VERSION "BodyCAN"

NS_ :

BS_:

BU_: CCM CEM DDM ETC ILCM PDM POT RLDM RRDM SMD SMP TRM Vector_XXX

BO_ 112 RldmBodyFr01: 8 RLDM
 SG_ ChdLockLeftSts : 6|2@0+ (1,0) [0|3] ""  CEM,DDM
 SG_ ChdLockLeftSts_UB : 7|1@0+ (1,0) [0|1] ""  CEM,DDM
 SG_ DoorLeReCinhIntFailInf_UB : 33|1@0+ (1,0) [0|1] ""  CEM
 SG_ DoorLeReCinhIntFailInfCinchFlt1 : 35|1@0+ (1,0) [0|1] ""  CEM
 SG_ DoorLeReCinhIntFailInfCinchRestF : 34|1@0+ (1,0) [0|1] ""  CEM
 SG_ DoorLeReHndlHMISts_UB : 48|1@0+ (1,0) [0|1] ""  CEM
 SG_ DoorLeReHndlHMIStsDeployedOverTm : 63|1@0+ (1,0) [0|1] ""  CEM
 SG_ DoorLeReHndlHMIStsReserved1 : 62|1@0+ (1,0) [0|1] ""  CEM
 SG_ DoorLeReHndlHMIStsRetractOverTmd : 61|1@0+ (1,0) [0|1] ""  CEM
 SG_ DoorLeReHndlHMIStsUnsScsHallSnsr : 60|1@0+ (1,0) [0|1] ""  CEM
 SG_ DoorLeReHndlSts : 2|3@0+ (1,0) [0|7] ""  CEM
 SG_ DoorLeReHndlSts_UB : 26|1@0+ (1,0) [0|1] ""  CEM
 SG_ DoorLeReLatPawlSt : 43|2@0+ (1,0) [0|3] ""  CEM
 SG_ DoorLeReLatPawlSt_UB : 55|1@0+ (1,0) [0|1] ""  CEM
 SG_ DoorLeReLatPosn : 37|2@0+ (1,0) [0|3] ""  CEM
 SG_ DoorLeReLatPosn_UB : 24|1@0+ (1,0) [0|1] ""  CEM
 SG_ DoorLeReLockSts : 17|2@0+ (1,0) [0|3] ""  CEM,DDM
 SG_ DoorLeReLockSts_UB : 18|1@0+ (1,0) [0|1] ""  CEM,DDM
 SG_ DoorLeReOpenLowReqOutdSwt1 : 41|2@0+ (1,0) [0|3] ""  CEM
 SG_ DoorLeReOpenLowReqOutdSwt1_UB : 45|1@0+ (1,0) [0|1] ""  CEM
 SG_ DoorLeReOpenReqInsdSwt1 : 39|2@0+ (1,0) [0|3] ""  CEM
 SG_ DoorLeReOpenReqInsdSwt1_UB : 31|1@0+ (1,0) [0|1] ""  CEM
 SG_ DoorLeReRelsFail_UB : 59|1@0+ (1,0) [0|1] ""  CEM
 SG_ DoorLeReRelsFailCinchOverTimed : 58|1@0+ (1,0) [0|1] ""  CEM
 SG_ DoorLeReRelsFailFailure1 : 57|1@0+ (1,0) [0|1] ""  CEM
 SG_ DoorLeReRelsFailMechRels : 56|1@0+ (1,0) [0|1] ""  CEM
 SG_ DoorLeReSwtLockgSts : 14|1@0+ (1,0) [0|1] ""  CEM,DDM
 SG_ DoorLeReSwtLockgSts_UB : 15|1@0+ (1,0) [0|1] ""  CEM,DDM
 SG_ DoorRiRe2Swt1DplyHndl : 54|1@0+ (1,0) [0|1] ""  RRDM
 SG_ DoorRiRe2Swt1DplyHndl_UB : 53|1@0+ (1,0) [0|1] ""  RRDM
 SG_ DoorRiRe2Swt2DplyHndl : 52|1@0+ (1,0) [0|1] ""  RRDM
 SG_ DoorRiRe2Swt2DplyHndl_UB : 51|1@0+ (1,0) [0|1] ""  RRDM
 SG_ PassSeatRemCtrlReDoorLe_UB : 19|1@0+ (1,0) [0|1] ""  SMP
 SG_ PassSeatRemCtrlReDoorLeActrIncSt : 23|2@0+ (1,0) [0|3] ""  SMP
 SG_ PassSeatRemCtrlReDoorLeActrSldSt : 21|2@0+ (1,0) [0|3] ""  SMP
 SG_ ShortDropWinReLeSts : 47|2@0+ (1,0) [0|3] ""  CEM
 SG_ ShortDropWinReLeSts_UB : 32|1@0+ (1,0) [0|1] ""  CEM
 SG_ WinDsblLeftSts : 3|1@0+ (1,0) [0|1] ""  DDM
 SG_ WinDsblLeftSts_UB : 4|1@0+ (1,0) [0|1] ""  DDM
 SG_ WinFailrStsAtReLe : 27|1@0+ (1,0) [0|1] ""  CEM
 SG_ WinFailrStsAtReLe_UB : 25|1@0+ (1,0) [0|1] ""  CEM
 SG_ WinPosnStsAtReLe : 12|5@0+ (1,0) [0|31] ""  CCM,CEM
 SG_ WinPosnStsAtReLe_UB : 13|1@0+ (1,0) [0|1] ""  CCM,CEM
 SG_ WinPosReqReRi : 30|3@0+ (1,0) [0|7] ""  RRDM
 SG_ WinPosReqReRi_UB : 44|1@0+ (1,0) [0|1] ""  RRDM

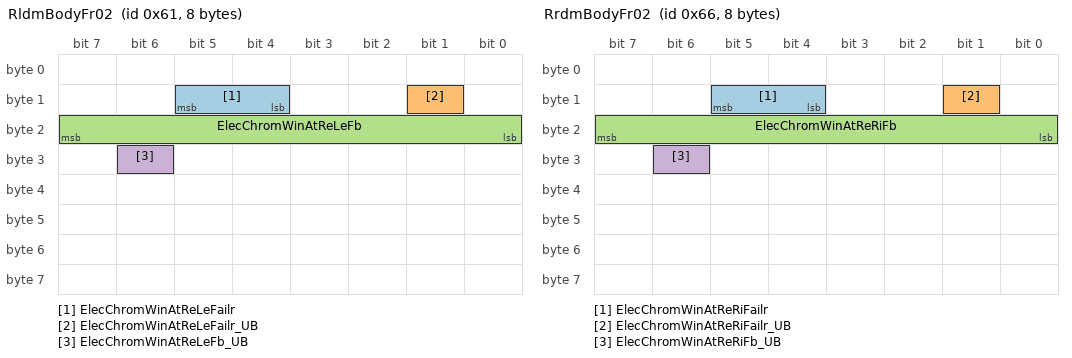
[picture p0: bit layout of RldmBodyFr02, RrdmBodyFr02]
BO_ 97 RldmBodyFr02: 8 RLDM
 SG_ ElecChromWinAtReLeFailr : 13|2@0+ (1,0) [0|3] ""  CEM
 SG_ ElecChromWinAtReLeFailr_UB : 9|1@0+ (1,0) [0|1] ""  CEM
 SG_ ElecChromWinAtReLeFb : 23|8@0+ (1,0) [0|100] "%"  CEM
 SG_ ElecChromWinAtReLeFb_UB : 30|1@0+ (1,0) [0|1] ""  CEM

BO_ 1289 RldmBodyNMFr01: 8 RLDM
 SG_ PNC16_RLDM : 16|1@0+ (1,0) [0|0] ""  POT
 SG_ PNC17_RLDM : 17|1@0+ (1,0) [0|0] ""  POT
 SG_ PNC18_RLDM : 18|1@0+ (1,0) [0|0] ""  POT
 SG_ PNC19_RLDM : 19|1@0+ (1,0) [0|0] ""  POT
 SG_ PNC20_RLDM : 20|1@0+ (1,0) [0|0] ""  POT
 SG_ PNC21_RLDM : 21|1@0+ (1,0) [0|0] ""  POT
 SG_ PNC22_RLDM : 22|1@0+ (1,0) [0|0] ""  POT
 SG_ PNC23_RLDM : 23|1@0+ (1,0) [0|0] ""  POT
 SG_ PNC24_RLDM : 24|1@0+ (1,0) [0|0] ""  POT
 SG_ PNC25_RLDM : 25|1@0+ (1,0) [0|0] ""  POT
 SG_ PNC26_RLDM : 26|1@0+ (1,0) [0|0] ""  POT
 SG_ PNC27_RLDM : 27|1@0+ (1,0) [0|0] ""  POT
 SG_ PNC28_RLDM : 28|1@0+ (1,0) [0|0] ""  POT
 SG_ PNC29_RLDM : 29|1@0+ (1,0) [0|0] ""  POT
 SG_ PNC30_RLDM : 30|1@0+ (1,0) [0|0] ""  POT
 SG_ PNC31_RLDM : 31|1@0+ (1,0) [0|0] ""  POT
 SG_ PNC32_RLDM : 32|1@0+ (1,0) [0|0] ""  POT
 SG_ PNC33_RLDM : 33|1@0+ (1,0) [0|0] ""  POT
 SG_ PNC34_RLDM : 34|1@0+ (1,0) [0|0] ""  POT
 SG_ PNC35_RLDM : 35|1@0+ (1,0) [0|0] ""  POT
 SG_ PNC36_RLDM : 36|1@0+ (1,0) [0|0] ""  POT
 SG_ PNC37_RLDM : 37|1@0+ (1,0) [0|0] ""  POT
 SG_ PNC38_RLDM : 38|1@0+ (1,0) [0|0] ""  POT
 SG_ PNC39_RLDM : 39|1@0+ (1,0) [0|0] ""  POT
 SG_ PNC40_RLDM : 40|1@0+ (1,0) [0|0] ""  POT
 SG_ PNC41_RLDM : 41|1@0+ (1,0) [0|0] ""  POT
 SG_ PNC42_RLDM : 42|1@0+ (1,0) [0|0] ""  POT
 SG_ NM_PNI_RLDM : 14|1@0+ (1,0) [0|0] ""  POT
 SG_ NM_AW_RLDM : 12|1@0+ (1,0) [0|0] ""  POT
 SG_ NM_CS_RLDM : 11|1@0+ (1,0) [0|0] ""  POT
 SG_ NM_RMR_RLDM : 8|1@0+ (1,0) [0|0] ""  POT
 SG_ NM_NodeID_RLDM : 7|8@0+ (1,0) [0|0] ""  POT

BO_ 1353 RldmBodyVFCVectorFr: 8 RLDM
 SG_ VFCVectorRLDMBlockID : 1|2@0+ (1,0) [0|3] "Unitless"  ETC
 SG_ VFCVectorRLDMVFCid0 : 2|1@0+ (1,0) [0|1] ""  ETC
 SG_ VFCVectorRLDMVFCid1 : 3|1@0+ (1,0) [0|1] ""  ETC
 SG_ VFCVectorRLDMVFCid10 : 12|1@0+ (1,0) [0|1] ""  ETC
 SG_ VFCVectorRLDMVFCid11 : 13|1@0+ (1,0) [0|1] ""  ETC
 SG_ VFCVectorRLDMVFCid12 : 14|1@0+ (1,0) [0|1] ""  ETC
 SG_ VFCVectorRLDMVFCid13 : 15|1@0+ (1,0) [0|1] ""  ETC
 SG_ VFCVectorRLDMVFCid14 : 16|1@0+ (1,0) [0|1] ""  ETC
 SG_ VFCVectorRLDMVFCid15 : 17|1@0+ (1,0) [0|1] ""  ETC
 SG_ VFCVectorRLDMVFCid16 : 18|1@0+ (1,0) [0|1] ""  ETC
 SG_ VFCVectorRLDMVFCid17 : 19|1@0+ (1,0) [0|1] ""  ETC
 SG_ VFCVectorRLDMVFCid18 : 20|1@0+ (1,0) [0|1] ""  ETC
 SG_ VFCVectorRLDMVFCid19 : 21|1@0+ (1,0) [0|1] ""  ETC
 SG_ VFCVectorRLDMVFCid2 : 4|1@0+ (1,0) [0|1] ""  ETC
 SG_ VFCVectorRLDMVFCid20 : 22|1@0+ (1,0) [0|1] ""  ETC
 SG_ VFCVectorRLDMVFCid21 : 23|1@0+ (1,0) [0|1] ""  ETC
 SG_ VFCVectorRLDMVFCid22 : 24|1@0+ (1,0) [0|1] ""  ETC
 SG_ VFCVectorRLDMVFCid23 : 25|1@0+ (1,0) [0|1] ""  ETC
 SG_ VFCVectorRLDMVFCid24 : 26|1@0+ (1,0) [0|1] ""  ETC
 SG_ VFCVectorRLDMVFCid25 : 27|1@0+ (1,0) [0|1] ""  ETC
 SG_ VFCVectorRLDMVFCid26 : 28|1@0+ (1,0) [0|1] ""  ETC
 SG_ VFCVectorRLDMVFCid27 : 29|1@0+ (1,0) [0|1] ""  ETC
 SG_ VFCVectorRLDMVFCid28 : 30|1@0+ (1,0) [0|1] ""  ETC
 SG_ VFCVectorRLDMVFCid29 : 31|1@0+ (1,0) [0|1] ""  ETC
 SG_ VFCVectorRLDMVFCid3 : 5|1@0+ (1,0) [0|1] ""  ETC
 SG_ VFCVectorRLDMVFCid30 : 32|1@0+ (1,0) [0|1] ""  ETC
 SG_ VFCVectorRLDMVFCid31 : 33|1@0+ (1,0) [0|1] ""  ETC
 SG_ VFCVectorRLDMVFCid32 : 34|1@0+ (1,0) [0|1] ""  ETC
 SG_ VFCVectorRLDMVFCid33 : 35|1@0+ (1,0) [0|1] ""  ETC
 SG_ VFCVectorRLDMVFCid34 : 36|1@0+ (1,0) [0|1] ""  ETC
 SG_ VFCVectorRLDMVFCid35 : 37|1@0+ (1,0) [0|1] ""  ETC
 SG_ VFCVectorRLDMVFCid36 : 38|1@0+ (1,0) [0|1] ""  ETC
 SG_ VFCVectorRLDMVFCid37 : 39|1@0+ (1,0) [0|1] ""  ETC
 SG_ VFCVectorRLDMVFCid38 : 40|1@0+ (1,0) [0|1] ""  ETC
 SG_ VFCVectorRLDMVFCid39 : 41|1@0+ (1,0) [0|1] ""  ETC
 SG_ VFCVectorRLDMVFCid4 : 6|1@0+ (1,0) [0|1] ""  ETC
 SG_ VFCVectorRLDMVFCid40 : 42|1@0+ (1,0) [0|1] ""  ETC
 SG_ VFCVectorRLDMVFCid41 : 43|1@0+ (1,0) [0|1] ""  ETC
 SG_ VFCVectorRLDMVFCid42 : 44|1@0+ (1,0) [0|1] ""  ETC
 SG_ VFCVectorRLDMVFCid43 : 45|1@0+ (1,0) [0|1] ""  ETC
 SG_ VFCVectorRLDMVFCid44 : 46|1@0+ (1,0) [0|1] ""  ETC
 SG_ VFCVectorRLDMVFCid45 : 47|1@0+ (1,0) [0|1] ""  ETC
 SG_ VFCVectorRLDMVFCid46 : 48|1@0+ (1,0) [0|1] ""  ETC
 SG_ VFCVectorRLDMVFCid47 : 49|1@0+ (1,0) [0|1] ""  ETC
 SG_ VFCVectorRLDMVFCid48 : 50|1@0+ (1,0) [0|1] ""  ETC
 SG_ VFCVectorRLDMVFCid49 : 51|1@0+ (1,0) [0|1] ""  ETC
 SG_ VFCVectorRLDMVFCid5 : 7|1@0+ (1,0) [0|1] ""  ETC
 SG_ VFCVectorRLDMVFCid50 : 52|1@0+ (1,0) [0|1] ""  ETC
 SG_ VFCVectorRLDMVFCid51 : 53|1@0+ (1,0) [0|1] ""  ETC
 SG_ VFCVectorRLDMVFCid52 : 54|1@0+ (1,0) [0|1] ""  ETC
 SG_ VFCVectorRLDMVFCid53 : 55|1@0+ (1,0) [0|1] ""  ETC
 SG_ VFCVectorRLDMVFCid54 : 56|1@0+ (1,0) [0|1] ""  ETC
 SG_ VFCVectorRLDMVFCid55 : 57|1@0+ (1,0) [0|1] ""  ETC
 SG_ VFCVectorRLDMVFCid56 : 58|1@0+ (1,0) [0|1] ""  ETC
 SG_ VFCVectorRLDMVFCid57 : 59|1@0+ (1,0) [0|1] ""  ETC
 SG_ VFCVectorRLDMVFCid58 : 60|1@0+ (1,0) [0|1] ""  ETC
 SG_ VFCVectorRLDMVFCid59 : 61|1@0+ (1,0) [0|1] ""  ETC
 SG_ VFCVectorRLDMVFCid6 : 8|1@0+ (1,0) [0|1] ""  ETC
 SG_ VFCVectorRLDMVFCid60 : 62|1@0+ (1,0) [0|1] ""  ETC
 SG_ VFCVectorRLDMVFCid61 : 63|1@0+ (1,0) [0|1] ""  ETC
 SG_ VFCVectorRLDMVFCid7 : 9|1@0+ (1,0) [0|1] ""  ETC
 SG_ VFCVectorRLDMVFCid8 : 10|1@0+ (1,0) [0|1] ""  ETC
 SG_ VFCVectorRLDMVFCid9 : 11|1@0+ (1,0) [0|1] ""  ETC

BO_ 1569 RldmToCemBodyDiagResFrame: 8 RLDM
 SG_ RldmToCemBodyDiagResNpdu : 7|64@0+ (1,0) [0|0] ""  CEM

BO_ 1418 RldmToEtcXCPFr01: 8 RLDM

BO_ 117 RrdmBodyFr01: 8 RRDM
 SG_ ChdLockRightSts : 6|2@0+ (1,0) [0|3] ""  CEM,DDM
 SG_ ChdLockRightSts_UB : 7|1@0+ (1,0) [0|1] ""  CEM,DDM
 SG_ DoorLeRe2Swt1DplyHndl : 54|1@0+ (1,0) [0|1] ""  RLDM
 SG_ DoorLeRe2Swt1DplyHndl_UB : 53|1@0+ (1,0) [0|1] ""  RLDM
 SG_ DoorLeRe2Swt2DplyHndl : 52|1@0+ (1,0) [0|1] ""  RLDM
 SG_ DoorLeRe2Swt2DplyHndl_UB : 51|1@0+ (1,0) [0|1] ""  RLDM
 SG_ DoorRiReCinhIntFailInf_UB : 33|1@0+ (1,0) [0|1] ""  CEM
 SG_ DoorRiReCinhIntFailInfCinchFlt1 : 35|1@0+ (1,0) [0|1] ""  CEM
 SG_ DoorRiReCinhIntFailInfCinchRestF : 34|1@0+ (1,0) [0|1] ""  CEM
 SG_ DoorRiReHndlHMISts_UB : 48|1@0+ (1,0) [0|1] ""  CEM
 SG_ DoorRiReHndlHMIStsDeployedOverTm : 63|1@0+ (1,0) [0|1] ""  CEM
 SG_ DoorRiReHndlHMIStsReserved1 : 62|1@0+ (1,0) [0|1] ""  CEM
 SG_ DoorRiReHndlHMIStsRetractOverTmd : 61|1@0+ (1,0) [0|1] ""  CEM
 SG_ DoorRiReHndlHMIStsUnsScsHallSnsr : 60|1@0+ (1,0) [0|1] ""  CEM
 SG_ DoorRiReHndlSts : 2|3@0+ (1,0) [0|7] ""  CEM
 SG_ DoorRiReHndlSts_UB : 26|1@0+ (1,0) [0|1] ""  CEM
 SG_ DoorRiReLatPawlSt : 41|2@0+ (1,0) [0|3] ""  CEM
 SG_ DoorRiReLatPawlSt_UB : 55|1@0+ (1,0) [0|1] ""  CEM
 SG_ DoorRiReLatPosn : 37|2@0+ (1,0) [0|3] ""  CEM
 SG_ DoorRiReLatPosn_UB : 24|1@0+ (1,0) [0|1] ""  CEM
 SG_ DoorRiReLockSts : 17|2@0+ (1,0) [0|3] ""  CEM,PDM
 SG_ DoorRiReLockSts_UB : 18|1@0+ (1,0) [0|1] ""  CEM,PDM
 SG_ DoorRiReOpenLowReqOutdSwt1 : 45|2@0+ (1,0) [0|3] ""  CEM
 SG_ DoorRiReOpenLowReqOutdSwt1_UB : 43|1@0+ (1,0) [0|1] ""  CEM
 SG_ DoorRiReOpenReqInsdSwt1 : 39|2@0+ (1,0) [0|3] ""  CEM
 SG_ DoorRiReOpenReqInsdSwt1_UB : 42|1@0+ (1,0) [0|1] ""  CEM
 SG_ DoorRiReRelsFail_UB : 59|1@0+ (1,0) [0|1] ""  CEM
 SG_ DoorRiReRelsFailCinchOverTimed : 58|1@0+ (1,0) [0|1] ""  CEM
 SG_ DoorRiReRelsFailFailure1 : 57|1@0+ (1,0) [0|1] ""  CEM
 SG_ DoorRiReRelsFailMechRels : 56|1@0+ (1,0) [0|1] ""  CEM
 SG_ DoorRiReSwtLockgSts : 14|1@0+ (1,0) [0|1] ""  CEM,PDM
 SG_ DoorRiReSwtLockgSts_UB : 15|1@0+ (1,0) [0|1] ""  CEM,PDM
 SG_ PassSeatRemCtrlReDoorRi_UB : 19|1@0+ (1,0) [0|1] ""  SMP
 SG_ PassSeatRemCtrlReDoorRiActrIncSt : 23|2@0+ (1,0) [0|3] ""  SMP
 SG_ PassSeatRemCtrlReDoorRiActrSldSt : 21|2@0+ (1,0) [0|3] ""  SMP
 SG_ ShortDropWinReRiSts : 47|2@0+ (1,0) [0|3] ""  CEM
 SG_ ShortDropWinReRiSts_UB : 32|1@0+ (1,0) [0|1] ""  CEM
 SG_ WinDsblRightSts : 3|1@0+ (1,0) [0|1] ""  DDM
 SG_ WinDsblRightSts_UB : 4|1@0+ (1,0) [0|1] ""  DDM
 SG_ WinFailrStsAtReRi : 31|1@0+ (1,0) [0|1] ""  CEM
 SG_ WinFailrStsAtReRi_UB : 30|1@0+ (1,0) [0|1] ""  CEM
 SG_ WinPosnStsAtReRi : 12|5@0+ (1,0) [0|31] ""  CCM,CEM
 SG_ WinPosnStsAtReRi_UB : 13|1@0+ (1,0) [0|1] ""  CCM,CEM
 SG_ WinPosReqReLe : 29|3@0+ (1,0) [0|7] ""  RLDM
 SG_ WinPosReqReLe_UB : 25|1@0+ (1,0) [0|1] ""  RLDM

BO_ 102 RrdmBodyFr02: 8 RRDM
 SG_ ElecChromWinAtReRiFailr : 13|2@0+ (1,0) [0|3] ""  CEM
 SG_ ElecChromWinAtReRiFailr_UB : 9|1@0+ (1,0) [0|1] ""  CEM
 SG_ ElecChromWinAtReRiFb : 23|8@0+ (1,0) [0|100] "%"  CEM
 SG_ ElecChromWinAtReRiFb_UB : 30|1@0+ (1,0) [0|1] ""  CEM

BO_ 1296 RrdmBodyNMFr01: 8 RRDM
 SG_ PNC16_RRDM : 16|1@0+ (1,0) [0|0] ""  RLDM
 SG_ PNC17_RRDM : 17|1@0+ (1,0) [0|0] ""  RLDM
 SG_ PNC18_RRDM : 18|1@0+ (1,0) [0|0] ""  RLDM
 SG_ PNC19_RRDM : 19|1@0+ (1,0) [0|0] ""  RLDM
 SG_ PNC20_RRDM : 20|1@0+ (1,0) [0|0] ""  RLDM
 SG_ PNC21_RRDM : 21|1@0+ (1,0) [0|0] ""  RLDM
 SG_ PNC22_RRDM : 22|1@0+ (1,0) [0|0] ""  RLDM
 SG_ PNC23_RRDM : 23|1@0+ (1,0) [0|0] ""  RLDM
 SG_ PNC24_RRDM : 24|1@0+ (1,0) [0|0] ""  RLDM
 SG_ PNC25_RRDM : 25|1@0+ (1,0) [0|0] ""  RLDM
 SG_ PNC26_RRDM : 26|1@0+ (1,0) [0|0] ""  RLDM
 SG_ PNC27_RRDM : 27|1@0+ (1,0) [0|0] ""  RLDM
 SG_ PNC28_RRDM : 28|1@0+ (1,0) [0|0] ""  RLDM
 SG_ PNC29_RRDM : 29|1@0+ (1,0) [0|0] ""  RLDM
 SG_ PNC30_RRDM : 30|1@0+ (1,0) [0|0] ""  RLDM
 SG_ PNC31_RRDM : 31|1@0+ (1,0) [0|0] ""  RLDM
 SG_ PNC32_RRDM : 32|1@0+ (1,0) [0|0] ""  RLDM
 SG_ PNC33_RRDM : 33|1@0+ (1,0) [0|0] ""  RLDM
 SG_ PNC34_RRDM : 34|1@0+ (1,0) [0|0] ""  RLDM
 SG_ PNC35_RRDM : 35|1@0+ (1,0) [0|0] ""  RLDM
 SG_ PNC36_RRDM : 36|1@0+ (1,0) [0|0] ""  RLDM
 SG_ PNC37_RRDM : 37|1@0+ (1,0) [0|0] ""  RLDM
 SG_ PNC38_RRDM : 38|1@0+ (1,0) [0|0] ""  RLDM
 SG_ PNC39_RRDM : 39|1@0+ (1,0) [0|0] ""  RLDM
 SG_ PNC40_RRDM : 40|1@0+ (1,0) [0|0] ""  RLDM
 SG_ PNC41_RRDM : 41|1@0+ (1,0) [0|0] ""  RLDM
 SG_ PNC42_RRDM : 42|1@0+ (1,0) [0|0] ""  RLDM
 SG_ NM_PNI_RRDM : 14|1@0+ (1,0) [0|0] ""  RLDM
 SG_ NM_AW_RRDM : 12|1@0+ (1,0) [0|0] ""  RLDM
 SG_ NM_CS_RRDM : 11|1@0+ (1,0) [0|0] ""  RLDM
 SG_ NM_RMR_RRDM : 8|1@0+ (1,0) [0|0] ""  RLDM
 SG_ NM_NodeID_RRDM : 7|8@0+ (1,0) [0|0] ""  RLDM

BO_ 1360 RrdmBodyVFCVectorFr: 8 RRDM
 SG_ VFCVectorRRDMBlockID : 1|2@0+ (1,0) [0|3] "Unitless"  ETC
 SG_ VFCVectorRRDMVFCid0 : 2|1@0+ (1,0) [0|1] ""  ETC
 SG_ VFCVectorRRDMVFCid1 : 3|1@0+ (1,0) [0|1] ""  ETC
 SG_ VFCVectorRRDMVFCid10 : 12|1@0+ (1,0) [0|1] ""  ETC
 SG_ VFCVectorRRDMVFCid11 : 13|1@0+ (1,0) [0|1] ""  ETC
 SG_ VFCVectorRRDMVFCid12 : 14|1@0+ (1,0) [0|1] ""  ETC
 SG_ VFCVectorRRDMVFCid13 : 15|1@0+ (1,0) [0|1] ""  ETC
 SG_ VFCVectorRRDMVFCid14 : 16|1@0+ (1,0) [0|1] ""  ETC
 SG_ VFCVectorRRDMVFCid15 : 17|1@0+ (1,0) [0|1] ""  ETC
 SG_ VFCVectorRRDMVFCid16 : 18|1@0+ (1,0) [0|1] ""  ETC
 SG_ VFCVectorRRDMVFCid17 : 19|1@0+ (1,0) [0|1] ""  ETC
 SG_ VFCVectorRRDMVFCid18 : 20|1@0+ (1,0) [0|1] ""  ETC
 SG_ VFCVectorRRDMVFCid19 : 21|1@0+ (1,0) [0|1] ""  ETC
 SG_ VFCVectorRRDMVFCid2 : 4|1@0+ (1,0) [0|1] ""  ETC
 SG_ VFCVectorRRDMVFCid20 : 22|1@0+ (1,0) [0|1] ""  ETC
 SG_ VFCVectorRRDMVFCid21 : 23|1@0+ (1,0) [0|1] ""  ETC
 SG_ VFCVectorRRDMVFCid22 : 24|1@0+ (1,0) [0|1] ""  ETC
 SG_ VFCVectorRRDMVFCid23 : 25|1@0+ (1,0) [0|1] ""  ETC
 SG_ VFCVectorRRDMVFCid24 : 26|1@0+ (1,0) [0|1] ""  ETC
 SG_ VFCVectorRRDMVFCid25 : 27|1@0+ (1,0) [0|1] ""  ETC
 SG_ VFCVectorRRDMVFCid26 : 28|1@0+ (1,0) [0|1] ""  ETC
 SG_ VFCVectorRRDMVFCid27 : 29|1@0+ (1,0) [0|1] ""  ETC
 SG_ VFCVectorRRDMVFCid28 : 30|1@0+ (1,0) [0|1] ""  ETC
 SG_ VFCVectorRRDMVFCid29 : 31|1@0+ (1,0) [0|1] ""  ETC
 SG_ VFCVectorRRDMVFCid3 : 5|1@0+ (1,0) [0|1] ""  ETC
 SG_ VFCVectorRRDMVFCid30 : 32|1@0+ (1,0) [0|1] ""  ETC
 SG_ VFCVectorRRDMVFCid31 : 33|1@0+ (1,0) [0|1] ""  ETC
 SG_ VFCVectorRRDMVFCid32 : 34|1@0+ (1,0) [0|1] ""  ETC
 SG_ VFCVectorRRDMVFCid33 : 35|1@0+ (1,0) [0|1] ""  ETC
 SG_ VFCVectorRRDMVFCid34 : 36|1@0+ (1,0) [0|1] ""  ETC
 SG_ VFCVectorRRDMVFCid35 : 37|1@0+ (1,0) [0|1] ""  ETC
 SG_ VFCVectorRRDMVFCid36 : 38|1@0+ (1,0) [0|1] ""  ETC
 SG_ VFCVectorRRDMVFCid37 : 39|1@0+ (1,0) [0|1] ""  ETC
 SG_ VFCVectorRRDMVFCid38 : 40|1@0+ (1,0) [0|1] ""  ETC
 SG_ VFCVectorRRDMVFCid39 : 41|1@0+ (1,0) [0|1] ""  ETC
 SG_ VFCVectorRRDMVFCid4 : 6|1@0+ (1,0) [0|1] ""  ETC
 SG_ VFCVectorRRDMVFCid40 : 42|1@0+ (1,0) [0|1] ""  ETC
 SG_ VFCVectorRRDMVFCid41 : 43|1@0+ (1,0) [0|1] ""  ETC
 SG_ VFCVectorRRDMVFCid42 : 44|1@0+ (1,0) [0|1] ""  ETC
 SG_ VFCVectorRRDMVFCid43 : 45|1@0+ (1,0) [0|1] ""  ETC
 SG_ VFCVectorRRDMVFCid44 : 46|1@0+ (1,0) [0|1] ""  ETC
 SG_ VFCVectorRRDMVFCid45 : 47|1@0+ (1,0) [0|1] ""  ETC
 SG_ VFCVectorRRDMVFCid46 : 48|1@0+ (1,0) [0|1] ""  ETC
 SG_ VFCVectorRRDMVFCid47 : 49|1@0+ (1,0) [0|1] ""  ETC
 SG_ VFCVectorRRDMVFCid48 : 50|1@0+ (1,0) [0|1] ""  ETC
 SG_ VFCVectorRRDMVFCid49 : 51|1@0+ (1,0) [0|1] ""  ETC
 SG_ VFCVectorRRDMVFCid5 : 7|1@0+ (1,0) [0|1] ""  ETC
 SG_ VFCVectorRRDMVFCid50 : 52|1@0+ (1,0) [0|1] ""  ETC
 SG_ VFCVectorRRDMVFCid51 : 53|1@0+ (1,0) [0|1] ""  ETC
 SG_ VFCVectorRRDMVFCid52 : 54|1@0+ (1,0) [0|1] ""  ETC
 SG_ VFCVectorRRDMVFCid53 : 55|1@0+ (1,0) [0|1] ""  ETC
 SG_ VFCVectorRRDMVFCid54 : 56|1@0+ (1,0) [0|1] ""  ETC
 SG_ VFCVectorRRDMVFCid55 : 57|1@0+ (1,0) [0|1] ""  ETC
 SG_ VFCVectorRRDMVFCid56 : 58|1@0+ (1,0) [0|1] ""  ETC
 SG_ VFCVectorRRDMVFCid57 : 59|1@0+ (1,0) [0|1] ""  ETC
 SG_ VFCVectorRRDMVFCid58 : 60|1@0+ (1,0) [0|1] ""  ETC
 SG_ VFCVectorRRDMVFCid59 : 61|1@0+ (1,0) [0|1] ""  ETC
 SG_ VFCVectorRRDMVFCid6 : 8|1@0+ (1,0) [0|1] ""  ETC
 SG_ VFCVectorRRDMVFCid60 : 62|1@0+ (1,0) [0|1] ""  ETC
 SG_ VFCVectorRRDMVFCid61 : 63|1@0+ (1,0) [0|1] ""  ETC
 SG_ VFCVectorRRDMVFCid7 : 9|1@0+ (1,0) [0|1] ""  ETC
 SG_ VFCVectorRRDMVFCid8 : 10|1@0+ (1,0) [0|1] ""  ETC
 SG_ VFCVectorRRDMVFCid9 : 11|1@0+ (1,0) [0|1] ""  ETC

BO_ 1570 RrdmToCemBodyDiagResFrame: 8 RRDM
 SG_ RrdmToCemBodyDiagResNpdu : 7|64@0+ (1,0) [0|0] ""  CEM

BO_ 1419 RrdmToEtcXCPFr01: 8 RRDM

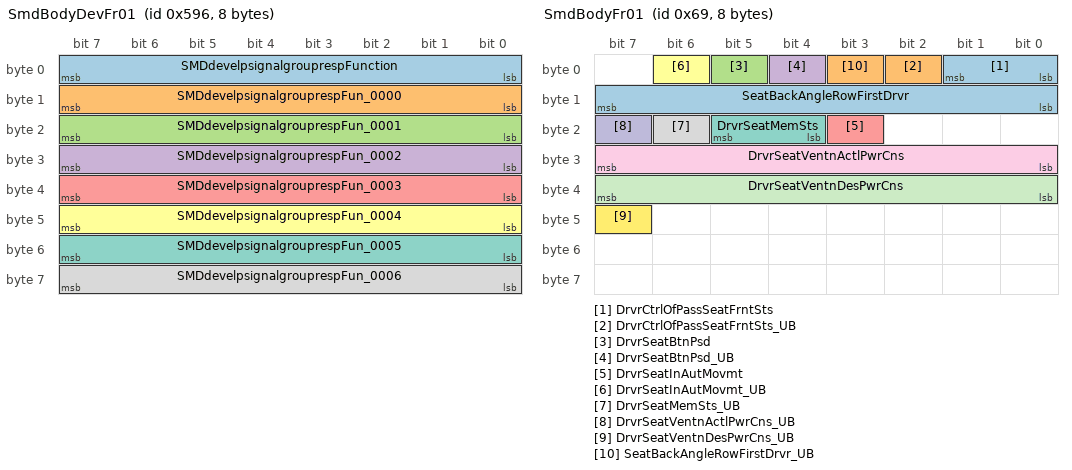
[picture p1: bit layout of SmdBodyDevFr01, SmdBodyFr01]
BO_ 1430 SmdBodyDevFr01: 8 SMD
 SG_ SMDdevelpsignalgrouprespFunction : 7|8@0+ (1,0) [0|255] "Unitless"  ETC
 SG_ SMDdevelpsignalgrouprespFun_0000 : 15|8@0+ (1,0) [0|255] "Unitless"  ETC
 SG_ SMDdevelpsignalgrouprespFun_0001 : 23|8@0+ (1,0) [0|255] "Unitless"  ETC
 SG_ SMDdevelpsignalgrouprespFun_0002 : 31|8@0+ (1,0) [0|255] "Unitless"  ETC
 SG_ SMDdevelpsignalgrouprespFun_0003 : 39|8@0+ (1,0) [0|255] "Unitless"  ETC
 SG_ SMDdevelpsignalgrouprespFun_0004 : 47|8@0+ (1,0) [0|255] "Unitless"  ETC
 SG_ SMDdevelpsignalgrouprespFun_0005 : 55|8@0+ (1,0) [0|255] "Unitless"  ETC
 SG_ SMDdevelpsignalgrouprespFun_0006 : 63|8@0+ (1,0) [0|255] "Unitless"  ETC

BO_ 105 SmdBodyFr01: 8 SMD
 SG_ DrvrCtrlOfPassSeatFrntSts : 1|2@0+ (1,0) [0|3] ""  CEM,SMP
 SG_ DrvrCtrlOfPassSeatFrntSts_UB : 2|1@0+ (1,0) [0|1] ""  CEM,SMP
 SG_ DrvrSeatBtnPsd : 5|1@0+ (1,0) [0|1] ""  CEM
 SG_ DrvrSeatBtnPsd_UB : 4|1@0+ (1,0) [0|1] ""  CEM
 SG_ DrvrSeatInAutMovmt : 19|1@0+ (1,0) [0|1] ""  CEM
 SG_ DrvrSeatInAutMovmt_UB : 6|1@0+ (1,0) [0|1] ""  CEM
 SG_ DrvrSeatMemSts : 21|2@0+ (1,0) [0|3] ""  CEM
 SG_ DrvrSeatMemSts_UB : 22|1@0+ (1,0) [0|1] ""  CEM
 SG_ DrvrSeatVentnActlPwrCns : 31|8@0+ (1,0) [0|255] "Unitless"  CCM,CEM
 SG_ DrvrSeatVentnActlPwrCns_UB : 23|1@0+ (1,0) [0|1] ""  CCM,CEM
 SG_ DrvrSeatVentnDesPwrCns : 39|8@0+ (1,0) [0|255] "Unitless"  CCM,CEM
 SG_ DrvrSeatVentnDesPwrCns_UB : 47|1@0+ (1,0) [0|1] ""  CCM,CEM
 SG_ SeatBackAngleRowFirstDrvr : 15|8@0+ (1,0) [0|180] "Deg"  CEM
 SG_ SeatBackAngleRowFirstDrvr_UB : 3|1@0+ (1,0) [0|1] ""  CEM

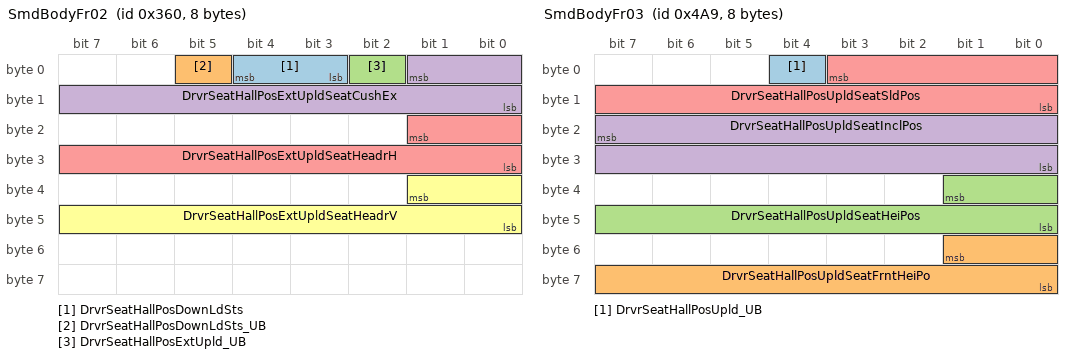
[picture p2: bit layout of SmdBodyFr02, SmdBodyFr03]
BO_ 864 SmdBodyFr02: 8 SMD
 SG_ DrvrSeatHallPosDownLdSts : 4|2@0+ (1,0) [0|3] ""  CEM
 SG_ DrvrSeatHallPosDownLdSts_UB : 5|1@0+ (1,0) [0|1] ""  CEM
 SG_ DrvrSeatHallPosExtUpld_UB : 2|1@0+ (1,0) [0|1] ""  CEM
 SG_ DrvrSeatHallPosExtUpldSeatCushEx : 1|10@0+ (1,0) [0|1023] "Unitless"  CEM
 SG_ DrvrSeatHallPosExtUpldSeatHeadrH : 17|10@0+ (1,0) [0|1023] "Unitless"  CEM
 SG_ DrvrSeatHallPosExtUpldSeatHeadrV : 33|10@0+ (1,0) [0|1023] "Unitless"  CEM

BO_ 1193 SmdBodyFr03: 8 SMD
 SG_ DrvrSeatHallPosUpld_UB : 4|1@0+ (1,0) [0|1] ""  CEM
 SG_ DrvrSeatHallPosUpldSeatFrntHeiPo : 49|10@0+ (1,0) [0|1023] "Unitless"  CEM
 SG_ DrvrSeatHallPosUpldSeatHeiPos : 33|10@0+ (1,0) [0|1023] "Unitless"  CEM
 SG_ DrvrSeatHallPosUpldSeatInclPos : 23|16@0+ (1,0) [0|65535] "Unitless"  CEM
 SG_ DrvrSeatHallPosUpldSeatSldPos : 3|12@0+ (1,0) [0|4095] "Unitless"  CEM

BO_ 665 SmdBodyFr04: 8 SMD
 SG_ DrvrMassgRunng : 39|1@0+ (1,0) [0|1] ""  CEM
 SG_ DrvrMassgRunng_UB : 43|1@0+ (1,0) [0|1] ""  CEM
 SG_ DrvrSeatActvSpplFct : 47|3@0+ (1,0) [0|7] ""  CEM
 SG_ DrvrSeatActvSpplFct_UB : 44|1@0+ (1,0) [0|1] ""  CEM
 SG_ DrvrSeatHeatgActlPwrCns : 15|8@0+ (1,0) [0|255] "Unitless"  CCM,CEM
 SG_ DrvrSeatHeatgActlPwrCns_UB : 30|1@0+ (1,0) [0|1] ""  CCM,CEM
 SG_ DrvrSeatHeatgAvlSts : 2|3@0+ (1,0) [0|7] ""  CCM,CEM
 SG_ DrvrSeatHeatgAvlSts_UB : 3|1@0+ (1,0) [0|1] ""  CCM,CEM
 SG_ DrvrSeatHeatgDesPwrCns : 23|8@0+ (1,0) [0|255] "Unitless"  CCM,CEM
 SG_ DrvrSeatHeatgDesPwrCns_UB : 31|1@0+ (1,0) [0|1] ""  CCM,CEM
 SG_ DrvrSeatHeatgLvlSts : 25|2@0+ (1,0) [0|3] ""  CCM,CEM
 SG_ DrvrSeatHeatgLvlSts_UB : 26|1@0+ (1,0) [0|1] ""  CCM,CEM
 SG_ DrvrSeatMassgFctReq : 38|1@0+ (1,0) [0|1] ""  CEM
 SG_ DrvrSeatMassgFctReq_UB : 37|1@0+ (1,0) [0|1] ""  CEM
 SG_ DrvrSeatSwtSts_UB : 42|1@0+ (1,0) [0|1] ""  CEM,SMP
 SG_ DrvrSeatSwtStsDrvrSeatSwtAdjmtOf : 57|2@0+ (1,0) [0|3] ""  CEM,SMP
 SG_ DrvrSeatSwtStsDrvrSeatSwtAd_0000 : 59|2@0+ (1,0) [0|3] ""  CEM,SMP
 SG_ DrvrSeatSwtStsDrvrSeatSwtHdrstHo : 61|2@0+ (1,0) [0|3] ""  CEM,SMP
 SG_ DrvrSeatSwtStsDrvrSeatSwtHdrstVe : 63|2@0+ (1,0) [0|3] ""  CEM,SMP
 SG_ DrvrSeatSwtStsDrvrSeatSwtHeiFrnt : 49|2@0+ (1,0) [0|3] ""  CEM,SMP
 SG_ DrvrSeatSwtStsDrvrSeatSwtHeiSts : 51|2@0+ (1,0) [0|3] ""  CEM,SMP
 SG_ DrvrSeatSwtStsDrvrSeatSwtInclSts : 53|2@0+ (1,0) [0|3] ""  CEM,SMP
 SG_ DrvrSeatSwtStsDrvrSeatSwtSelnOfS : 55|2@0+ (1,0) [0|3] ""  CEM,SMP
 SG_ DrvrSeatSwtStsDrvrSeatSwtSldSts : 41|2@0+ (1,0) [0|3] ""  CEM,SMP
 SG_ DrvrSeatVentAvlSts : 6|3@0+ (1,0) [0|7] ""  CCM,CEM
 SG_ DrvrSeatVentAvlSts_UB : 7|1@0+ (1,0) [0|1] ""  CCM,CEM
 SG_ DrvrSeatVentnLvlSts : 28|2@0+ (1,0) [0|3] ""  CCM,CEM
 SG_ DrvrSeatVentnLvlSts_UB : 29|1@0+ (1,0) [0|1] ""  CCM,CEM

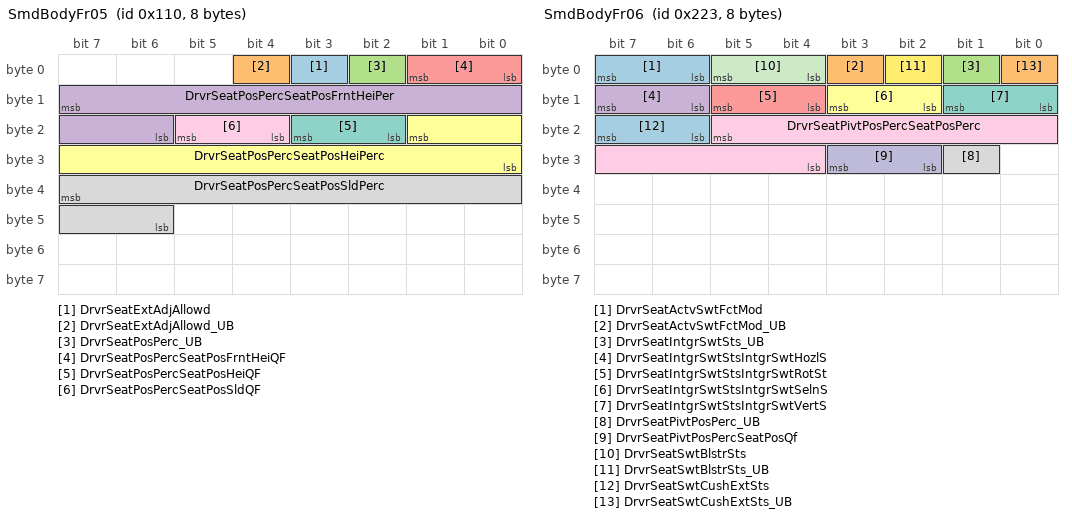
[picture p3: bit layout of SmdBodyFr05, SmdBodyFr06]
BO_ 272 SmdBodyFr05: 8 SMD
 SG_ DrvrSeatExtAdjAllowd : 3|1@0+ (1,0) [0|1] ""  CEM
 SG_ DrvrSeatExtAdjAllowd_UB : 4|1@0+ (1,0) [0|1] ""  CEM
 SG_ DrvrSeatPosPerc_UB : 2|1@0+ (1,0) [0|1] ""  CEM
 SG_ DrvrSeatPosPercSeatPosFrntHeiPer : 15|10@0+ (0.1,0) [0|100] "%"  CEM
 SG_ DrvrSeatPosPercSeatPosFrntHeiQF : 1|2@0+ (1,0) [0|3] ""  CEM
 SG_ DrvrSeatPosPercSeatPosHeiPerc : 17|10@0+ (0.1,0) [0|100] "%"  CEM
 SG_ DrvrSeatPosPercSeatPosHeiQF : 19|2@0+ (1,0) [0|3] ""  CEM
 SG_ DrvrSeatPosPercSeatPosSldPerc : 39|10@0+ (0.1,0) [0|100] "%"  CEM
 SG_ DrvrSeatPosPercSeatPosSldQF : 21|2@0+ (1,0) [0|3] ""  CEM

BO_ 547 SmdBodyFr06: 8 SMD
 SG_ DrvrSeatActvSwtFctMod : 7|2@0+ (1,0) [0|3] ""  CEM
 SG_ DrvrSeatActvSwtFctMod_UB : 3|1@0+ (1,0) [0|1] ""  CEM
 SG_ DrvrSeatIntgrSwtSts_UB : 1|1@0+ (1,0) [0|1] ""  CEM
 SG_ DrvrSeatIntgrSwtStsIntgrSwtHozlS : 15|2@0+ (1,0) [0|3] ""  CEM
 SG_ DrvrSeatIntgrSwtStsIntgrSwtRotSt : 13|2@0+ (1,0) [0|3] ""  CEM
 SG_ DrvrSeatIntgrSwtStsIntgrSwtSelnS : 11|2@0+ (1,0) [0|3] ""  CEM
 SG_ DrvrSeatIntgrSwtStsIntgrSwtVertS : 9|2@0+ (1,0) [0|3] ""  CEM
 SG_ DrvrSeatPivtPosPerc_UB : 25|1@0+ (1,0) [0|1] ""  CEM
 SG_ DrvrSeatPivtPosPercSeatPosPerc : 21|10@0+ (0.1,0) [0|100] "%"  CEM
 SG_ DrvrSeatPivtPosPercSeatPosQf : 27|2@0+ (1,0) [0|3] ""  CEM
 SG_ DrvrSeatSwtBlstrSts : 5|2@0+ (1,0) [0|3] ""  CEM
 SG_ DrvrSeatSwtBlstrSts_UB : 2|1@0+ (1,0) [0|1] ""  CEM
 SG_ DrvrSeatSwtCushExtSts : 23|2@0+ (1,0) [0|3] ""  CEM
 SG_ DrvrSeatSwtCushExtSts_UB : 0|1@0+ (1,0) [0|1] ""  CEM

BO_ 1298 SmdBodyNMFr01: 8 SMD
 SG_ PNC16_SMD : 16|1@0+ (1,0) [0|0] ""  Vector_XXX
 SG_ PNC17_SMD : 17|1@0+ (1,0) [0|0] ""  Vector_XXX
 SG_ PNC18_SMD : 18|1@0+ (1,0) [0|0] ""  Vector_XXX
 SG_ PNC19_SMD : 19|1@0+ (1,0) [0|0] ""  Vector_XXX
 SG_ PNC20_SMD : 20|1@0+ (1,0) [0|0] ""  Vector_XXX
 SG_ PNC21_SMD : 21|1@0+ (1,0) [0|0] ""  Vector_XXX
 SG_ PNC22_SMD : 22|1@0+ (1,0) [0|0] ""  Vector_XXX
 SG_ PNC23_SMD : 23|1@0+ (1,0) [0|0] ""  Vector_XXX
 SG_ PNC24_SMD : 24|1@0+ (1,0) [0|0] ""  Vector_XXX
 SG_ PNC25_SMD : 25|1@0+ (1,0) [0|0] ""  Vector_XXX
 SG_ PNC26_SMD : 26|1@0+ (1,0) [0|0] ""  Vector_XXX
 SG_ PNC27_SMD : 27|1@0+ (1,0) [0|0] ""  Vector_XXX
 SG_ PNC28_SMD : 28|1@0+ (1,0) [0|0] ""  Vector_XXX
 SG_ PNC29_SMD : 29|1@0+ (1,0) [0|0] ""  Vector_XXX
 SG_ PNC30_SMD : 30|1@0+ (1,0) [0|0] ""  Vector_XXX
 SG_ PNC31_SMD : 31|1@0+ (1,0) [0|0] ""  Vector_XXX
 SG_ PNC32_SMD : 32|1@0+ (1,0) [0|0] ""  Vector_XXX
 SG_ PNC33_SMD : 33|1@0+ (1,0) [0|0] ""  Vector_XXX
 SG_ PNC34_SMD : 34|1@0+ (1,0) [0|0] ""  Vector_XXX
 SG_ PNC35_SMD : 35|1@0+ (1,0) [0|0] ""  Vector_XXX
 SG_ PNC36_SMD : 36|1@0+ (1,0) [0|0] ""  Vector_XXX
 SG_ PNC37_SMD : 37|1@0+ (1,0) [0|0] ""  Vector_XXX
 SG_ PNC38_SMD : 38|1@0+ (1,0) [0|0] ""  Vector_XXX
 SG_ PNC39_SMD : 39|1@0+ (1,0) [0|0] ""  Vector_XXX
 SG_ PNC40_SMD : 40|1@0+ (1,0) [0|0] ""  Vector_XXX
 SG_ PNC41_SMD : 41|1@0+ (1,0) [0|0] ""  Vector_XXX
 SG_ PNC42_SMD : 42|1@0+ (1,0) [0|0] ""  Vector_XXX
 SG_ NM_PNI_SMD : 14|1@0+ (1,0) [0|0] ""  Vector_XXX
 SG_ NM_AW_SMD : 12|1@0+ (1,0) [0|0] ""  Vector_XXX
 SG_ NM_CS_SMD : 11|1@0+ (1,0) [0|0] ""  Vector_XXX
 SG_ NM_RMR_SMD : 8|1@0+ (1,0) [0|0] ""  Vector_XXX
 SG_ NM_NodeID_SMD : 7|8@0+ (1,0) [0|0] ""  Vector_XXX

BO_ 1362 SmdBodyVFCVectorFr: 8 SMD
 SG_ VFCVectorSMDBlockID : 1|2@0+ (1,0) [0|3] "Unitless"  ETC
 SG_ VFCVectorSMDVFCid0 : 2|1@0+ (1,0) [0|1] ""  ETC
 SG_ VFCVectorSMDVFCid1 : 3|1@0+ (1,0) [0|1] ""  ETC
 SG_ VFCVectorSMDVFCid10 : 12|1@0+ (1,0) [0|1] ""  ETC
 SG_ VFCVectorSMDVFCid11 : 13|1@0+ (1,0) [0|1] ""  ETC
 SG_ VFCVectorSMDVFCid12 : 14|1@0+ (1,0) [0|1] ""  ETC
 SG_ VFCVectorSMDVFCid13 : 15|1@0+ (1,0) [0|1] ""  ETC
 SG_ VFCVectorSMDVFCid14 : 16|1@0+ (1,0) [0|1] ""  ETC
 SG_ VFCVectorSMDVFCid15 : 17|1@0+ (1,0) [0|1] ""  ETC
 SG_ VFCVectorSMDVFCid16 : 18|1@0+ (1,0) [0|1] ""  ETC
 SG_ VFCVectorSMDVFCid17 : 19|1@0+ (1,0) [0|1] ""  ETC
 SG_ VFCVectorSMDVFCid18 : 20|1@0+ (1,0) [0|1] ""  ETC
 SG_ VFCVectorSMDVFCid19 : 21|1@0+ (1,0) [0|1] ""  ETC
 SG_ VFCVectorSMDVFCid2 : 4|1@0+ (1,0) [0|1] ""  ETC
 SG_ VFCVectorSMDVFCid20 : 22|1@0+ (1,0) [0|1] ""  ETC
 SG_ VFCVectorSMDVFCid21 : 23|1@0+ (1,0) [0|1] ""  ETC
 SG_ VFCVectorSMDVFCid22 : 24|1@0+ (1,0) [0|1] ""  ETC
 SG_ VFCVectorSMDVFCid23 : 25|1@0+ (1,0) [0|1] ""  ETC
 SG_ VFCVectorSMDVFCid24 : 26|1@0+ (1,0) [0|1] ""  ETC
 SG_ VFCVectorSMDVFCid25 : 27|1@0+ (1,0) [0|1] ""  ETC
 SG_ VFCVectorSMDVFCid26 : 28|1@0+ (1,0) [0|1] ""  ETC
 SG_ VFCVectorSMDVFCid27 : 29|1@0+ (1,0) [0|1] ""  ETC
 SG_ VFCVectorSMDVFCid28 : 30|1@0+ (1,0) [0|1] ""  ETC
 SG_ VFCVectorSMDVFCid29 : 31|1@0+ (1,0) [0|1] ""  ETC
 SG_ VFCVectorSMDVFCid3 : 5|1@0+ (1,0) [0|1] ""  ETC
 SG_ VFCVectorSMDVFCid30 : 32|1@0+ (1,0) [0|1] ""  ETC
 SG_ VFCVectorSMDVFCid31 : 33|1@0+ (1,0) [0|1] ""  ETC
 SG_ VFCVectorSMDVFCid32 : 34|1@0+ (1,0) [0|1] ""  ETC
 SG_ VFCVectorSMDVFCid33 : 35|1@0+ (1,0) [0|1] ""  ETC
 SG_ VFCVectorSMDVFCid34 : 36|1@0+ (1,0) [0|1] ""  ETC
 SG_ VFCVectorSMDVFCid35 : 37|1@0+ (1,0) [0|1] ""  ETC
 SG_ VFCVectorSMDVFCid36 : 38|1@0+ (1,0) [0|1] ""  ETC
 SG_ VFCVectorSMDVFCid37 : 39|1@0+ (1,0) [0|1] ""  ETC
 SG_ VFCVectorSMDVFCid38 : 40|1@0+ (1,0) [0|1] ""  ETC
 SG_ VFCVectorSMDVFCid39 : 41|1@0+ (1,0) [0|1] ""  ETC
 SG_ VFCVectorSMDVFCid4 : 6|1@0+ (1,0) [0|1] ""  ETC
 SG_ VFCVectorSMDVFCid40 : 42|1@0+ (1,0) [0|1] ""  ETC
 SG_ VFCVectorSMDVFCid41 : 43|1@0+ (1,0) [0|1] ""  ETC
 SG_ VFCVectorSMDVFCid42 : 44|1@0+ (1,0) [0|1] ""  ETC
 SG_ VFCVectorSMDVFCid43 : 45|1@0+ (1,0) [0|1] ""  ETC
 SG_ VFCVectorSMDVFCid44 : 46|1@0+ (1,0) [0|1] ""  ETC
 SG_ VFCVectorSMDVFCid45 : 47|1@0+ (1,0) [0|1] ""  ETC
 SG_ VFCVectorSMDVFCid46 : 48|1@0+ (1,0) [0|1] ""  ETC
 SG_ VFCVectorSMDVFCid47 : 49|1@0+ (1,0) [0|1] ""  ETC
 SG_ VFCVectorSMDVFCid48 : 50|1@0+ (1,0) [0|1] ""  ETC
 SG_ VFCVectorSMDVFCid49 : 51|1@0+ (1,0) [0|1] ""  ETC
 SG_ VFCVectorSMDVFCid5 : 7|1@0+ (1,0) [0|1] ""  ETC
 SG_ VFCVectorSMDVFCid50 : 52|1@0+ (1,0) [0|1] ""  ETC
 SG_ VFCVectorSMDVFCid51 : 53|1@0+ (1,0) [0|1] ""  ETC
 SG_ VFCVectorSMDVFCid52 : 54|1@0+ (1,0) [0|1] ""  ETC
 SG_ VFCVectorSMDVFCid53 : 55|1@0+ (1,0) [0|1] ""  ETC
 SG_ VFCVectorSMDVFCid54 : 56|1@0+ (1,0) [0|1] ""  ETC
 SG_ VFCVectorSMDVFCid55 : 57|1@0+ (1,0) [0|1] ""  ETC
 SG_ VFCVectorSMDVFCid56 : 58|1@0+ (1,0) [0|1] ""  ETC
 SG_ VFCVectorSMDVFCid57 : 59|1@0+ (1,0) [0|1] ""  ETC
 SG_ VFCVectorSMDVFCid58 : 60|1@0+ (1,0) [0|1] ""  ETC
 SG_ VFCVectorSMDVFCid59 : 61|1@0+ (1,0) [0|1] ""  ETC
 SG_ VFCVectorSMDVFCid6 : 8|1@0+ (1,0) [0|1] ""  ETC
 SG_ VFCVectorSMDVFCid60 : 62|1@0+ (1,0) [0|1] ""  ETC
 SG_ VFCVectorSMDVFCid61 : 63|1@0+ (1,0) [0|1] ""  ETC
 SG_ VFCVectorSMDVFCid7 : 9|1@0+ (1,0) [0|1] ""  ETC
 SG_ VFCVectorSMDVFCid8 : 10|1@0+ (1,0) [0|1] ""  ETC
 SG_ VFCVectorSMDVFCid9 : 11|1@0+ (1,0) [0|1] ""  ETC

BO_ 1575 SmdToCemBodyDiagResFrame: 8 SMD
 SG_ SmdToCemBodyDiagResNpdu : 7|64@0+ (1,0) [0|0] ""  CEM

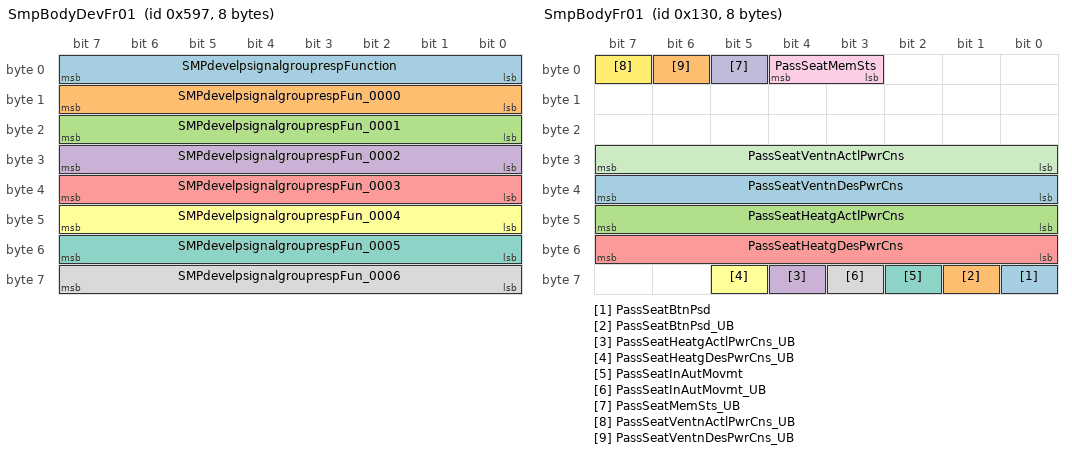
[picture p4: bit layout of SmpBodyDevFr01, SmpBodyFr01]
BO_ 1431 SmpBodyDevFr01: 8 SMP
 SG_ SMPdevelpsignalgrouprespFunction : 7|8@0+ (1,0) [0|255] "Unitless"  ETC
 SG_ SMPdevelpsignalgrouprespFun_0000 : 15|8@0+ (1,0) [0|255] "Unitless"  ETC
 SG_ SMPdevelpsignalgrouprespFun_0001 : 23|8@0+ (1,0) [0|255] "Unitless"  ETC
 SG_ SMPdevelpsignalgrouprespFun_0002 : 31|8@0+ (1,0) [0|255] "Unitless"  ETC
 SG_ SMPdevelpsignalgrouprespFun_0003 : 39|8@0+ (1,0) [0|255] "Unitless"  ETC
 SG_ SMPdevelpsignalgrouprespFun_0004 : 47|8@0+ (1,0) [0|255] "Unitless"  ETC
 SG_ SMPdevelpsignalgrouprespFun_0005 : 55|8@0+ (1,0) [0|255] "Unitless"  ETC
 SG_ SMPdevelpsignalgrouprespFun_0006 : 63|8@0+ (1,0) [0|255] "Unitless"  ETC

BO_ 304 SmpBodyFr01: 8 SMP
 SG_ PassSeatBtnPsd : 56|1@0+ (1,0) [0|1] ""  CEM
 SG_ PassSeatBtnPsd_UB : 57|1@0+ (1,0) [0|1] ""  CEM
 SG_ PassSeatHeatgActlPwrCns : 47|8@0+ (1,0) [0|255] "Unitless"  CCM,CEM
 SG_ PassSeatHeatgActlPwrCns_UB : 60|1@0+ (1,0) [0|1] ""  CCM,CEM
 SG_ PassSeatHeatgDesPwrCns : 55|8@0+ (1,0) [0|255] "Unitless"  CCM,CEM
 SG_ PassSeatHeatgDesPwrCns_UB : 61|1@0+ (1,0) [0|1] ""  CCM,CEM
 SG_ PassSeatInAutMovmt : 58|1@0+ (1,0) [0|1] ""  CEM
 SG_ PassSeatInAutMovmt_UB : 59|1@0+ (1,0) [0|1] ""  CEM
 SG_ PassSeatMemSts : 4|2@0+ (1,0) [0|3] ""  CEM
 SG_ PassSeatMemSts_UB : 5|1@0+ (1,0) [0|1] ""  CEM
 SG_ PassSeatVentnActlPwrCns : 31|8@0+ (1,0) [0|255] "Unitless"  CCM,CEM
 SG_ PassSeatVentnActlPwrCns_UB : 7|1@0+ (1,0) [0|1] ""  CCM,CEM
 SG_ PassSeatVentnDesPwrCns : 39|8@0+ (1,0) [0|255] "Unitless"  CCM,CEM
 SG_ PassSeatVentnDesPwrCns_UB : 6|1@0+ (1,0) [0|1] ""  CCM,CEM

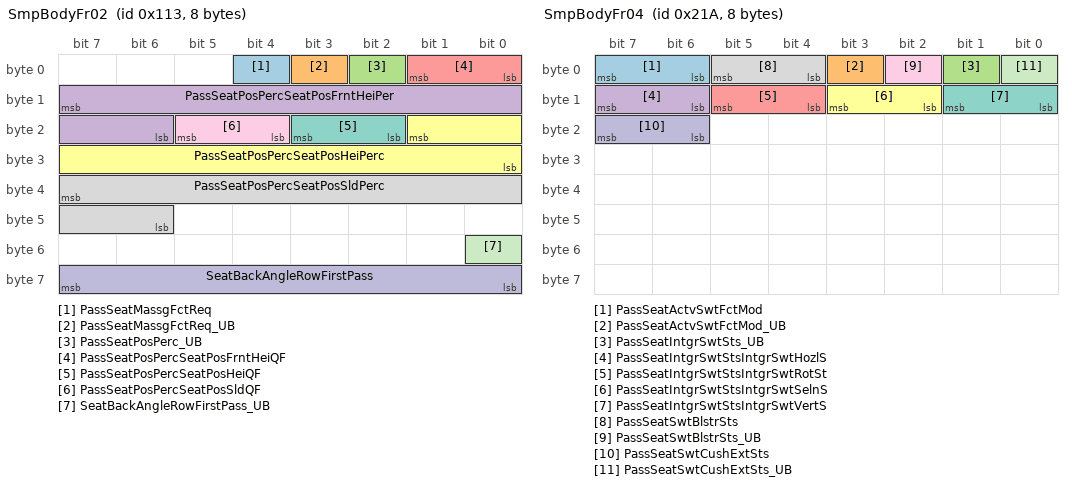
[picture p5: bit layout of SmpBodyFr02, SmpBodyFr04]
BO_ 275 SmpBodyFr02: 8 SMP
 SG_ PassSeatMassgFctReq : 4|1@0+ (1,0) [0|1] ""  CEM
 SG_ PassSeatMassgFctReq_UB : 3|1@0+ (1,0) [0|1] ""  CEM
 SG_ PassSeatPosPerc_UB : 2|1@0+ (1,0) [0|1] ""  CEM
 SG_ PassSeatPosPercSeatPosFrntHeiPer : 15|10@0+ (0.1,0) [0|100] "%"  CEM
 SG_ PassSeatPosPercSeatPosFrntHeiQF : 1|2@0+ (1,0) [0|3] ""  CEM
 SG_ PassSeatPosPercSeatPosHeiPerc : 17|10@0+ (0.1,0) [0|100] "%"  CEM
 SG_ PassSeatPosPercSeatPosHeiQF : 19|2@0+ (1,0) [0|3] ""  CEM
 SG_ PassSeatPosPercSeatPosSldPerc : 39|10@0+ (0.1,0) [0|100] "%"  CEM
 SG_ PassSeatPosPercSeatPosSldQF : 21|2@0+ (1,0) [0|3] ""  CEM
 SG_ SeatBackAngleRowFirstPass : 63|8@0+ (1,0) [0|180] "Deg"  CEM
 SG_ SeatBackAngleRowFirstPass_UB : 48|1@0+ (1,0) [0|1] ""  CEM

BO_ 1063 SmpBodyFr03: 8 SMP
 SG_ PassMassgRunng : 5|1@0+ (1,0) [0|1] ""  CEM
 SG_ PassMassgRunng_UB : 6|1@0+ (1,0) [0|1] ""  CEM
 SG_ PassSeatActvSpplFct : 4|3@0+ (1,0) [0|7] ""  CEM
 SG_ PassSeatActvSpplFct_UB : 7|1@0+ (1,0) [0|1] ""  CEM
 SG_ PassSeatHeatgAvlSts : 10|3@0+ (1,0) [0|7] ""  CCM,CEM
 SG_ PassSeatHeatgAvlSts_UB : 15|1@0+ (1,0) [0|1] ""  CCM,CEM
 SG_ PassSeatHeatgLvlSts : 17|2@0+ (1,0) [0|3] ""  CCM,CEM
 SG_ PassSeatHeatgLvlSts_UB : 18|1@0+ (1,0) [0|1] ""  CCM,CEM
 SG_ PassSeatPivtPosPerc_UB : 59|1@0+ (1,0) [0|1] ""  CEM
 SG_ PassSeatPivtPosPercSeatPosPerc : 55|10@0+ (0.1,0) [0|100] "%"  CEM
 SG_ PassSeatPivtPosPercSeatPosQf : 61|2@0+ (1,0) [0|3] ""  CEM
 SG_ PassSeatSwtSts2_UB : 22|1@0+ (1,0) [0|1] ""  CEM
 SG_ PassSeatSwtSts2PassSeatSwtAdjmtO : 25|2@0+ (1,0) [0|3] ""  CEM
 SG_ PassSeatSwtSts2PassSeatSwtA_0000 : 39|2@0+ (1,0) [0|3] ""  CEM
 SG_ PassSeatSwtSts2PassSeatSwtHdrstH : 37|2@0+ (1,0) [0|3] ""  CEM
 SG_ PassSeatSwtSts2PassSeatSwtHdrstV : 35|2@0+ (1,0) [0|3] ""  CEM
 SG_ PassSeatSwtSts2PassSeatSwtHeiFrn : 33|2@0+ (1,0) [0|3] ""  CEM
 SG_ PassSeatSwtSts2PassSeatSwtHeiSts : 47|2@0+ (1,0) [0|3] ""  CEM
 SG_ PassSeatSwtSts2PassSeatSwtInclSt : 45|2@0+ (1,0) [0|3] ""  CEM
 SG_ PassSeatSwtSts2PassSeatSwtSelnOf : 43|2@0+ (1,0) [0|3] ""  CEM
 SG_ PassSeatSwtSts2PassSeatSwtSldSts : 41|2@0+ (1,0) [0|3] ""  CEM
 SG_ PassSeatVentAvlSts : 13|3@0+ (1,0) [0|7] ""  CCM,CEM
 SG_ PassSeatVentAvlSts_UB : 14|1@0+ (1,0) [0|1] ""  CCM,CEM
 SG_ PassSeatVentnLvlSts : 20|2@0+ (1,0) [0|3] ""  CCM,CEM
 SG_ PassSeatVentnLvlSts_UB : 21|1@0+ (1,0) [0|1] ""  CCM,CEM
 SG_ RowFrstPassODSSts : 1|2@0+ (1,0) [0|3] ""  Vector_XXX
 SG_ RowFrstPassODSSts_UB : 23|1@0+ (1,0) [0|1] ""  Vector_XXX

BO_ 538 SmpBodyFr04: 8 SMP
 SG_ PassSeatActvSwtFctMod : 7|2@0+ (1,0) [0|3] ""  CEM
 SG_ PassSeatActvSwtFctMod_UB : 3|1@0+ (1,0) [0|1] ""  CEM
 SG_ PassSeatIntgrSwtSts_UB : 1|1@0+ (1,0) [0|1] ""  CEM
 SG_ PassSeatIntgrSwtStsIntgrSwtHozlS : 15|2@0+ (1,0) [0|3] ""  CEM
 SG_ PassSeatIntgrSwtStsIntgrSwtRotSt : 13|2@0+ (1,0) [0|3] ""  CEM
 SG_ PassSeatIntgrSwtStsIntgrSwtSelnS : 11|2@0+ (1,0) [0|3] ""  CEM
 SG_ PassSeatIntgrSwtStsIntgrSwtVertS : 9|2@0+ (1,0) [0|3] ""  CEM
 SG_ PassSeatSwtBlstrSts : 5|2@0+ (1,0) [0|3] ""  CEM
 SG_ PassSeatSwtBlstrSts_UB : 2|1@0+ (1,0) [0|1] ""  CEM
 SG_ PassSeatSwtCushExtSts : 23|2@0+ (1,0) [0|3] ""  CEM
 SG_ PassSeatSwtCushExtSts_UB : 0|1@0+ (1,0) [0|1] ""  CEM

BO_ 1299 SmpBodyNMFr01: 8 SMP
 SG_ PNC16_SMP : 16|1@0+ (1,0) [0|0] ""  SMD
 SG_ PNC17_SMP : 17|1@0+ (1,0) [0|0] ""  SMD
 SG_ PNC18_SMP : 18|1@0+ (1,0) [0|0] ""  SMD
 SG_ PNC19_SMP : 19|1@0+ (1,0) [0|0] ""  SMD
 SG_ PNC20_SMP : 20|1@0+ (1,0) [0|0] ""  SMD
 SG_ PNC21_SMP : 21|1@0+ (1,0) [0|0] ""  SMD
 SG_ PNC22_SMP : 22|1@0+ (1,0) [0|0] ""  SMD
 SG_ PNC23_SMP : 23|1@0+ (1,0) [0|0] ""  SMD
 SG_ PNC24_SMP : 24|1@0+ (1,0) [0|0] ""  SMD
 SG_ PNC25_SMP : 25|1@0+ (1,0) [0|0] ""  SMD
 SG_ PNC26_SMP : 26|1@0+ (1,0) [0|0] ""  SMD
 SG_ PNC27_SMP : 27|1@0+ (1,0) [0|0] ""  SMD
 SG_ PNC28_SMP : 28|1@0+ (1,0) [0|0] ""  SMD
 SG_ PNC29_SMP : 29|1@0+ (1,0) [0|0] ""  SMD
 SG_ PNC30_SMP : 30|1@0+ (1,0) [0|0] ""  SMD
 SG_ PNC31_SMP : 31|1@0+ (1,0) [0|0] ""  SMD
 SG_ PNC32_SMP : 32|1@0+ (1,0) [0|0] ""  SMD
 SG_ PNC33_SMP : 33|1@0+ (1,0) [0|0] ""  SMD
 SG_ PNC34_SMP : 34|1@0+ (1,0) [0|0] ""  SMD
 SG_ PNC35_SMP : 35|1@0+ (1,0) [0|0] ""  SMD
 SG_ PNC36_SMP : 36|1@0+ (1,0) [0|0] ""  SMD
 SG_ PNC37_SMP : 37|1@0+ (1,0) [0|0] ""  SMD
 SG_ PNC38_SMP : 38|1@0+ (1,0) [0|0] ""  SMD
 SG_ PNC39_SMP : 39|1@0+ (1,0) [0|0] ""  SMD
 SG_ PNC40_SMP : 40|1@0+ (1,0) [0|0] ""  SMD
 SG_ PNC41_SMP : 41|1@0+ (1,0) [0|0] ""  SMD
 SG_ PNC42_SMP : 42|1@0+ (1,0) [0|0] ""  SMD
 SG_ NM_PNI_SMP : 14|1@0+ (1,0) [0|0] ""  SMD
 SG_ NM_AW_SMP : 12|1@0+ (1,0) [0|0] ""  SMD
 SG_ NM_CS_SMP : 11|1@0+ (1,0) [0|0] ""  SMD
 SG_ NM_RMR_SMP : 8|1@0+ (1,0) [0|0] ""  SMD
 SG_ NM_NodeID_SMP : 7|8@0+ (1,0) [0|0] ""  SMD

BO_ 1363 SmpBodyVFCVectorFr: 8 SMP
 SG_ VFCVectorSMPBlockID : 1|2@0+ (1,0) [0|3] "Unitless"  ETC
 SG_ VFCVectorSMPVFCid0 : 2|1@0+ (1,0) [0|1] ""  ETC
 SG_ VFCVectorSMPVFCid1 : 3|1@0+ (1,0) [0|1] ""  ETC
 SG_ VFCVectorSMPVFCid10 : 12|1@0+ (1,0) [0|1] ""  ETC
 SG_ VFCVectorSMPVFCid11 : 13|1@0+ (1,0) [0|1] ""  ETC
 SG_ VFCVectorSMPVFCid12 : 14|1@0+ (1,0) [0|1] ""  ETC
 SG_ VFCVectorSMPVFCid13 : 15|1@0+ (1,0) [0|1] ""  ETC
 SG_ VFCVectorSMPVFCid14 : 16|1@0+ (1,0) [0|1] ""  ETC
 SG_ VFCVectorSMPVFCid15 : 17|1@0+ (1,0) [0|1] ""  ETC
 SG_ VFCVectorSMPVFCid16 : 18|1@0+ (1,0) [0|1] ""  ETC
 SG_ VFCVectorSMPVFCid17 : 19|1@0+ (1,0) [0|1] ""  ETC
 SG_ VFCVectorSMPVFCid18 : 20|1@0+ (1,0) [0|1] ""  ETC
 SG_ VFCVectorSMPVFCid19 : 21|1@0+ (1,0) [0|1] ""  ETC
 SG_ VFCVectorSMPVFCid2 : 4|1@0+ (1,0) [0|1] ""  ETC
 SG_ VFCVectorSMPVFCid20 : 22|1@0+ (1,0) [0|1] ""  ETC
 SG_ VFCVectorSMPVFCid21 : 23|1@0+ (1,0) [0|1] ""  ETC
 SG_ VFCVectorSMPVFCid22 : 24|1@0+ (1,0) [0|1] ""  ETC
 SG_ VFCVectorSMPVFCid23 : 25|1@0+ (1,0) [0|1] ""  ETC
 SG_ VFCVectorSMPVFCid24 : 26|1@0+ (1,0) [0|1] ""  ETC
 SG_ VFCVectorSMPVFCid25 : 27|1@0+ (1,0) [0|1] ""  ETC
 SG_ VFCVectorSMPVFCid26 : 28|1@0+ (1,0) [0|1] ""  ETC
 SG_ VFCVectorSMPVFCid27 : 29|1@0+ (1,0) [0|1] ""  ETC
 SG_ VFCVectorSMPVFCid28 : 30|1@0+ (1,0) [0|1] ""  ETC
 SG_ VFCVectorSMPVFCid29 : 31|1@0+ (1,0) [0|1] ""  ETC
 SG_ VFCVectorSMPVFCid3 : 5|1@0+ (1,0) [0|1] ""  ETC
 SG_ VFCVectorSMPVFCid30 : 32|1@0+ (1,0) [0|1] ""  ETC
 SG_ VFCVectorSMPVFCid31 : 33|1@0+ (1,0) [0|1] ""  ETC
 SG_ VFCVectorSMPVFCid32 : 34|1@0+ (1,0) [0|1] ""  ETC
 SG_ VFCVectorSMPVFCid33 : 35|1@0+ (1,0) [0|1] ""  ETC
 SG_ VFCVectorSMPVFCid34 : 36|1@0+ (1,0) [0|1] ""  ETC
 SG_ VFCVectorSMPVFCid35 : 37|1@0+ (1,0) [0|1] ""  ETC
 SG_ VFCVectorSMPVFCid36 : 38|1@0+ (1,0) [0|1] ""  ETC
 SG_ VFCVectorSMPVFCid37 : 39|1@0+ (1,0) [0|1] ""  ETC
 SG_ VFCVectorSMPVFCid38 : 40|1@0+ (1,0) [0|1] ""  ETC
 SG_ VFCVectorSMPVFCid39 : 41|1@0+ (1,0) [0|1] ""  ETC
 SG_ VFCVectorSMPVFCid4 : 6|1@0+ (1,0) [0|1] ""  ETC
 SG_ VFCVectorSMPVFCid40 : 42|1@0+ (1,0) [0|1] ""  ETC
 SG_ VFCVectorSMPVFCid41 : 43|1@0+ (1,0) [0|1] ""  ETC
 SG_ VFCVectorSMPVFCid42 : 44|1@0+ (1,0) [0|1] ""  ETC
 SG_ VFCVectorSMPVFCid43 : 45|1@0+ (1,0) [0|1] ""  ETC
 SG_ VFCVectorSMPVFCid44 : 46|1@0+ (1,0) [0|1] ""  ETC
 SG_ VFCVectorSMPVFCid45 : 47|1@0+ (1,0) [0|1] ""  ETC
 SG_ VFCVectorSMPVFCid46 : 48|1@0+ (1,0) [0|1] ""  ETC
 SG_ VFCVectorSMPVFCid47 : 49|1@0+ (1,0) [0|1] ""  ETC
 SG_ VFCVectorSMPVFCid48 : 50|1@0+ (1,0) [0|1] ""  ETC
 SG_ VFCVectorSMPVFCid49 : 51|1@0+ (1,0) [0|1] ""  ETC
 SG_ VFCVectorSMPVFCid5 : 7|1@0+ (1,0) [0|1] ""  ETC
 SG_ VFCVectorSMPVFCid50 : 52|1@0+ (1,0) [0|1] ""  ETC
 SG_ VFCVectorSMPVFCid51 : 53|1@0+ (1,0) [0|1] ""  ETC
 SG_ VFCVectorSMPVFCid52 : 54|1@0+ (1,0) [0|1] ""  ETC
 SG_ VFCVectorSMPVFCid53 : 55|1@0+ (1,0) [0|1] ""  ETC
 SG_ VFCVectorSMPVFCid54 : 56|1@0+ (1,0) [0|1] ""  ETC
 SG_ VFCVectorSMPVFCid55 : 57|1@0+ (1,0) [0|1] ""  ETC
 SG_ VFCVectorSMPVFCid56 : 58|1@0+ (1,0) [0|1] ""  ETC
 SG_ VFCVectorSMPVFCid57 : 59|1@0+ (1,0) [0|1] ""  ETC
 SG_ VFCVectorSMPVFCid58 : 60|1@0+ (1,0) [0|1] ""  ETC
 SG_ VFCVectorSMPVFCid59 : 61|1@0+ (1,0) [0|1] ""  ETC
 SG_ VFCVectorSMPVFCid6 : 8|1@0+ (1,0) [0|1] ""  ETC
 SG_ VFCVectorSMPVFCid60 : 62|1@0+ (1,0) [0|1] ""  ETC
 SG_ VFCVectorSMPVFCid61 : 63|1@0+ (1,0) [0|1] ""  ETC
 SG_ VFCVectorSMPVFCid7 : 9|1@0+ (1,0) [0|1] ""  ETC
 SG_ VFCVectorSMPVFCid8 : 10|1@0+ (1,0) [0|1] ""  ETC
 SG_ VFCVectorSMPVFCid9 : 11|1@0+ (1,0) [0|1] ""  ETC

BO_ 1576 SmpToCemBodyDiagResFrame: 8 SMP
 SG_ SmpToCemBodyDiagResNpdu : 7|64@0+ (1,0) [0|0] ""  CEM

BO_ 208 TrmBodyFr01: 4 TRM
 SG_ TrlrFogLiSts : 17|1@0+ (1,0) [0|1] ""  CEM
 SG_ TrlrFogLiSts_UB : 16|1@0+ (1,0) [0|1] ""  CEM
 SG_ TrlrLampActvtChk : 15|1@0+ (1,0) [0|1] ""  CEM
 SG_ TrlrLampActvtChk_UB : 8|1@0+ (1,0) [0|1] ""  CEM
 SG_ TrlrLampChkSts : 7|3@0+ (1,0) [0|7] ""  CEM
 SG_ TrlrLampChkSts_UB : 23|1@0+ (1,0) [0|1] ""  CEM
 SG_ TrlrLeIndcrFltSts : 1|1@0+ (1,0) [0|1] ""  CEM
 SG_ TrlrLeIndcrFltSts_UB : 10|1@0+ (1,0) [0|1] ""  CEM
 SG_ TrlrLiFltSts : 4|3@0+ (1,0) [0|7] ""  CEM
 SG_ TrlrLiFltSts_UB : 22|1@0+ (1,0) [0|1] ""  CEM
 SG_ TrlrPrmntPwrActv : 14|1@0+ (1,0) [0|1] ""  CEM
 SG_ TrlrPrmntPwrActv_UB : 21|1@0+ (1,0) [0|1] ""  CEM
 SG_ TrlrPrsnt : 13|1@0+ (1,0) [0|1] ""  CEM
 SG_ TrlrPrsnt_UB : 20|1@0+ (1,0) [0|1] ""  CEM
 SG_ TrlrRiIndcrFltSts : 0|1@0+ (1,0) [0|1] ""  CEM
 SG_ TrlrRiIndcrFltSts_UB : 9|1@0+ (1,0) [0|1] ""  CEM
 SG_ TrlrSrvReq : 12|1@0+ (1,0) [0|1] ""  CEM
 SG_ TrlrSrvReq_UB : 19|1@0+ (1,0) [0|1] ""  CEM

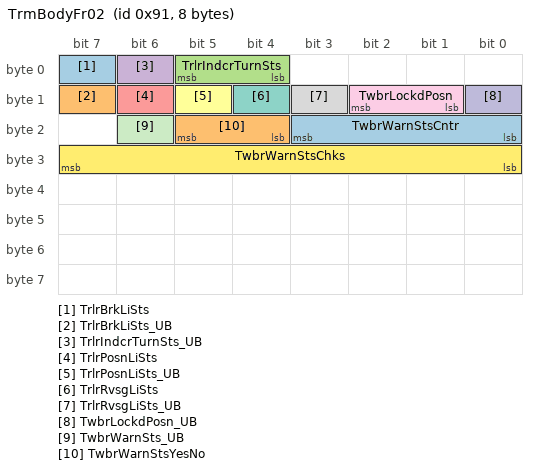
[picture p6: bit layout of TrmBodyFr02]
BO_ 145 TrmBodyFr02: 8 TRM
 SG_ TrlrBrkLiSts : 7|1@0+ (1,0) [0|1] ""  CEM
 SG_ TrlrBrkLiSts_UB : 15|1@0+ (1,0) [0|1] ""  CEM
 SG_ TrlrIndcrTurnSts : 5|2@0+ (1,0) [0|3] ""  CEM
 SG_ TrlrIndcrTurnSts_UB : 6|1@0+ (1,0) [0|1] ""  CEM
 SG_ TrlrPosnLiSts : 14|1@0+ (1,0) [0|1] ""  CEM
 SG_ TrlrPosnLiSts_UB : 13|1@0+ (1,0) [0|1] ""  CEM
 SG_ TrlrRvsgLiSts : 12|1@0+ (1,0) [0|1] ""  CEM
 SG_ TrlrRvsgLiSts_UB : 11|1@0+ (1,0) [0|1] ""  CEM
 SG_ TwbrLockdPosn : 10|2@0+ (1,0) [0|3] ""  CEM
 SG_ TwbrLockdPosn_UB : 8|1@0+ (1,0) [0|1] ""  CEM
 SG_ TwbrWarnSts_UB : 22|1@0+ (1,0) [0|1] ""  CEM
 SG_ TwbrWarnStsChks : 31|8@0+ (1,0) [0|255] "Unitless"  CEM
 SG_ TwbrWarnStsCntr : 19|4@0+ (1,0) [0|15] "Unitless"  CEM
 SG_ TwbrWarnStsYesNo : 21|2@0+ (1,0) [0|3] ""  CEM

BO_ 1290 TrmBodyNMFr: 8 TRM
 SG_ PNC16_TRM : 16|1@0+ (1,0) [0|0] ""  SMP
 SG_ PNC17_TRM : 17|1@0+ (1,0) [0|0] ""  SMP
 SG_ PNC18_TRM : 18|1@0+ (1,0) [0|0] ""  SMP
 SG_ PNC19_TRM : 19|1@0+ (1,0) [0|0] ""  SMP
 SG_ PNC20_TRM : 20|1@0+ (1,0) [0|0] ""  SMP
 SG_ PNC21_TRM : 21|1@0+ (1,0) [0|0] ""  SMP
 SG_ PNC22_TRM : 22|1@0+ (1,0) [0|0] ""  SMP
 SG_ PNC23_TRM : 23|1@0+ (1,0) [0|0] ""  SMP
 SG_ PNC24_TRM : 24|1@0+ (1,0) [0|0] ""  SMP
 SG_ PNC25_TRM : 25|1@0+ (1,0) [0|0] ""  SMP
 SG_ PNC26_TRM : 26|1@0+ (1,0) [0|0] ""  SMP
 SG_ PNC27_TRM : 27|1@0+ (1,0) [0|0] ""  SMP
 SG_ PNC28_TRM : 28|1@0+ (1,0) [0|0] ""  SMP
 SG_ PNC29_TRM : 29|1@0+ (1,0) [0|0] ""  SMP
 SG_ PNC30_TRM : 30|1@0+ (1,0) [0|0] ""  SMP
 SG_ PNC31_TRM : 31|1@0+ (1,0) [0|0] ""  SMP
 SG_ PNC32_TRM : 32|1@0+ (1,0) [0|0] ""  SMP
 SG_ PNC33_TRM : 33|1@0+ (1,0) [0|0] ""  SMP
 SG_ PNC34_TRM : 34|1@0+ (1,0) [0|0] ""  SMP
 SG_ PNC35_TRM : 35|1@0+ (1,0) [0|0] ""  SMP
 SG_ PNC36_TRM : 36|1@0+ (1,0) [0|0] ""  SMP
 SG_ PNC37_TRM : 37|1@0+ (1,0) [0|0] ""  SMP
 SG_ PNC38_TRM : 38|1@0+ (1,0) [0|0] ""  SMP
 SG_ PNC39_TRM : 39|1@0+ (1,0) [0|0] ""  SMP
 SG_ PNC40_TRM : 40|1@0+ (1,0) [0|0] ""  SMP
 SG_ PNC41_TRM : 41|1@0+ (1,0) [0|0] ""  SMP
 SG_ PNC42_TRM : 42|1@0+ (1,0) [0|0] ""  SMP
 SG_ NM_PNI_TRM : 14|1@0+ (1,0) [0|0] ""  SMP
 SG_ NM_AW_TRM : 12|1@0+ (1,0) [0|0] ""  SMP
 SG_ NM_CS_TRM : 11|1@0+ (1,0) [0|0] ""  SMP
 SG_ NM_RMR_TRM : 8|1@0+ (1,0) [0|0] ""  SMP
 SG_ NM_NodeID_TRM : 7|8@0+ (1,0) [0|0] ""  SMP

BO_ 1365 TrmBodyVFCVectorFr: 8 TRM
 SG_ VFCVectorTRMBlockID : 1|2@0+ (1,0) [0|3] "Unitless"  ETC
 SG_ VFCVectorTRMVFCid0 : 2|1@0+ (1,0) [0|1] ""  ETC
 SG_ VFCVectorTRMVFCid1 : 3|1@0+ (1,0) [0|1] ""  ETC
 SG_ VFCVectorTRMVFCid10 : 12|1@0+ (1,0) [0|1] ""  ETC
 SG_ VFCVectorTRMVFCid11 : 13|1@0+ (1,0) [0|1] ""  ETC
 SG_ VFCVectorTRMVFCid12 : 14|1@0+ (1,0) [0|1] ""  ETC
 SG_ VFCVectorTRMVFCid13 : 15|1@0+ (1,0) [0|1] ""  ETC
 SG_ VFCVectorTRMVFCid14 : 16|1@0+ (1,0) [0|1] ""  ETC
 SG_ VFCVectorTRMVFCid15 : 17|1@0+ (1,0) [0|1] ""  ETC
 SG_ VFCVectorTRMVFCid16 : 18|1@0+ (1,0) [0|1] ""  ETC
 SG_ VFCVectorTRMVFCid17 : 19|1@0+ (1,0) [0|1] ""  ETC
 SG_ VFCVectorTRMVFCid18 : 20|1@0+ (1,0) [0|1] ""  ETC
 SG_ VFCVectorTRMVFCid19 : 21|1@0+ (1,0) [0|1] ""  ETC
 SG_ VFCVectorTRMVFCid2 : 4|1@0+ (1,0) [0|1] ""  ETC
 SG_ VFCVectorTRMVFCid20 : 22|1@0+ (1,0) [0|1] ""  ETC
 SG_ VFCVectorTRMVFCid21 : 23|1@0+ (1,0) [0|1] ""  ETC
 SG_ VFCVectorTRMVFCid22 : 24|1@0+ (1,0) [0|1] ""  ETC
 SG_ VFCVectorTRMVFCid23 : 25|1@0+ (1,0) [0|1] ""  ETC
 SG_ VFCVectorTRMVFCid24 : 26|1@0+ (1,0) [0|1] ""  ETC
 SG_ VFCVectorTRMVFCid25 : 27|1@0+ (1,0) [0|1] ""  ETC
 SG_ VFCVectorTRMVFCid26 : 28|1@0+ (1,0) [0|1] ""  ETC
 SG_ VFCVectorTRMVFCid27 : 29|1@0+ (1,0) [0|1] ""  ETC
 SG_ VFCVectorTRMVFCid28 : 30|1@0+ (1,0) [0|1] ""  ETC
 SG_ VFCVectorTRMVFCid29 : 31|1@0+ (1,0) [0|1] ""  ETC
 SG_ VFCVectorTRMVFCid3 : 5|1@0+ (1,0) [0|1] ""  ETC
 SG_ VFCVectorTRMVFCid30 : 32|1@0+ (1,0) [0|1] ""  ETC
 SG_ VFCVectorTRMVFCid31 : 33|1@0+ (1,0) [0|1] ""  ETC
 SG_ VFCVectorTRMVFCid32 : 34|1@0+ (1,0) [0|1] ""  ETC
 SG_ VFCVectorTRMVFCid33 : 35|1@0+ (1,0) [0|1] ""  ETC
 SG_ VFCVectorTRMVFCid34 : 36|1@0+ (1,0) [0|1] ""  ETC
 SG_ VFCVectorTRMVFCid35 : 37|1@0+ (1,0) [0|1] ""  ETC
 SG_ VFCVectorTRMVFCid36 : 38|1@0+ (1,0) [0|1] ""  ETC
 SG_ VFCVectorTRMVFCid37 : 39|1@0+ (1,0) [0|1] ""  ETC
 SG_ VFCVectorTRMVFCid38 : 40|1@0+ (1,0) [0|1] ""  ETC
 SG_ VFCVectorTRMVFCid39 : 41|1@0+ (1,0) [0|1] ""  ETC
 SG_ VFCVectorTRMVFCid4 : 6|1@0+ (1,0) [0|1] ""  ETC
 SG_ VFCVectorTRMVFCid40 : 42|1@0+ (1,0) [0|1] ""  ETC
 SG_ VFCVectorTRMVFCid41 : 43|1@0+ (1,0) [0|1] ""  ETC
 SG_ VFCVectorTRMVFCid42 : 44|1@0+ (1,0) [0|1] ""  ETC
 SG_ VFCVectorTRMVFCid43 : 45|1@0+ (1,0) [0|1] ""  ETC
 SG_ VFCVectorTRMVFCid44 : 46|1@0+ (1,0) [0|1] ""  ETC
 SG_ VFCVectorTRMVFCid45 : 47|1@0+ (1,0) [0|1] ""  ETC
 SG_ VFCVectorTRMVFCid46 : 48|1@0+ (1,0) [0|1] ""  ETC
 SG_ VFCVectorTRMVFCid47 : 49|1@0+ (1,0) [0|1] ""  ETC
 SG_ VFCVectorTRMVFCid48 : 50|1@0+ (1,0) [0|1] ""  ETC
 SG_ VFCVectorTRMVFCid49 : 51|1@0+ (1,0) [0|1] ""  ETC
 SG_ VFCVectorTRMVFCid5 : 7|1@0+ (1,0) [0|1] ""  ETC
 SG_ VFCVectorTRMVFCid50 : 52|1@0+ (1,0) [0|1] ""  ETC
 SG_ VFCVectorTRMVFCid51 : 53|1@0+ (1,0) [0|1] ""  ETC
 SG_ VFCVectorTRMVFCid52 : 54|1@0+ (1,0) [0|1] ""  ETC
 SG_ VFCVectorTRMVFCid53 : 55|1@0+ (1,0) [0|1] ""  ETC
 SG_ VFCVectorTRMVFCid54 : 56|1@0+ (1,0) [0|1] ""  ETC
 SG_ VFCVectorTRMVFCid55 : 57|1@0+ (1,0) [0|1] ""  ETC
 SG_ VFCVectorTRMVFCid56 : 58|1@0+ (1,0) [0|1] ""  ETC
 SG_ VFCVectorTRMVFCid57 : 59|1@0+ (1,0) [0|1] ""  ETC
 SG_ VFCVectorTRMVFCid58 : 60|1@0+ (1,0) [0|1] ""  ETC
 SG_ VFCVectorTRMVFCid59 : 61|1@0+ (1,0) [0|1] ""  ETC
 SG_ VFCVectorTRMVFCid6 : 8|1@0+ (1,0) [0|1] ""  ETC
 SG_ VFCVectorTRMVFCid60 : 62|1@0+ (1,0) [0|1] ""  ETC
 SG_ VFCVectorTRMVFCid61 : 63|1@0+ (1,0) [0|1] ""  ETC
 SG_ VFCVectorTRMVFCid7 : 9|1@0+ (1,0) [0|1] ""  ETC
 SG_ VFCVectorTRMVFCid8 : 10|1@0+ (1,0) [0|1] ""  ETC
 SG_ VFCVectorTRMVFCid9 : 11|1@0+ (1,0) [0|1] ""  ETC

BO_ 1559 TrmToCemBodyDiagResFrame: 8 TRM
 SG_ TrmToCemBodyDiagResNpdu : 7|64@0+ (1,0) [0|0] ""  CEM

BO_ 1464 TrmtoEtcXcpFr01: 8 TRM

CM_ SG_ 112 ChdLockLeftSts "CdhLockgProtnStsAtLeRe - Child Lock Protection Status at Left Rear Door
Indicates child lock status for left rear door
On - Child lock is active
Off - Child lock is not active";
CM_ SG_ 112 DoorLeReCinhIntFailInfCinchFlt1 "Cinch fault";
CM_ SG_ 112 DoorLeReCinhIntFailInfCinchRestF "Cinch reset fault";
CM_ SG_ 112 DoorLeReHndlHMIStsDeployedOverTm "Signal Utilized to communicate to HMI subsystem the following specific events in Left Rear door
Handle retract over timed On-Off
Handle deploy over timed On-Off
Unsuccessful  Hall sensor reset On-Off";
CM_ SG_ 112 DoorLeReHndlHMIStsReserved1 "Signal Utilized to communicate to HMI subsystem the following specific events in Left Rear door
Handle retract over timed On-Off
Handle deploy over timed On-Off
Unsuccessful  Hall sensor reset On-Off";
CM_ SG_ 112 DoorLeReHndlHMIStsRetractOverTmd "Signal Utilized to communicate to HMI subsystem the following specific events in Left Rear door
Handle retract over timed On-Off
Handle deploy over timed On-Off
Unsuccessful  Hall sensor reset On-Off";
CM_ SG_ 112 DoorLeReHndlHMIStsUnsScsHallSnsr "Signal Utilized to communicate to HMI subsystem the following specific events in Left Rear door
Handle retract over timed On-Off
Handle deploy over timed On-Off
Unsuccessful  Hall sensor reset On-Off";
CM_ SG_ 112 DoorLeReHndlSts "To inform about left rear door handle status, i.e. unknown, opened, closed according to
DoorLeReHndlSts
- Ukwn
- FullRtrctd
- MovgOut
- StopDurgDply
- FullDplyd
- MovgIn
- StopDurgRtrct
- Flt";
CM_ SG_ 112 DoorLeReLatPawlSt "Used to indicate if the Left Rear door actuator must be triggered based in the pawl switch status AND other conditions from Left Rear door latch. [Close] Door is fully closed, the Pawl switch has changed value to PSD and timer to reach ajar is out without reaching ajar. [Open] Pawl Switch has not changed status to [PSD] OR latch successfully reach Ajar position within time. [Undefined] Not enough information about Pawl Switch status is found";
CM_ SG_ 112 DoorLeReLatPosn "Left rear door Cinch position. x01 equal fully open, x02 equal secondary position, x03 equal fully closed.";
CM_ SG_ 112 DoorLeReLockSts "DoorLeReLockSts - Left Rear Door Lock Status
Lock status
LockStsUkwn - Lock Status Unknown
Unlckd - Unlocked
Lockd - Locked
SafeLockd - Safe Locked (Double Locked)";
CM_ SG_ 112 DoorLeReOpenLowReqOutdSwt1 "DoorLeReOpenLowReqOutdSwt1 - Left Rear Door Open Request from Outside Switch 1 - Traditional door (No Power operated). Button status of the outside Left Rear door handle switch connection 1.
Psd - Pressed
NotPsd - Not Pressed
NoInfo1/2 - Invalid";
CM_ SG_ 112 DoorLeReOpenReqInsdSwt1 "DoorDrvrOpenReqInsdSwt1 - Left Rear Door Open Request from Inside Switch 1
Button status of the inside left rear door handle switch connection 1
Psd - Pressed
NotPsd - Not Pressed
NoInfo1/2 - Invalid";
CM_ SG_ 112 DoorLeReRelsFailCinchOverTimed "Cinch processwas not successfull. It is overtimed.";
CM_ SG_ 112 DoorLeReRelsFailFailure1 "Issue described by requiremnt according to specific project";
CM_ SG_ 112 DoorLeReRelsFailMechRels "Door Mechanical release (No Power operated)";
CM_ SG_ 112 DoorLeReSwtLockgSts "DoorLeReSwtLockgSts - Left Rear Door Locking Switch Status
Status of the left rear door interior locking switch
Psd - Pressed
NotPsd - Not Pressed";
CM_ SG_ 112 DoorRiRe2Swt1DplyHndl "Door RiRe 2 Switch solution deployable handle [Switch 1]
Psd - Pressed = 0
NotPsd - Not Pressed = 1";
CM_ SG_ 112 DoorRiRe2Swt2DplyHndl "Door RiRe 2 Switch solution deployable handle [Switch 2]
Psd - Pressed = 0
NotPsd - Not Pressed = 1";
CM_ SG_ 112 PassSeatRemCtrlReDoorLeActrIncSt "Door Switch for First Row Passenger Seat Inclination (Backrest) Adjustment";
CM_ SG_ 112 PassSeatRemCtrlReDoorLeActrSldSt "Door Switch for First Row Passenger Seat Slide (Length) Adjustment";
CM_ SG_ 112 ShortDropWinReLeSts "Short drop a status sent back to locking to secure window is down and door is ready to be released. ";
CM_ SG_ 112 WinDsblLeftSts "Signal sent from the rear driver door module to the Driver door module that informs of the local status of the power window disable functionality.
";
CM_ SG_ 112 WinFailrStsAtReLe "Report failure if Window motor is not possible to Run";
CM_ SG_ 112 WinPosnStsAtReLe "Signal sent to inform the rest of the car of the window position status for the rear driver side door. The value of the signal is either an approximated percentage of openness, of the window is moving or if the position is unkown.

";
CM_ SG_ 112 WinPosReqReRi "Request to move Rear Right window from RLDM";
CM_ SG_ 97 ElecChromWinAtReLeFailr "dimming system failure for rear left window";
CM_ SG_ 97 ElecChromWinAtReLeFb "transparency feedback signal from rear left window";
CM_ SG_ 1353 VFCVectorRLDMBlockID "Block Identifier";
CM_ SG_ 1353 VFCVectorRLDMVFCid0 "VFC0";
CM_ SG_ 1353 VFCVectorRLDMVFCid1 "VFC1";
CM_ SG_ 1353 VFCVectorRLDMVFCid10 "VFC10";
CM_ SG_ 1353 VFCVectorRLDMVFCid11 "VFC11";
CM_ SG_ 1353 VFCVectorRLDMVFCid12 "VFC12";
CM_ SG_ 1353 VFCVectorRLDMVFCid13 "VFC13";
CM_ SG_ 1353 VFCVectorRLDMVFCid14 "VFC14";
CM_ SG_ 1353 VFCVectorRLDMVFCid15 "VFC15";
CM_ SG_ 1353 VFCVectorRLDMVFCid16 "VFC16";
CM_ SG_ 1353 VFCVectorRLDMVFCid17 "VFC17";
CM_ SG_ 1353 VFCVectorRLDMVFCid18 "VFC18";
CM_ SG_ 1353 VFCVectorRLDMVFCid19 "VFC19";
CM_ SG_ 1353 VFCVectorRLDMVFCid2 "VFC2";
CM_ SG_ 1353 VFCVectorRLDMVFCid20 "VFC20";
CM_ SG_ 1353 VFCVectorRLDMVFCid21 "VFC21";
CM_ SG_ 1353 VFCVectorRLDMVFCid22 "VFC22";
CM_ SG_ 1353 VFCVectorRLDMVFCid23 "VFC23";
CM_ SG_ 1353 VFCVectorRLDMVFCid24 "VFC24";
CM_ SG_ 1353 VFCVectorRLDMVFCid25 "VFC25";
CM_ SG_ 1353 VFCVectorRLDMVFCid26 "VFC26";
CM_ SG_ 1353 VFCVectorRLDMVFCid27 "VFC27";
CM_ SG_ 1353 VFCVectorRLDMVFCid28 "VFC28";
CM_ SG_ 1353 VFCVectorRLDMVFCid29 "VFC29";
CM_ SG_ 1353 VFCVectorRLDMVFCid3 "VFC3";
CM_ SG_ 1353 VFCVectorRLDMVFCid30 "VFC30";
CM_ SG_ 1353 VFCVectorRLDMVFCid31 "VFC31";
CM_ SG_ 1353 VFCVectorRLDMVFCid32 "VFC32";
CM_ SG_ 1353 VFCVectorRLDMVFCid33 "VFC33";
CM_ SG_ 1353 VFCVectorRLDMVFCid34 "VFC34";
CM_ SG_ 1353 VFCVectorRLDMVFCid35 "VFC35";
CM_ SG_ 1353 VFCVectorRLDMVFCid36 "VFC36";
CM_ SG_ 1353 VFCVectorRLDMVFCid37 "VFC37";
CM_ SG_ 1353 VFCVectorRLDMVFCid38 "VFC38";
CM_ SG_ 1353 VFCVectorRLDMVFCid39 "VFC39";
CM_ SG_ 1353 VFCVectorRLDMVFCid4 "VFC4";
CM_ SG_ 1353 VFCVectorRLDMVFCid40 "VFC40";
CM_ SG_ 1353 VFCVectorRLDMVFCid41 "VFC41";
CM_ SG_ 1353 VFCVectorRLDMVFCid42 "VFC42";
CM_ SG_ 1353 VFCVectorRLDMVFCid43 "VFC43";
CM_ SG_ 1353 VFCVectorRLDMVFCid44 "VFC44";
CM_ SG_ 1353 VFCVectorRLDMVFCid45 "VFC45";
CM_ SG_ 1353 VFCVectorRLDMVFCid46 "VFC46";
CM_ SG_ 1353 VFCVectorRLDMVFCid47 "VFC47";
CM_ SG_ 1353 VFCVectorRLDMVFCid48 "VFC48";
CM_ SG_ 1353 VFCVectorRLDMVFCid49 "VFC49";
CM_ SG_ 1353 VFCVectorRLDMVFCid5 "VFC5";
CM_ SG_ 1353 VFCVectorRLDMVFCid50 "VFC50";
CM_ SG_ 1353 VFCVectorRLDMVFCid51 "VFC51";
CM_ SG_ 1353 VFCVectorRLDMVFCid52 "VFC52";
CM_ SG_ 1353 VFCVectorRLDMVFCid53 "VFC53";
CM_ SG_ 1353 VFCVectorRLDMVFCid54 "VFC54";
CM_ SG_ 1353 VFCVectorRLDMVFCid55 "VFC55";
CM_ SG_ 1353 VFCVectorRLDMVFCid56 "VFC56";
CM_ SG_ 1353 VFCVectorRLDMVFCid57 "VFC57";
CM_ SG_ 1353 VFCVectorRLDMVFCid58 "VFC58";
CM_ SG_ 1353 VFCVectorRLDMVFCid59 "VFC59";
CM_ SG_ 1353 VFCVectorRLDMVFCid6 "VFC6";
CM_ SG_ 1353 VFCVectorRLDMVFCid60 "VFC60";
CM_ SG_ 1353 VFCVectorRLDMVFCid61 "VFC61";
CM_ SG_ 1353 VFCVectorRLDMVFCid7 "VFC7";
CM_ SG_ 1353 VFCVectorRLDMVFCid8 "VFC8";
CM_ SG_ 1353 VFCVectorRLDMVFCid9 "VFC9";
CM_ SG_ 117 ChdLockRightSts "CdhLockgProtnStsAtRiRe - Child Lock Protection Status at Right Rear Door
Indicates child lock status for right rear door
On - Child lock is active
Off - Child lock is not active";
CM_ SG_ 117 DoorLeRe2Swt1DplyHndl "Door LeRe 2 Switch solution deployable handle [Switch 1]
Psd - Pressed = 0
NotPsd - Not Pressed = 1";
CM_ SG_ 117 DoorLeRe2Swt2DplyHndl "Door LeRe 2 Switch solution deployable handle [Switch 2]
Psd - Pressed = 0
NotPsd - Not Pressed = 1";
CM_ SG_ 117 DoorRiReCinhIntFailInfCinchFlt1 "Cinch fault";
CM_ SG_ 117 DoorRiReCinhIntFailInfCinchRestF "Cinch reset fault";
CM_ SG_ 117 DoorRiReHndlHMIStsDeployedOverTm "Signal Utilized to communicate to HMI subsystem the following specific events in Right Rear door
Handle retract over timed On-Off
Handle deploy over timed On-Off
Unsuccessful  Hall sensor reset On-Off";
CM_ SG_ 117 DoorRiReHndlHMIStsReserved1 "Signal Utilized to communicate to HMI subsystem the following specific events in Right Rear door
Handle retract over timed On-Off
Handle deploy over timed On-Off
Unsuccessful  Hall sensor reset On-Off";
CM_ SG_ 117 DoorRiReHndlHMIStsRetractOverTmd "Signal Utilized to communicate to HMI subsystem the following specific events in Right Rear door
Handle retract over timed On-Off
Handle deploy over timed On-Off
Unsuccessful  Hall sensor reset On-Off";
CM_ SG_ 117 DoorRiReHndlHMIStsUnsScsHallSnsr "Signal Utilized to communicate to HMI subsystem the following specific events in Right Rear door
Handle retract over timed On-Off
Handle deploy over timed On-Off
Unsuccessful  Hall sensor reset On-Off";
CM_ SG_ 117 DoorRiReHndlSts "To inform about right rear door handle status, i.e. unknown, opened, closed according to
DoorRiReHndlSts
- Ukwn
- FullRtrctd
- MovgOut
- StopDurgDply
- FullDplyd
- MovgIn
- StopDurgRtrct
- Flt";
CM_ SG_ 117 DoorRiReLatPawlSt "Used to indicate if the Right Rear door actuator must be triggered based in the pawl switch status AND other conditions from Right Rear door latch. [Close] Door is fully closed, the Pawl switch has changed value to PSD and timer to reach ajar is out without reaching ajar. [Open] Pawl Switch has not changed status to [PSD] OR latch successfully reach Ajar position within time. [Undefined] Not enough information about Pawl Switch status is found";
CM_ SG_ 117 DoorRiReLatPosn "Right rear door Cinch position. x01 equal fully open, x02 equal secondary position, x03 equal fully closed.";
CM_ SG_ 117 DoorRiReLockSts "DoorRiReLockSts - Right Rear Door Lock Status
Lock status
LockStsUkwn - Lock Status Unknown
Unlckd - Unlocked
Lockd - Locked
SafeLockd - Safe Locked (Double Locked)";
CM_ SG_ 117 DoorRiReOpenLowReqOutdSwt1 "DoorRiReOpenLowReqOutdSwt1 - Right Rear Door Open Request from Outside Switch 1 - Traditional door (No Power operated). Button status of the outside Right Rear door handle switch connection 1.
Psd - Pressed
NotPsd - Not Pressed
NoInfo1/2 - Invalid";
CM_ SG_ 117 DoorRiReOpenReqInsdSwt1 "DoorDrvrOpenReqInsdSwt1 - Right rear Open Request from Inside Switch 1
Button status of the inside Right rear door handle switch connection 1
Psd - Pressed
NotPsd - Not Pressed
NoInfo1/2 - Invalid";
CM_ SG_ 117 DoorRiReRelsFailCinchOverTimed "Cinch processwas not successfull. It is overtimed.";
CM_ SG_ 117 DoorRiReRelsFailFailure1 "Issue described by requiremnt according to specific project";
CM_ SG_ 117 DoorRiReRelsFailMechRels "Door Mechanical release (No Power operated)";
CM_ SG_ 117 DoorRiReSwtLockgSts "DoorRiReSwtLockgSts - Right Rear Door Locking Switch Status
Status of the right rear door interior locking switch
Psd - Pressed
NotPsd - Not Pressed";
CM_ SG_ 117 PassSeatRemCtrlReDoorRiActrIncSt "Door Switch for First Row Passenger Seat Inclination (Backrest) Adjustment";
CM_ SG_ 117 PassSeatRemCtrlReDoorRiActrSldSt "Door Switch for First Row Passenger Seat Slide (Length) Adjustment";
CM_ SG_ 117 ShortDropWinReRiSts "Short drop a status sent back to locking to secure window is down and door is ready to be released. ";
CM_ SG_ 117 WinDsblRightSts "Signal sent from the rear passenger door module to the Driver door module that informs of the local status of the power window disable functionality.
";
CM_ SG_ 117 WinFailrStsAtReRi "Report failure if Window motor is not possible to Run";
CM_ SG_ 117 WinPosnStsAtReRi "Signal sent to inform the rest of the car of the window position status for the rear passenger side door. The value of the signal is either an approximated percentage of openness, of the window is moving or if the position is unkown.
";
CM_ SG_ 117 WinPosReqReLe "Request to move Rear Left window from RRDM";
CM_ SG_ 102 ElecChromWinAtReRiFailr "dimming system failure for rear right window";
CM_ SG_ 102 ElecChromWinAtReRiFb "transparency feedback signal from rear right window";
CM_ SG_ 1360 VFCVectorRRDMBlockID "Block Identifier";
CM_ SG_ 1360 VFCVectorRRDMVFCid0 "VFC0";
CM_ SG_ 1360 VFCVectorRRDMVFCid1 "VFC1";
CM_ SG_ 1360 VFCVectorRRDMVFCid10 "VFC10";
CM_ SG_ 1360 VFCVectorRRDMVFCid11 "VFC11";
CM_ SG_ 1360 VFCVectorRRDMVFCid12 "VFC12";
CM_ SG_ 1360 VFCVectorRRDMVFCid13 "VFC13";
CM_ SG_ 1360 VFCVectorRRDMVFCid14 "VFC14";
CM_ SG_ 1360 VFCVectorRRDMVFCid15 "VFC15";
CM_ SG_ 1360 VFCVectorRRDMVFCid16 "VFC16";
CM_ SG_ 1360 VFCVectorRRDMVFCid17 "VFC17";
CM_ SG_ 1360 VFCVectorRRDMVFCid18 "VFC18";
CM_ SG_ 1360 VFCVectorRRDMVFCid19 "VFC19";
CM_ SG_ 1360 VFCVectorRRDMVFCid2 "VFC2";
CM_ SG_ 1360 VFCVectorRRDMVFCid20 "VFC20";
CM_ SG_ 1360 VFCVectorRRDMVFCid21 "VFC21";
CM_ SG_ 1360 VFCVectorRRDMVFCid22 "VFC22";
CM_ SG_ 1360 VFCVectorRRDMVFCid23 "VFC23";
CM_ SG_ 1360 VFCVectorRRDMVFCid24 "VFC24";
CM_ SG_ 1360 VFCVectorRRDMVFCid25 "VFC25";
CM_ SG_ 1360 VFCVectorRRDMVFCid26 "VFC26";
CM_ SG_ 1360 VFCVectorRRDMVFCid27 "VFC27";
CM_ SG_ 1360 VFCVectorRRDMVFCid28 "VFC28";
CM_ SG_ 1360 VFCVectorRRDMVFCid29 "VFC29";
CM_ SG_ 1360 VFCVectorRRDMVFCid3 "VFC3";
CM_ SG_ 1360 VFCVectorRRDMVFCid30 "VFC30";
CM_ SG_ 1360 VFCVectorRRDMVFCid31 "VFC31";
CM_ SG_ 1360 VFCVectorRRDMVFCid32 "VFC32";
CM_ SG_ 1360 VFCVectorRRDMVFCid33 "VFC33";
CM_ SG_ 1360 VFCVectorRRDMVFCid34 "VFC34";
CM_ SG_ 1360 VFCVectorRRDMVFCid35 "VFC35";
CM_ SG_ 1360 VFCVectorRRDMVFCid36 "VFC36";
CM_ SG_ 1360 VFCVectorRRDMVFCid37 "VFC37";
CM_ SG_ 1360 VFCVectorRRDMVFCid38 "VFC38";
CM_ SG_ 1360 VFCVectorRRDMVFCid39 "VFC39";
CM_ SG_ 1360 VFCVectorRRDMVFCid4 "VFC4";
CM_ SG_ 1360 VFCVectorRRDMVFCid40 "VFC40";
CM_ SG_ 1360 VFCVectorRRDMVFCid41 "VFC41";
CM_ SG_ 1360 VFCVectorRRDMVFCid42 "VFC42";
CM_ SG_ 1360 VFCVectorRRDMVFCid43 "VFC43";
CM_ SG_ 1360 VFCVectorRRDMVFCid44 "VFC44";
CM_ SG_ 1360 VFCVectorRRDMVFCid45 "VFC45";
CM_ SG_ 1360 VFCVectorRRDMVFCid46 "VFC46";
CM_ SG_ 1360 VFCVectorRRDMVFCid47 "VFC47";
CM_ SG_ 1360 VFCVectorRRDMVFCid48 "VFC48";
CM_ SG_ 1360 VFCVectorRRDMVFCid49 "VFC49";
CM_ SG_ 1360 VFCVectorRRDMVFCid5 "VFC5";
CM_ SG_ 1360 VFCVectorRRDMVFCid50 "VFC50";
CM_ SG_ 1360 VFCVectorRRDMVFCid51 "VFC51";
CM_ SG_ 1360 VFCVectorRRDMVFCid52 "VFC52";
CM_ SG_ 1360 VFCVectorRRDMVFCid53 "VFC53";
CM_ SG_ 1360 VFCVectorRRDMVFCid54 "VFC54";
CM_ SG_ 1360 VFCVectorRRDMVFCid55 "VFC55";
CM_ SG_ 1360 VFCVectorRRDMVFCid56 "VFC56";
CM_ SG_ 1360 VFCVectorRRDMVFCid57 "VFC57";
CM_ SG_ 1360 VFCVectorRRDMVFCid58 "VFC58";
CM_ SG_ 1360 VFCVectorRRDMVFCid59 "VFC59";
CM_ SG_ 1360 VFCVectorRRDMVFCid6 "VFC6";
CM_ SG_ 1360 VFCVectorRRDMVFCid60 "VFC60";
CM_ SG_ 1360 VFCVectorRRDMVFCid61 "VFC61";
CM_ SG_ 1360 VFCVectorRRDMVFCid7 "VFC7";
CM_ SG_ 1360 VFCVectorRRDMVFCid8 "VFC8";
CM_ SG_ 1360 VFCVectorRRDMVFCid9 "VFC9";
CM_ SG_ 1430 SMDdevelpsignalgrouprespFunction "develop signal group response";
CM_ SG_ 1430 SMDdevelpsignalgrouprespFun_0000 "develop signal group response";
CM_ SG_ 1430 SMDdevelpsignalgrouprespFun_0001 "develop signal group response";
CM_ SG_ 1430 SMDdevelpsignalgrouprespFun_0002 "develop signal group response";
CM_ SG_ 1430 SMDdevelpsignalgrouprespFun_0003 "develop signal group response";
CM_ SG_ 1430 SMDdevelpsignalgrouprespFun_0004 "develop signal group response";
CM_ SG_ 1430 SMDdevelpsignalgrouprespFun_0005 "develop signal group response";
CM_ SG_ 1430 SMDdevelpsignalgrouprespFun_0006 "develop signal group response";
CM_ SG_ 105 DrvrCtrlOfPassSeatFrntSts "Activate remote control in passenger seat";
CM_ SG_ 105 DrvrSeatBtnPsd "The signal DrvrSeatBtnPsd shall be sent when any button connected to the PSM is activated. ";
CM_ SG_ 105 DrvrSeatInAutMovmt "Driver Seat in Automatic Movement";
CM_ SG_ 105 DrvrSeatMemSts "First Row Driver Seat Memory Status";
CM_ SG_ 105 DrvrSeatVentnActlPwrCns "Actual driver seat ventilation power consumption.";
CM_ SG_ 105 DrvrSeatVentnDesPwrCns "Desired driver seat ventilation power consumption.";
CM_ SG_ 105 SeatBackAngleRowFirstDrvr "Backrest angle of the First Row Driver Seat";
CM_ SG_ 864 DrvrSeatHallPosDownLdSts "Driver Seat Hall Position Download Status";
CM_ SG_ 864 DrvrSeatHallPosExtUpldSeatCushEx "Seat Cushion Extension Position";
CM_ SG_ 864 DrvrSeatHallPosExtUpldSeatHeadrH "Seat Headrest Horizontal Position";
CM_ SG_ 864 DrvrSeatHallPosExtUpldSeatHeadrV "Seat Headrest Vertical Position";
CM_ SG_ 1193 DrvrSeatHallPosUpldSeatFrntHeiPo "Seat Front Height Position";
CM_ SG_ 1193 DrvrSeatHallPosUpldSeatHeiPos "Seat Height Position";
CM_ SG_ 1193 DrvrSeatHallPosUpldSeatInclPos "Seat Inclanation Position";
CM_ SG_ 1193 DrvrSeatHallPosUpldSeatSldPos "Seat Slide Position";
CM_ SG_ 665 DrvrMassgRunng "Gateway to CAN from Seat ECU of the Massage Module feedback signal if massage funcitonality is currently running.";
CM_ SG_ 665 DrvrSeatActvSpplFct "Selected Multifunction";
CM_ SG_ 665 DrvrSeatHeatgActlPwrCns "Actual power consumption for driver seat climate, including ventilation and heating.";
CM_ SG_ 665 DrvrSeatHeatgAvlSts "Seat heating on, off, error and limitation status for driver seat.";
CM_ SG_ 665 DrvrSeatHeatgDesPwrCns "Desired power consumption for driver seat climate, including ventilation and heating.";
CM_ SG_ 665 DrvrSeatHeatgLvlSts "Seat heating level for first row driver seat.";
CM_ SG_ 665 DrvrSeatMassgFctReq "Driver Seat One Key Massage Function Request";
CM_ SG_ 665 DrvrSeatSwtStsDrvrSeatSwtAdjmtOf "Horizontal Multifunction";
CM_ SG_ 665 DrvrSeatSwtStsDrvrSeatSwtAd_0000 "Vertical Multifunction";
CM_ SG_ 665 DrvrSeatSwtStsDrvrSeatSwtHdrstHo "Headrest Horizontal Status";
CM_ SG_ 665 DrvrSeatSwtStsDrvrSeatSwtHdrstVe "Headrest Vertical Status";
CM_ SG_ 665 DrvrSeatSwtStsDrvrSeatSwtHeiFrnt "Front Height Stauts";
CM_ SG_ 665 DrvrSeatSwtStsDrvrSeatSwtHeiSts "Height Stauts";
CM_ SG_ 665 DrvrSeatSwtStsDrvrSeatSwtInclSts "Inclination Stauts";
CM_ SG_ 665 DrvrSeatSwtStsDrvrSeatSwtSelnOfS "Selector Multifunction";
CM_ SG_ 665 DrvrSeatSwtStsDrvrSeatSwtSldSts "Slide Stauts";
CM_ SG_ 665 DrvrSeatVentAvlSts "Seat ventilation on, off, error and limitation status for driver seat.";
CM_ SG_ 665 DrvrSeatVentnLvlSts "Seat ventilation level for first row driver seat.";
CM_ SG_ 272 DrvrSeatExtAdjAllowd "External Adjustment of the Driver seat is allowed or not (from for example HMI)";
CM_ SG_ 272 DrvrSeatPosPercSeatPosFrntHeiPer "Front Height Position Percentage";
CM_ SG_ 272 DrvrSeatPosPercSeatPosFrntHeiQF "Front Height Position Quality Factor";
CM_ SG_ 272 DrvrSeatPosPercSeatPosHeiPerc "Height Position Percentage";
CM_ SG_ 272 DrvrSeatPosPercSeatPosHeiQF "Height Position Quality Factor";
CM_ SG_ 272 DrvrSeatPosPercSeatPosSldPerc "Length Position Percentage";
CM_ SG_ 272 DrvrSeatPosPercSeatPosSldQF "Length Position Quality Factor";
CM_ SG_ 547 DrvrSeatActvSwtFctMod "Driver Seat Active Integrated Switch Mode";
CM_ SG_ 547 DrvrSeatIntgrSwtStsIntgrSwtHozlS "Seat Integrated Horizontal Switch Status";
CM_ SG_ 547 DrvrSeatIntgrSwtStsIntgrSwtRotSt "Seat Integrated Rotary Switch Status";
CM_ SG_ 547 DrvrSeatIntgrSwtStsIntgrSwtSelnS "Seat Integrated Selector Switch Status";
CM_ SG_ 547 DrvrSeatIntgrSwtStsIntgrSwtVertS "Seat Integrated Vertical Switch Status";
CM_ SG_ 547 DrvrSeatPivtPosPercSeatPosPerc "Seat Pivoting Position Percentage";
CM_ SG_ 547 DrvrSeatPivtPosPercSeatPosQf "Seat Pivoting Position Quality Factor";
CM_ SG_ 547 DrvrSeatSwtBlstrSts "Driver Seat Bolster Switch Status";
CM_ SG_ 547 DrvrSeatSwtCushExtSts "Driver Seat Cushion Extension Switch Status";
CM_ SG_ 1362 VFCVectorSMDBlockID "Block Identifier";
CM_ SG_ 1362 VFCVectorSMDVFCid0 "VFC0";
CM_ SG_ 1362 VFCVectorSMDVFCid1 "VFC1";
CM_ SG_ 1362 VFCVectorSMDVFCid10 "VFC10";
CM_ SG_ 1362 VFCVectorSMDVFCid11 "VFC11";
CM_ SG_ 1362 VFCVectorSMDVFCid12 "VFC12";
CM_ SG_ 1362 VFCVectorSMDVFCid13 "VFC13";
CM_ SG_ 1362 VFCVectorSMDVFCid14 "VFC14";
CM_ SG_ 1362 VFCVectorSMDVFCid15 "VFC15";
CM_ SG_ 1362 VFCVectorSMDVFCid16 "VFC16";
CM_ SG_ 1362 VFCVectorSMDVFCid17 "VFC17";
CM_ SG_ 1362 VFCVectorSMDVFCid18 "VFC18";
CM_ SG_ 1362 VFCVectorSMDVFCid19 "VFC19";
CM_ SG_ 1362 VFCVectorSMDVFCid2 "VFC2";
CM_ SG_ 1362 VFCVectorSMDVFCid20 "VFC20";
CM_ SG_ 1362 VFCVectorSMDVFCid21 "VFC21";
CM_ SG_ 1362 VFCVectorSMDVFCid22 "VFC22";
CM_ SG_ 1362 VFCVectorSMDVFCid23 "VFC23";
CM_ SG_ 1362 VFCVectorSMDVFCid24 "VFC24";
CM_ SG_ 1362 VFCVectorSMDVFCid25 "VFC25";
CM_ SG_ 1362 VFCVectorSMDVFCid26 "VFC26";
CM_ SG_ 1362 VFCVectorSMDVFCid27 "VFC27";
CM_ SG_ 1362 VFCVectorSMDVFCid28 "VFC28";
CM_ SG_ 1362 VFCVectorSMDVFCid29 "VFC29";
CM_ SG_ 1362 VFCVectorSMDVFCid3 "VFC3";
CM_ SG_ 1362 VFCVectorSMDVFCid30 "VFC30";
CM_ SG_ 1362 VFCVectorSMDVFCid31 "VFC31";
CM_ SG_ 1362 VFCVectorSMDVFCid32 "VFC32";
CM_ SG_ 1362 VFCVectorSMDVFCid33 "VFC33";
CM_ SG_ 1362 VFCVectorSMDVFCid34 "VFC34";
CM_ SG_ 1362 VFCVectorSMDVFCid35 "VFC35";
CM_ SG_ 1362 VFCVectorSMDVFCid36 "VFC36";
CM_ SG_ 1362 VFCVectorSMDVFCid37 "VFC37";
CM_ SG_ 1362 VFCVectorSMDVFCid38 "VFC38";
CM_ SG_ 1362 VFCVectorSMDVFCid39 "VFC39";
CM_ SG_ 1362 VFCVectorSMDVFCid4 "VFC4";
CM_ SG_ 1362 VFCVectorSMDVFCid40 "VFC40";
CM_ SG_ 1362 VFCVectorSMDVFCid41 "VFC41";
CM_ SG_ 1362 VFCVectorSMDVFCid42 "VFC42";
CM_ SG_ 1362 VFCVectorSMDVFCid43 "VFC43";
CM_ SG_ 1362 VFCVectorSMDVFCid44 "VFC44";
CM_ SG_ 1362 VFCVectorSMDVFCid45 "VFC45";
CM_ SG_ 1362 VFCVectorSMDVFCid46 "VFC46";
CM_ SG_ 1362 VFCVectorSMDVFCid47 "VFC47";
CM_ SG_ 1362 VFCVectorSMDVFCid48 "VFC48";
CM_ SG_ 1362 VFCVectorSMDVFCid49 "VFC49";
CM_ SG_ 1362 VFCVectorSMDVFCid5 "VFC5";
CM_ SG_ 1362 VFCVectorSMDVFCid50 "VFC50";
CM_ SG_ 1362 VFCVectorSMDVFCid51 "VFC51";
CM_ SG_ 1362 VFCVectorSMDVFCid52 "VFC52";
CM_ SG_ 1362 VFCVectorSMDVFCid53 "VFC53";
CM_ SG_ 1362 VFCVectorSMDVFCid54 "VFC54";
CM_ SG_ 1362 VFCVectorSMDVFCid55 "VFC55";
CM_ SG_ 1362 VFCVectorSMDVFCid56 "VFC56";
CM_ SG_ 1362 VFCVectorSMDVFCid57 "VFC57";
CM_ SG_ 1362 VFCVectorSMDVFCid58 "VFC58";
CM_ SG_ 1362 VFCVectorSMDVFCid59 "VFC59";
CM_ SG_ 1362 VFCVectorSMDVFCid6 "VFC6";
CM_ SG_ 1362 VFCVectorSMDVFCid60 "VFC60";
CM_ SG_ 1362 VFCVectorSMDVFCid61 "VFC61";
CM_ SG_ 1362 VFCVectorSMDVFCid7 "VFC7";
CM_ SG_ 1362 VFCVectorSMDVFCid8 "VFC8";
CM_ SG_ 1362 VFCVectorSMDVFCid9 "VFC9";
CM_ SG_ 1431 SMPdevelpsignalgrouprespFunction "develop signal group response";
CM_ SG_ 1431 SMPdevelpsignalgrouprespFun_0000 "develop signal group response";
CM_ SG_ 1431 SMPdevelpsignalgrouprespFun_0001 "develop signal group response";
CM_ SG_ 1431 SMPdevelpsignalgrouprespFun_0002 "develop signal group response";
CM_ SG_ 1431 SMPdevelpsignalgrouprespFun_0003 "develop signal group response";
CM_ SG_ 1431 SMPdevelpsignalgrouprespFun_0004 "develop signal group response";
CM_ SG_ 1431 SMPdevelpsignalgrouprespFun_0005 "develop signal group response";
CM_ SG_ 1431 SMPdevelpsignalgrouprespFun_0006 "develop signal group response";
CM_ SG_ 304 PassSeatBtnPsd "The signal PassSeatBtnPsd shall be sent when any button connected to the PSM is activated. ";
CM_ SG_ 304 PassSeatHeatgActlPwrCns "Actual power consumption for passenger seat climate, including ventilation and heating.";
CM_ SG_ 304 PassSeatHeatgDesPwrCns "Desired power consumption for passenger seat climate, including ventilation and heating.";
CM_ SG_ 304 PassSeatInAutMovmt "Passenger Seat in Automatic Movement";
CM_ SG_ 304 PassSeatMemSts "First Row Passager Seat Memory Status";
CM_ SG_ 304 PassSeatVentnActlPwrCns "Passenger seat ventilation actual power consumption.";
CM_ SG_ 304 PassSeatVentnDesPwrCns "Passenger seat ventilation desired power consumption.";
CM_ SG_ 275 PassSeatMassgFctReq "Passenger Seat  One Key Massage Request";
CM_ SG_ 275 PassSeatPosPercSeatPosFrntHeiPer "Front Height Position Percentage";
CM_ SG_ 275 PassSeatPosPercSeatPosFrntHeiQF "Front Height Position Quality Factor";
CM_ SG_ 275 PassSeatPosPercSeatPosHeiPerc "Height Position Percentage";
CM_ SG_ 275 PassSeatPosPercSeatPosHeiQF "Height Position Quality Factor";
CM_ SG_ 275 PassSeatPosPercSeatPosSldPerc "Length Position Percentage";
CM_ SG_ 275 PassSeatPosPercSeatPosSldQF "Length Position Quality Factor";
CM_ SG_ 275 SeatBackAngleRowFirstPass "Backrest angle of the First Row Passenger Seat";
CM_ SG_ 1063 PassMassgRunng "Seat Massage Running Row First Passager";
CM_ SG_ 1063 PassSeatActvSpplFct "Passenger Seat Active Multifunction (indicates which function is currently controlled by the multifunction switch)";
CM_ SG_ 1063 PassSeatHeatgAvlSts "Seat heating on, off, error and limitation status for passenger seat.";
CM_ SG_ 1063 PassSeatHeatgLvlSts "Seat heating level for first row passenger seat.";
CM_ SG_ 1063 PassSeatPivtPosPercSeatPosPerc "Seat Pivoting Position Percentage";
CM_ SG_ 1063 PassSeatPivtPosPercSeatPosQf "Seat Pivoting Position Quality Factor";
CM_ SG_ 1063 PassSeatSwtSts2PassSeatSwtAdjmtO "Horizontal Multifunction";
CM_ SG_ 1063 PassSeatSwtSts2PassSeatSwtA_0000 "Vertical Multifunction";
CM_ SG_ 1063 PassSeatSwtSts2PassSeatSwtHdrstH "Headrest Horizontal Status";
CM_ SG_ 1063 PassSeatSwtSts2PassSeatSwtHdrstV "Headrest Vertical Status";
CM_ SG_ 1063 PassSeatSwtSts2PassSeatSwtHeiFrn "Front Height Status";
CM_ SG_ 1063 PassSeatSwtSts2PassSeatSwtHeiSts "Height Status";
CM_ SG_ 1063 PassSeatSwtSts2PassSeatSwtInclSt "Inclination Status";
CM_ SG_ 1063 PassSeatSwtSts2PassSeatSwtSelnOf "Selector Multifunction";
CM_ SG_ 1063 PassSeatSwtSts2PassSeatSwtSldSts "Slide Status";
CM_ SG_ 1063 PassSeatVentAvlSts "Seat ventilation on, off, error and limitation status for passenger seat.";
CM_ SG_ 1063 PassSeatVentnLvlSts "Seat ventilation level for first row passenger seat.";
CM_ SG_ 1063 RowFrstPassODSSts "Passenger Seat Occupant Detection Sensor Status CAN signal";
CM_ SG_ 538 PassSeatActvSwtFctMod "Passenger Seat Active Integrated Switch Mode";
CM_ SG_ 538 PassSeatIntgrSwtStsIntgrSwtHozlS "Seat Integrated Horizontal Switch Status";
CM_ SG_ 538 PassSeatIntgrSwtStsIntgrSwtRotSt "Seat Integrated Rotary Switch Status";
CM_ SG_ 538 PassSeatIntgrSwtStsIntgrSwtSelnS "Seat Integrated Selector Switch Status";
CM_ SG_ 538 PassSeatIntgrSwtStsIntgrSwtVertS "Seat Integrated Vertical Switch Status";
CM_ SG_ 538 PassSeatSwtBlstrSts "Passenger Seat Bolster Switch Status";
CM_ SG_ 538 PassSeatSwtCushExtSts "Passenger Seat Cushion Extension Switch Status";
CM_ SG_ 1363 VFCVectorSMPBlockID "Block Identifier";
CM_ SG_ 1363 VFCVectorSMPVFCid0 "VFC0";
CM_ SG_ 1363 VFCVectorSMPVFCid1 "VFC1";
CM_ SG_ 1363 VFCVectorSMPVFCid10 "VFC10";
CM_ SG_ 1363 VFCVectorSMPVFCid11 "VFC11";
CM_ SG_ 1363 VFCVectorSMPVFCid12 "VFC12";
CM_ SG_ 1363 VFCVectorSMPVFCid13 "VFC13";
CM_ SG_ 1363 VFCVectorSMPVFCid14 "VFC14";
CM_ SG_ 1363 VFCVectorSMPVFCid15 "VFC15";
CM_ SG_ 1363 VFCVectorSMPVFCid16 "VFC16";
CM_ SG_ 1363 VFCVectorSMPVFCid17 "VFC17";
CM_ SG_ 1363 VFCVectorSMPVFCid18 "VFC18";
CM_ SG_ 1363 VFCVectorSMPVFCid19 "VFC19";
CM_ SG_ 1363 VFCVectorSMPVFCid2 "VFC2";
CM_ SG_ 1363 VFCVectorSMPVFCid20 "VFC20";
CM_ SG_ 1363 VFCVectorSMPVFCid21 "VFC21";
CM_ SG_ 1363 VFCVectorSMPVFCid22 "VFC22";
CM_ SG_ 1363 VFCVectorSMPVFCid23 "VFC23";
CM_ SG_ 1363 VFCVectorSMPVFCid24 "VFC24";
CM_ SG_ 1363 VFCVectorSMPVFCid25 "VFC25";
CM_ SG_ 1363 VFCVectorSMPVFCid26 "VFC26";
CM_ SG_ 1363 VFCVectorSMPVFCid27 "VFC27";
CM_ SG_ 1363 VFCVectorSMPVFCid28 "VFC28";
CM_ SG_ 1363 VFCVectorSMPVFCid29 "VFC29";
CM_ SG_ 1363 VFCVectorSMPVFCid3 "VFC3";
CM_ SG_ 1363 VFCVectorSMPVFCid30 "VFC30";
CM_ SG_ 1363 VFCVectorSMPVFCid31 "VFC31";
CM_ SG_ 1363 VFCVectorSMPVFCid32 "VFC32";
CM_ SG_ 1363 VFCVectorSMPVFCid33 "VFC33";
CM_ SG_ 1363 VFCVectorSMPVFCid34 "VFC34";
CM_ SG_ 1363 VFCVectorSMPVFCid35 "VFC35";
CM_ SG_ 1363 VFCVectorSMPVFCid36 "VFC36";
CM_ SG_ 1363 VFCVectorSMPVFCid37 "VFC37";
CM_ SG_ 1363 VFCVectorSMPVFCid38 "VFC38";
CM_ SG_ 1363 VFCVectorSMPVFCid39 "VFC39";
CM_ SG_ 1363 VFCVectorSMPVFCid4 "VFC4";
CM_ SG_ 1363 VFCVectorSMPVFCid40 "VFC40";
CM_ SG_ 1363 VFCVectorSMPVFCid41 "VFC41";
CM_ SG_ 1363 VFCVectorSMPVFCid42 "VFC42";
CM_ SG_ 1363 VFCVectorSMPVFCid43 "VFC43";
CM_ SG_ 1363 VFCVectorSMPVFCid44 "VFC44";
CM_ SG_ 1363 VFCVectorSMPVFCid45 "VFC45";
CM_ SG_ 1363 VFCVectorSMPVFCid46 "VFC46";
CM_ SG_ 1363 VFCVectorSMPVFCid47 "VFC47";
CM_ SG_ 1363 VFCVectorSMPVFCid48 "VFC48";
CM_ SG_ 1363 VFCVectorSMPVFCid49 "VFC49";
CM_ SG_ 1363 VFCVectorSMPVFCid5 "VFC5";
CM_ SG_ 1363 VFCVectorSMPVFCid50 "VFC50";
CM_ SG_ 1363 VFCVectorSMPVFCid51 "VFC51";
CM_ SG_ 1363 VFCVectorSMPVFCid52 "VFC52";
CM_ SG_ 1363 VFCVectorSMPVFCid53 "VFC53";
CM_ SG_ 1363 VFCVectorSMPVFCid54 "VFC54";
CM_ SG_ 1363 VFCVectorSMPVFCid55 "VFC55";
CM_ SG_ 1363 VFCVectorSMPVFCid56 "VFC56";
CM_ SG_ 1363 VFCVectorSMPVFCid57 "VFC57";
CM_ SG_ 1363 VFCVectorSMPVFCid58 "VFC58";
CM_ SG_ 1363 VFCVectorSMPVFCid59 "VFC59";
CM_ SG_ 1363 VFCVectorSMPVFCid6 "VFC6";
CM_ SG_ 1363 VFCVectorSMPVFCid60 "VFC60";
CM_ SG_ 1363 VFCVectorSMPVFCid61 "VFC61";
CM_ SG_ 1363 VFCVectorSMPVFCid7 "VFC7";
CM_ SG_ 1363 VFCVectorSMPVFCid8 "VFC8";
CM_ SG_ 1363 VFCVectorSMPVFCid9 "VFC9";
CM_ SG_ 208 TrlrFogLiSts "Trailer fog lights on/off status.";
CM_ SG_ 208 TrlrLampActvtChk "TrlrLampActvtChkNotAvl - Disable trailer lamp check.
TrlrLampActvtChkAvl - Enable trailer lamp check.";
CM_ SG_ 208 TrlrLampChkSts "TrlrLampChkStrtd - Trailer lamp check started.
TrlrLampChkCmpl - Trailer lamp check Completed.
CnclOper - Cancelled operation by user.
TrlrLampEngOffReqd - Required user to turn off the engine.
Resd1/2/3 - Reserved1/2/3.";
CM_ SG_ 208 TrlrLeIndcrFltSts "No Flt - Left DI works well.
Flt - Left DI is in fault status.";
CM_ SG_ 208 TrlrLiFltSts "0 - Brake light and both DIs work well.
1 - Right DI is in failure status.
2 - Left DI is in failure status.
3 - Both DIs are in failure status.
4 - Brake light is in failure status.
5 - Brake light and right DI are in failure status.
6 - Brake light and left DI are in failure status.
7 - Brake light and both DIs are in failure status.";
CM_ SG_ 208 TrlrPrmntPwrActv "YES - Power supply with KL-30.
NO - Power off.";
CM_ SG_ 208 TrlrPrsnt "TrlrNotPrsnt - Trailer caravan is not connected to the vehicle.
TrlrPrsnt - Trailer caravan is connected to the vehicle.";
CM_ SG_ 208 TrlrRiIndcrFltSts "No Flt - Right DI works well.
Flt - Right DI is in fault status.";
CM_ SG_ 208 TrlrSrvReq "No Flt - Towbar release button works well.
Flt - Towba release button is stuck.";
CM_ SG_ 145 TrlrBrkLiSts "Trailer brake lights on/off status.";
CM_ SG_ 145 TrlrIndcrTurnSts "Trailer direction indicators on/off status.";
CM_ SG_ 145 TrlrPosnLiSts "Trailer position lights on/off status.";
CM_ SG_ 145 TrlrRvsgLiSts "Trailer reversing light on/off status.";
CM_ SG_ 145 TwbrLockdPosn "To indicate if the towbar is in locked position.";
CM_ SG_ 145 TwbrWarnStsChks "Checksum";
CM_ SG_ 145 TwbrWarnStsCntr "Counter";
CM_ SG_ 145 TwbrWarnStsYesNo "To inform the driver if electrical-towbar is released by accident during driving.";
CM_ SG_ 1365 VFCVectorTRMBlockID "Block Identifier";
CM_ SG_ 1365 VFCVectorTRMVFCid0 "VFC0";
CM_ SG_ 1365 VFCVectorTRMVFCid1 "VFC1";
CM_ SG_ 1365 VFCVectorTRMVFCid10 "VFC10";
CM_ SG_ 1365 VFCVectorTRMVFCid11 "VFC11";
CM_ SG_ 1365 VFCVectorTRMVFCid12 "VFC12";
CM_ SG_ 1365 VFCVectorTRMVFCid13 "VFC13";
CM_ SG_ 1365 VFCVectorTRMVFCid14 "VFC14";
CM_ SG_ 1365 VFCVectorTRMVFCid15 "VFC15";
CM_ SG_ 1365 VFCVectorTRMVFCid16 "VFC16";
CM_ SG_ 1365 VFCVectorTRMVFCid17 "VFC17";
CM_ SG_ 1365 VFCVectorTRMVFCid18 "VFC18";
CM_ SG_ 1365 VFCVectorTRMVFCid19 "VFC19";
CM_ SG_ 1365 VFCVectorTRMVFCid2 "VFC2";
CM_ SG_ 1365 VFCVectorTRMVFCid20 "VFC20";
CM_ SG_ 1365 VFCVectorTRMVFCid21 "VFC21";
CM_ SG_ 1365 VFCVectorTRMVFCid22 "VFC22";
CM_ SG_ 1365 VFCVectorTRMVFCid23 "VFC23";
CM_ SG_ 1365 VFCVectorTRMVFCid24 "VFC24";
CM_ SG_ 1365 VFCVectorTRMVFCid25 "VFC25";
CM_ SG_ 1365 VFCVectorTRMVFCid26 "VFC26";
CM_ SG_ 1365 VFCVectorTRMVFCid27 "VFC27";
CM_ SG_ 1365 VFCVectorTRMVFCid28 "VFC28";
CM_ SG_ 1365 VFCVectorTRMVFCid29 "VFC29";
CM_ SG_ 1365 VFCVectorTRMVFCid3 "VFC3";
CM_ SG_ 1365 VFCVectorTRMVFCid30 "VFC30";
CM_ SG_ 1365 VFCVectorTRMVFCid31 "VFC31";
CM_ SG_ 1365 VFCVectorTRMVFCid32 "VFC32";
CM_ SG_ 1365 VFCVectorTRMVFCid33 "VFC33";
CM_ SG_ 1365 VFCVectorTRMVFCid34 "VFC34";
CM_ SG_ 1365 VFCVectorTRMVFCid35 "VFC35";
CM_ SG_ 1365 VFCVectorTRMVFCid36 "VFC36";
CM_ SG_ 1365 VFCVectorTRMVFCid37 "VFC37";
CM_ SG_ 1365 VFCVectorTRMVFCid38 "VFC38";
CM_ SG_ 1365 VFCVectorTRMVFCid39 "VFC39";
CM_ SG_ 1365 VFCVectorTRMVFCid4 "VFC4";
CM_ SG_ 1365 VFCVectorTRMVFCid40 "VFC40";
CM_ SG_ 1365 VFCVectorTRMVFCid41 "VFC41";
CM_ SG_ 1365 VFCVectorTRMVFCid42 "VFC42";
CM_ SG_ 1365 VFCVectorTRMVFCid43 "VFC43";
CM_ SG_ 1365 VFCVectorTRMVFCid44 "VFC44";
CM_ SG_ 1365 VFCVectorTRMVFCid45 "VFC45";
CM_ SG_ 1365 VFCVectorTRMVFCid46 "VFC46";
CM_ SG_ 1365 VFCVectorTRMVFCid47 "VFC47";
CM_ SG_ 1365 VFCVectorTRMVFCid48 "VFC48";
CM_ SG_ 1365 VFCVectorTRMVFCid49 "VFC49";
CM_ SG_ 1365 VFCVectorTRMVFCid5 "VFC5";
CM_ SG_ 1365 VFCVectorTRMVFCid50 "VFC50";
CM_ SG_ 1365 VFCVectorTRMVFCid51 "VFC51";
CM_ SG_ 1365 VFCVectorTRMVFCid52 "VFC52";
CM_ SG_ 1365 VFCVectorTRMVFCid53 "VFC53";
CM_ SG_ 1365 VFCVectorTRMVFCid54 "VFC54";
CM_ SG_ 1365 VFCVectorTRMVFCid55 "VFC55";
CM_ SG_ 1365 VFCVectorTRMVFCid56 "VFC56";
CM_ SG_ 1365 VFCVectorTRMVFCid57 "VFC57";
CM_ SG_ 1365 VFCVectorTRMVFCid58 "VFC58";
CM_ SG_ 1365 VFCVectorTRMVFCid59 "VFC59";
CM_ SG_ 1365 VFCVectorTRMVFCid6 "VFC6";
CM_ SG_ 1365 VFCVectorTRMVFCid60 "VFC60";
CM_ SG_ 1365 VFCVectorTRMVFCid61 "VFC61";
CM_ SG_ 1365 VFCVectorTRMVFCid7 "VFC7";
CM_ SG_ 1365 VFCVectorTRMVFCid8 "VFC8";
CM_ SG_ 1365 VFCVectorTRMVFCid9 "VFC9";
BA_DEF_ BO_  "GenMsgSendType" ENUM  "cyclic","spontaneous","not-used","not-used","not-used","cyclicAndSpontaneous","not-used","cyclicIfActive","NoMsgSendType";
BA_DEF_ BO_  "GenMsgCycleTime" INT 0 65536;
BA_DEF_ BO_  "GenMsgStartDelayTime" INT 0 65536;
BA_DEF_ BO_  "GenMsgDelayTime" INT 0 65536;
BA_DEF_ SG_  "GenSigSendType" ENUM  "Cyclic","OnWrite","OnWriteWithRepetition","OnChange","OnChangeWithRepetition","IfActive","IfActiveWithRepetition","NoSigSendType";
BA_DEF_ SG_  "GenSigStartValue" HEX 0 80000000;
BA_DEF_ BO_  "GenMsgILSupport" ENUM  "No","Yes";
BA_DEF_ BO_  "NmAsrMessage" ENUM  "No","Yes";
BA_DEF_ SG_  "GenSigFuncType" ENUM  "NoFunction","n/a","n/a","n/a","n/a","n/a","n/a","n/a","n/a","n/a","n/a","n/a","n/a","n/a","n/a","CHK","CNTR","n/a","n/a","n/a","CNTR_AR_01","CRC_AR_01_BOTH","CRC_AR_01_ALT","CRC_AR_01_LOW","CRC_AR_01_NIBBLE","CNTR_AR_04","CRC_AR_04A","CNTR_AR_05","CRC_AR_05";
BA_DEF_ SG_  "GenSigDataID" STRING ;
BA_DEF_ SG_  "SystemSignalLongSymbol" STRING ;
BA_DEF_DEF_  "GenMsgSendType" "NoMsgSendType";
BA_DEF_DEF_  "GenMsgCycleTime" 0;
BA_DEF_DEF_  "GenMsgStartDelayTime" 0;
BA_DEF_DEF_  "GenMsgDelayTime" 0;
BA_DEF_DEF_  "GenSigSendType" "NoSigSendType";
BA_DEF_DEF_  "GenSigStartValue" 0;
BA_DEF_DEF_  "GenMsgILSupport" "Yes";
BA_DEF_DEF_  "NmAsrMessage" "No";
BA_DEF_DEF_  "GenSigFuncType" "NoFunction";
BA_DEF_DEF_  "GenSigDataID" "";
BA_DEF_DEF_  "SystemSignalLongSymbol" "";
BA_ "GenMsgSendType" BO_ 112 0;
BA_ "GenMsgCycleTime" BO_ 112 30;
BA_ "GenMsgSendType" BO_ 97 0;
BA_ "GenMsgCycleTime" BO_ 97 20;
BA_ "GenMsgSendType" BO_ 1289 1;
BA_ "GenMsgDelayTime" BO_ 1289 20;
BA_ "GenMsgILSupport" BO_ 1289 0;
BA_ "NmAsrMessage" BO_ 1289 1;
BA_ "GenMsgSendType" BO_ 1353 1;
BA_ "GenMsgDelayTime" BO_ 1353 495;
BA_ "GenMsgSendType" BO_ 1569 1;
BA_ "GenMsgDelayTime" BO_ 1569 5;
BA_ "GenMsgSendType" BO_ 1418 1;
BA_ "GenMsgDelayTime" BO_ 1418 5;
BA_ "GenMsgSendType" BO_ 117 0;
BA_ "GenMsgCycleTime" BO_ 117 20;
BA_ "GenMsgSendType" BO_ 102 0;
BA_ "GenMsgCycleTime" BO_ 102 20;
BA_ "GenMsgSendType" BO_ 1296 1;
BA_ "GenMsgDelayTime" BO_ 1296 20;
BA_ "GenMsgILSupport" BO_ 1296 0;
BA_ "NmAsrMessage" BO_ 1296 1;
BA_ "GenMsgSendType" BO_ 1360 1;
BA_ "GenMsgDelayTime" BO_ 1360 495;
BA_ "GenMsgSendType" BO_ 1570 1;
BA_ "GenMsgDelayTime" BO_ 1570 5;
BA_ "GenMsgSendType" BO_ 1419 1;
BA_ "GenMsgDelayTime" BO_ 1419 5;
BA_ "GenMsgSendType" BO_ 1430 1;
BA_ "GenMsgDelayTime" BO_ 1430 95;
BA_ "GenMsgSendType" BO_ 105 0;
BA_ "GenMsgCycleTime" BO_ 105 20;
BA_ "GenMsgSendType" BO_ 864 1;
BA_ "GenMsgDelayTime" BO_ 864 50;
BA_ "GenMsgSendType" BO_ 1193 1;
BA_ "GenMsgDelayTime" BO_ 1193 495;
BA_ "GenMsgSendType" BO_ 665 0;
BA_ "GenMsgCycleTime" BO_ 665 95;
BA_ "GenMsgSendType" BO_ 272 0;
BA_ "GenMsgCycleTime" BO_ 272 70;
BA_ "GenMsgSendType" BO_ 547 0;
BA_ "GenMsgCycleTime" BO_ 547 100;
BA_ "GenMsgSendType" BO_ 1298 1;
BA_ "GenMsgDelayTime" BO_ 1298 20;
BA_ "GenMsgILSupport" BO_ 1298 0;
BA_ "NmAsrMessage" BO_ 1298 1;
BA_ "GenMsgSendType" BO_ 1362 1;
BA_ "GenMsgDelayTime" BO_ 1362 495;
BA_ "GenMsgSendType" BO_ 1575 1;
BA_ "GenMsgDelayTime" BO_ 1575 5;
BA_ "GenMsgSendType" BO_ 1431 1;
BA_ "GenMsgDelayTime" BO_ 1431 95;
BA_ "GenMsgSendType" BO_ 304 0;
BA_ "GenMsgCycleTime" BO_ 304 35;
BA_ "GenMsgSendType" BO_ 275 0;
BA_ "GenMsgCycleTime" BO_ 275 70;
BA_ "GenMsgSendType" BO_ 1063 0;
BA_ "GenMsgCycleTime" BO_ 1063 150;
BA_ "GenMsgSendType" BO_ 538 0;
BA_ "GenMsgCycleTime" BO_ 538 100;
BA_ "GenMsgSendType" BO_ 1299 1;
BA_ "GenMsgDelayTime" BO_ 1299 20;
BA_ "GenMsgILSupport" BO_ 1299 0;
BA_ "NmAsrMessage" BO_ 1299 1;
BA_ "GenMsgSendType" BO_ 1363 1;
BA_ "GenMsgDelayTime" BO_ 1363 495;
BA_ "GenMsgSendType" BO_ 1576 1;
BA_ "GenMsgDelayTime" BO_ 1576 5;
BA_ "GenMsgSendType" BO_ 208 0;
BA_ "GenMsgCycleTime" BO_ 208 60;
BA_ "GenMsgSendType" BO_ 145 0;
BA_ "GenMsgCycleTime" BO_ 145 40;
BA_ "GenMsgSendType" BO_ 1290 1;
BA_ "GenMsgDelayTime" BO_ 1290 20;
BA_ "GenMsgILSupport" BO_ 1290 0;
BA_ "NmAsrMessage" BO_ 1290 1;
BA_ "GenMsgSendType" BO_ 1365 1;
BA_ "GenMsgDelayTime" BO_ 1365 495;
BA_ "GenMsgSendType" BO_ 1559 1;
BA_ "GenMsgDelayTime" BO_ 1559 5;
BA_ "GenMsgSendType" BO_ 1464 1;
BA_ "GenMsgDelayTime" BO_ 1464 10;
BA_ "GenSigSendType" SG_ 112 ChdLockLeftSts 0;
BA_ "GenSigSendType" SG_ 112 DoorLeReCinhIntFailInfCinchFlt1 0;
BA_ "GenSigSendType" SG_ 112 DoorLeReCinhIntFailInfCinchRestF 0;
BA_ "SystemSignalLongSymbol" SG_ 112 DoorLeReCinhIntFailInfCinchRestF "DoorLeReCinhIntFailInfCinchRestFlt";
BA_ "GenSigSendType" SG_ 112 DoorLeReHndlHMIStsDeployedOverTm 0;
BA_ "SystemSignalLongSymbol" SG_ 112 DoorLeReHndlHMIStsDeployedOverTm "DoorLeReHndlHMIStsDeployedOverTmd";
BA_ "GenSigSendType" SG_ 112 DoorLeReHndlHMIStsReserved1 0;
BA_ "GenSigSendType" SG_ 112 DoorLeReHndlHMIStsRetractOverTmd 0;
BA_ "GenSigSendType" SG_ 112 DoorLeReHndlHMIStsUnsScsHallSnsr 0;
BA_ "SystemSignalLongSymbol" SG_ 112 DoorLeReHndlHMIStsUnsScsHallSnsr "DoorLeReHndlHMIStsUnsScsHallSnsrRest";
BA_ "GenSigSendType" SG_ 112 DoorLeReHndlSts 0;
BA_ "GenSigSendType" SG_ 112 DoorLeReLatPawlSt 0;
BA_ "GenSigSendType" SG_ 112 DoorLeReLatPosn 0;
BA_ "GenSigSendType" SG_ 112 DoorLeReLockSts 0;
BA_ "GenSigStartValue" SG_ 112 DoorLeReOpenLowReqOutdSwt1 2;
BA_ "GenSigSendType" SG_ 112 DoorLeReOpenLowReqOutdSwt1 0;
BA_ "GenSigStartValue" SG_ 112 DoorLeReOpenReqInsdSwt1 2;
BA_ "GenSigSendType" SG_ 112 DoorLeReOpenReqInsdSwt1 0;
BA_ "GenSigSendType" SG_ 112 DoorLeReRelsFailCinchOverTimed 0;
BA_ "GenSigSendType" SG_ 112 DoorLeReRelsFailFailure1 0;
BA_ "GenSigSendType" SG_ 112 DoorLeReRelsFailMechRels 0;
BA_ "GenSigSendType" SG_ 112 DoorLeReSwtLockgSts 0;
BA_ "GenSigStartValue" SG_ 112 DoorRiRe2Swt1DplyHndl 1;
BA_ "GenSigSendType" SG_ 112 DoorRiRe2Swt1DplyHndl 0;
BA_ "GenSigSendType" SG_ 112 DoorRiRe2Swt2DplyHndl 0;
BA_ "GenSigSendType" SG_ 112 PassSeatRemCtrlReDoorLeActrIncSt 0;
BA_ "SystemSignalLongSymbol" SG_ 112 PassSeatRemCtrlReDoorLeActrIncSt "PassSeatRemCtrlReDoorLeActrIncSts";
BA_ "GenSigSendType" SG_ 112 PassSeatRemCtrlReDoorLeActrSldSt 0;
BA_ "SystemSignalLongSymbol" SG_ 112 PassSeatRemCtrlReDoorLeActrSldSt "PassSeatRemCtrlReDoorLeActrSldSts";
BA_ "GenSigSendType" SG_ 112 ShortDropWinReLeSts 0;
BA_ "GenSigSendType" SG_ 112 WinDsblLeftSts 0;
BA_ "GenSigSendType" SG_ 112 WinFailrStsAtReLe 0;
BA_ "GenSigSendType" SG_ 112 WinPosnStsAtReLe 0;
BA_ "GenSigSendType" SG_ 112 WinPosReqReRi 0;
BA_ "GenSigSendType" SG_ 1353 VFCVectorRLDMBlockID 1;
BA_ "GenSigSendType" SG_ 1353 VFCVectorRLDMVFCid0 1;
BA_ "GenSigSendType" SG_ 1353 VFCVectorRLDMVFCid1 1;
BA_ "GenSigSendType" SG_ 1353 VFCVectorRLDMVFCid10 1;
BA_ "GenSigSendType" SG_ 1353 VFCVectorRLDMVFCid11 1;
BA_ "GenSigSendType" SG_ 1353 VFCVectorRLDMVFCid12 1;
BA_ "GenSigSendType" SG_ 1353 VFCVectorRLDMVFCid13 1;
BA_ "GenSigSendType" SG_ 1353 VFCVectorRLDMVFCid14 1;
BA_ "GenSigSendType" SG_ 1353 VFCVectorRLDMVFCid15 1;
BA_ "GenSigSendType" SG_ 1353 VFCVectorRLDMVFCid16 1;
BA_ "GenSigSendType" SG_ 1353 VFCVectorRLDMVFCid17 1;
BA_ "GenSigSendType" SG_ 1353 VFCVectorRLDMVFCid18 1;
BA_ "GenSigSendType" SG_ 1353 VFCVectorRLDMVFCid19 1;
BA_ "GenSigSendType" SG_ 1353 VFCVectorRLDMVFCid2 1;
BA_ "GenSigSendType" SG_ 1353 VFCVectorRLDMVFCid20 1;
BA_ "GenSigSendType" SG_ 1353 VFCVectorRLDMVFCid21 1;
BA_ "GenSigSendType" SG_ 1353 VFCVectorRLDMVFCid22 1;
BA_ "GenSigSendType" SG_ 1353 VFCVectorRLDMVFCid23 1;
BA_ "GenSigSendType" SG_ 1353 VFCVectorRLDMVFCid24 1;
BA_ "GenSigSendType" SG_ 1353 VFCVectorRLDMVFCid25 1;
BA_ "GenSigSendType" SG_ 1353 VFCVectorRLDMVFCid26 1;
BA_ "GenSigSendType" SG_ 1353 VFCVectorRLDMVFCid27 1;
BA_ "GenSigSendType" SG_ 1353 VFCVectorRLDMVFCid28 1;
BA_ "GenSigSendType" SG_ 1353 VFCVectorRLDMVFCid29 1;
BA_ "GenSigSendType" SG_ 1353 VFCVectorRLDMVFCid3 1;
BA_ "GenSigSendType" SG_ 1353 VFCVectorRLDMVFCid30 1;
BA_ "GenSigSendType" SG_ 1353 VFCVectorRLDMVFCid31 1;
BA_ "GenSigSendType" SG_ 1353 VFCVectorRLDMVFCid32 1;
BA_ "GenSigSendType" SG_ 1353 VFCVectorRLDMVFCid33 1;
BA_ "GenSigSendType" SG_ 1353 VFCVectorRLDMVFCid34 1;
BA_ "GenSigSendType" SG_ 1353 VFCVectorRLDMVFCid35 1;
BA_ "GenSigSendType" SG_ 1353 VFCVectorRLDMVFCid36 1;
BA_ "GenSigSendType" SG_ 1353 VFCVectorRLDMVFCid37 1;
BA_ "GenSigSendType" SG_ 1353 VFCVectorRLDMVFCid38 1;
BA_ "GenSigSendType" SG_ 1353 VFCVectorRLDMVFCid39 1;
BA_ "GenSigSendType" SG_ 1353 VFCVectorRLDMVFCid4 1;
BA_ "GenSigSendType" SG_ 1353 VFCVectorRLDMVFCid40 1;
BA_ "GenSigSendType" SG_ 1353 VFCVectorRLDMVFCid41 1;
BA_ "GenSigSendType" SG_ 1353 VFCVectorRLDMVFCid42 1;
BA_ "GenSigSendType" SG_ 1353 VFCVectorRLDMVFCid43 1;
BA_ "GenSigSendType" SG_ 1353 VFCVectorRLDMVFCid44 1;
BA_ "GenSigSendType" SG_ 1353 VFCVectorRLDMVFCid45 1;
BA_ "GenSigSendType" SG_ 1353 VFCVectorRLDMVFCid46 1;
BA_ "GenSigSendType" SG_ 1353 VFCVectorRLDMVFCid47 1;
BA_ "GenSigSendType" SG_ 1353 VFCVectorRLDMVFCid48 1;
BA_ "GenSigSendType" SG_ 1353 VFCVectorRLDMVFCid49 1;
BA_ "GenSigSendType" SG_ 1353 VFCVectorRLDMVFCid5 1;
BA_ "GenSigSendType" SG_ 1353 VFCVectorRLDMVFCid50 1;
BA_ "GenSigSendType" SG_ 1353 VFCVectorRLDMVFCid51 1;
BA_ "GenSigSendType" SG_ 1353 VFCVectorRLDMVFCid52 1;
BA_ "GenSigSendType" SG_ 1353 VFCVectorRLDMVFCid53 1;
BA_ "GenSigSendType" SG_ 1353 VFCVectorRLDMVFCid54 1;
BA_ "GenSigSendType" SG_ 1353 VFCVectorRLDMVFCid55 1;
BA_ "GenSigSendType" SG_ 1353 VFCVectorRLDMVFCid56 1;
BA_ "GenSigSendType" SG_ 1353 VFCVectorRLDMVFCid57 1;
BA_ "GenSigSendType" SG_ 1353 VFCVectorRLDMVFCid58 1;
BA_ "GenSigSendType" SG_ 1353 VFCVectorRLDMVFCid59 1;
BA_ "GenSigSendType" SG_ 1353 VFCVectorRLDMVFCid6 1;
BA_ "GenSigSendType" SG_ 1353 VFCVectorRLDMVFCid60 1;
BA_ "GenSigSendType" SG_ 1353 VFCVectorRLDMVFCid61 1;
BA_ "GenSigSendType" SG_ 1353 VFCVectorRLDMVFCid7 1;
BA_ "GenSigSendType" SG_ 1353 VFCVectorRLDMVFCid8 1;
BA_ "GenSigSendType" SG_ 1353 VFCVectorRLDMVFCid9 1;
BA_ "GenSigSendType" SG_ 117 ChdLockRightSts 0;
BA_ "GenSigStartValue" SG_ 117 DoorLeRe2Swt1DplyHndl 1;
BA_ "GenSigSendType" SG_ 117 DoorLeRe2Swt1DplyHndl 0;
BA_ "GenSigSendType" SG_ 117 DoorLeRe2Swt2DplyHndl 0;
BA_ "GenSigSendType" SG_ 117 DoorRiReCinhIntFailInfCinchFlt1 0;
BA_ "GenSigSendType" SG_ 117 DoorRiReCinhIntFailInfCinchRestF 0;
BA_ "SystemSignalLongSymbol" SG_ 117 DoorRiReCinhIntFailInfCinchRestF "DoorRiReCinhIntFailInfCinchRestFlt";
BA_ "GenSigSendType" SG_ 117 DoorRiReHndlHMIStsDeployedOverTm 0;
BA_ "SystemSignalLongSymbol" SG_ 117 DoorRiReHndlHMIStsDeployedOverTm "DoorRiReHndlHMIStsDeployedOverTmd";
BA_ "GenSigSendType" SG_ 117 DoorRiReHndlHMIStsReserved1 0;
BA_ "GenSigSendType" SG_ 117 DoorRiReHndlHMIStsRetractOverTmd 0;
BA_ "GenSigSendType" SG_ 117 DoorRiReHndlHMIStsUnsScsHallSnsr 0;
BA_ "SystemSignalLongSymbol" SG_ 117 DoorRiReHndlHMIStsUnsScsHallSnsr "DoorRiReHndlHMIStsUnsScsHallSnsrRest";
BA_ "GenSigSendType" SG_ 117 DoorRiReHndlSts 0;
BA_ "GenSigSendType" SG_ 117 DoorRiReLatPawlSt 0;
BA_ "GenSigSendType" SG_ 117 DoorRiReLatPosn 0;
BA_ "GenSigSendType" SG_ 117 DoorRiReLockSts 0;
BA_ "GenSigStartValue" SG_ 117 DoorRiReOpenLowReqOutdSwt1 2;
BA_ "GenSigSendType" SG_ 117 DoorRiReOpenLowReqOutdSwt1 0;
BA_ "GenSigStartValue" SG_ 117 DoorRiReOpenReqInsdSwt1 2;
BA_ "GenSigSendType" SG_ 117 DoorRiReOpenReqInsdSwt1 0;
BA_ "GenSigSendType" SG_ 117 DoorRiReRelsFailCinchOverTimed 0;
BA_ "GenSigSendType" SG_ 117 DoorRiReRelsFailFailure1 0;
BA_ "GenSigSendType" SG_ 117 DoorRiReRelsFailMechRels 0;
BA_ "GenSigSendType" SG_ 117 DoorRiReSwtLockgSts 0;
BA_ "GenSigSendType" SG_ 117 PassSeatRemCtrlReDoorRiActrIncSt 0;
BA_ "SystemSignalLongSymbol" SG_ 117 PassSeatRemCtrlReDoorRiActrIncSt "PassSeatRemCtrlReDoorRiActrIncSts";
BA_ "GenSigSendType" SG_ 117 PassSeatRemCtrlReDoorRiActrSldSt 0;
BA_ "SystemSignalLongSymbol" SG_ 117 PassSeatRemCtrlReDoorRiActrSldSt "PassSeatRemCtrlReDoorRiActrSldSts";
BA_ "GenSigSendType" SG_ 117 ShortDropWinReRiSts 0;
BA_ "GenSigSendType" SG_ 117 WinDsblRightSts 0;
BA_ "GenSigSendType" SG_ 117 WinFailrStsAtReRi 0;
BA_ "GenSigSendType" SG_ 117 WinPosnStsAtReRi 0;
BA_ "GenSigSendType" SG_ 117 WinPosReqReLe 0;
BA_ "GenSigSendType" SG_ 1360 VFCVectorRRDMBlockID 1;
BA_ "GenSigSendType" SG_ 1360 VFCVectorRRDMVFCid0 1;
BA_ "GenSigSendType" SG_ 1360 VFCVectorRRDMVFCid1 1;
BA_ "GenSigSendType" SG_ 1360 VFCVectorRRDMVFCid10 1;
BA_ "GenSigSendType" SG_ 1360 VFCVectorRRDMVFCid11 1;
BA_ "GenSigSendType" SG_ 1360 VFCVectorRRDMVFCid12 1;
BA_ "GenSigSendType" SG_ 1360 VFCVectorRRDMVFCid13 1;
BA_ "GenSigSendType" SG_ 1360 VFCVectorRRDMVFCid14 1;
BA_ "GenSigSendType" SG_ 1360 VFCVectorRRDMVFCid15 1;
BA_ "GenSigSendType" SG_ 1360 VFCVectorRRDMVFCid16 1;
BA_ "GenSigSendType" SG_ 1360 VFCVectorRRDMVFCid17 1;
BA_ "GenSigSendType" SG_ 1360 VFCVectorRRDMVFCid18 1;
BA_ "GenSigSendType" SG_ 1360 VFCVectorRRDMVFCid19 1;
BA_ "GenSigSendType" SG_ 1360 VFCVectorRRDMVFCid2 1;
BA_ "GenSigSendType" SG_ 1360 VFCVectorRRDMVFCid20 1;
BA_ "GenSigSendType" SG_ 1360 VFCVectorRRDMVFCid21 1;
BA_ "GenSigSendType" SG_ 1360 VFCVectorRRDMVFCid22 1;
BA_ "GenSigSendType" SG_ 1360 VFCVectorRRDMVFCid23 1;
BA_ "GenSigSendType" SG_ 1360 VFCVectorRRDMVFCid24 1;
BA_ "GenSigSendType" SG_ 1360 VFCVectorRRDMVFCid25 1;
BA_ "GenSigSendType" SG_ 1360 VFCVectorRRDMVFCid26 1;
BA_ "GenSigSendType" SG_ 1360 VFCVectorRRDMVFCid27 1;
BA_ "GenSigSendType" SG_ 1360 VFCVectorRRDMVFCid28 1;
BA_ "GenSigSendType" SG_ 1360 VFCVectorRRDMVFCid29 1;
BA_ "GenSigSendType" SG_ 1360 VFCVectorRRDMVFCid3 1;
BA_ "GenSigSendType" SG_ 1360 VFCVectorRRDMVFCid30 1;
BA_ "GenSigSendType" SG_ 1360 VFCVectorRRDMVFCid31 1;
BA_ "GenSigSendType" SG_ 1360 VFCVectorRRDMVFCid32 1;
BA_ "GenSigSendType" SG_ 1360 VFCVectorRRDMVFCid33 1;
BA_ "GenSigSendType" SG_ 1360 VFCVectorRRDMVFCid34 1;
BA_ "GenSigSendType" SG_ 1360 VFCVectorRRDMVFCid35 1;
BA_ "GenSigSendType" SG_ 1360 VFCVectorRRDMVFCid36 1;
BA_ "GenSigSendType" SG_ 1360 VFCVectorRRDMVFCid37 1;
BA_ "GenSigSendType" SG_ 1360 VFCVectorRRDMVFCid38 1;
BA_ "GenSigSendType" SG_ 1360 VFCVectorRRDMVFCid39 1;
BA_ "GenSigSendType" SG_ 1360 VFCVectorRRDMVFCid4 1;
BA_ "GenSigSendType" SG_ 1360 VFCVectorRRDMVFCid40 1;
BA_ "GenSigSendType" SG_ 1360 VFCVectorRRDMVFCid41 1;
BA_ "GenSigSendType" SG_ 1360 VFCVectorRRDMVFCid42 1;
BA_ "GenSigSendType" SG_ 1360 VFCVectorRRDMVFCid43 1;
BA_ "GenSigSendType" SG_ 1360 VFCVectorRRDMVFCid44 1;
BA_ "GenSigSendType" SG_ 1360 VFCVectorRRDMVFCid45 1;
BA_ "GenSigSendType" SG_ 1360 VFCVectorRRDMVFCid46 1;
BA_ "GenSigSendType" SG_ 1360 VFCVectorRRDMVFCid47 1;
BA_ "GenSigSendType" SG_ 1360 VFCVectorRRDMVFCid48 1;
BA_ "GenSigSendType" SG_ 1360 VFCVectorRRDMVFCid49 1;
BA_ "GenSigSendType" SG_ 1360 VFCVectorRRDMVFCid5 1;
BA_ "GenSigSendType" SG_ 1360 VFCVectorRRDMVFCid50 1;
BA_ "GenSigSendType" SG_ 1360 VFCVectorRRDMVFCid51 1;
BA_ "GenSigSendType" SG_ 1360 VFCVectorRRDMVFCid52 1;
BA_ "GenSigSendType" SG_ 1360 VFCVectorRRDMVFCid53 1;
BA_ "GenSigSendType" SG_ 1360 VFCVectorRRDMVFCid54 1;
BA_ "GenSigSendType" SG_ 1360 VFCVectorRRDMVFCid55 1;
BA_ "GenSigSendType" SG_ 1360 VFCVectorRRDMVFCid56 1;
BA_ "GenSigSendType" SG_ 1360 VFCVectorRRDMVFCid57 1;
BA_ "GenSigSendType" SG_ 1360 VFCVectorRRDMVFCid58 1;
BA_ "GenSigSendType" SG_ 1360 VFCVectorRRDMVFCid59 1;
BA_ "GenSigSendType" SG_ 1360 VFCVectorRRDMVFCid6 1;
BA_ "GenSigSendType" SG_ 1360 VFCVectorRRDMVFCid60 1;
BA_ "GenSigSendType" SG_ 1360 VFCVectorRRDMVFCid61 1;
BA_ "GenSigSendType" SG_ 1360 VFCVectorRRDMVFCid7 1;
BA_ "GenSigSendType" SG_ 1360 VFCVectorRRDMVFCid8 1;
BA_ "GenSigSendType" SG_ 1360 VFCVectorRRDMVFCid9 1;
BA_ "GenSigSendType" SG_ 1430 SMDdevelpsignalgrouprespFunction 1;
BA_ "SystemSignalLongSymbol" SG_ 1430 SMDdevelpsignalgrouprespFunction "SMDdevelpsignalgrouprespFunctiondevpsignalgroup1";
BA_ "GenSigSendType" SG_ 1430 SMDdevelpsignalgrouprespFun_0000 1;
BA_ "SystemSignalLongSymbol" SG_ 1430 SMDdevelpsignalgrouprespFun_0000 "SMDdevelpsignalgrouprespFunctiondevpsignalgroup2";
BA_ "GenSigSendType" SG_ 1430 SMDdevelpsignalgrouprespFun_0001 1;
BA_ "SystemSignalLongSymbol" SG_ 1430 SMDdevelpsignalgrouprespFun_0001 "SMDdevelpsignalgrouprespFunctiondevpsignalgroup3";
BA_ "GenSigSendType" SG_ 1430 SMDdevelpsignalgrouprespFun_0002 1;
BA_ "SystemSignalLongSymbol" SG_ 1430 SMDdevelpsignalgrouprespFun_0002 "SMDdevelpsignalgrouprespFunctiondevpsignalgroup4";
BA_ "GenSigSendType" SG_ 1430 SMDdevelpsignalgrouprespFun_0003 1;
BA_ "SystemSignalLongSymbol" SG_ 1430 SMDdevelpsignalgrouprespFun_0003 "SMDdevelpsignalgrouprespFunctiondevpsignalgroup5";
BA_ "GenSigSendType" SG_ 1430 SMDdevelpsignalgrouprespFun_0004 1;
BA_ "SystemSignalLongSymbol" SG_ 1430 SMDdevelpsignalgrouprespFun_0004 "SMDdevelpsignalgrouprespFunctiondevpsignalgroup6";
BA_ "GenSigSendType" SG_ 1430 SMDdevelpsignalgrouprespFun_0005 1;
BA_ "SystemSignalLongSymbol" SG_ 1430 SMDdevelpsignalgrouprespFun_0005 "SMDdevelpsignalgrouprespFunctiondevpsignalgroup7";
BA_ "GenSigSendType" SG_ 1430 SMDdevelpsignalgrouprespFun_0006 1;
BA_ "SystemSignalLongSymbol" SG_ 1430 SMDdevelpsignalgrouprespFun_0006 "SMDdevelpsignalgrouprespFunctiondevpsignalgroup8";
BA_ "GenSigSendType" SG_ 105 DrvrCtrlOfPassSeatFrntSts 0;
BA_ "GenSigSendType" SG_ 105 DrvrSeatBtnPsd 0;
BA_ "GenSigSendType" SG_ 105 DrvrSeatInAutMovmt 0;
BA_ "GenSigSendType" SG_ 105 DrvrSeatMemSts 0;
BA_ "GenSigSendType" SG_ 105 DrvrSeatVentnActlPwrCns 0;
BA_ "GenSigSendType" SG_ 105 DrvrSeatVentnDesPwrCns 0;
BA_ "GenSigSendType" SG_ 105 SeatBackAngleRowFirstDrvr 0;
BA_ "GenSigSendType" SG_ 864 DrvrSeatHallPosDownLdSts 1;
BA_ "GenSigSendType" SG_ 864 DrvrSeatHallPosExtUpldSeatCushEx 1;
BA_ "SystemSignalLongSymbol" SG_ 864 DrvrSeatHallPosExtUpldSeatCushEx "DrvrSeatHallPosExtUpldSeatCushExtPos";
BA_ "GenSigSendType" SG_ 864 DrvrSeatHallPosExtUpldSeatHeadrH 1;
BA_ "SystemSignalLongSymbol" SG_ 864 DrvrSeatHallPosExtUpldSeatHeadrH "DrvrSeatHallPosExtUpldSeatHeadrHozlPos";
BA_ "GenSigSendType" SG_ 864 DrvrSeatHallPosExtUpldSeatHeadrV 1;
BA_ "SystemSignalLongSymbol" SG_ 864 DrvrSeatHallPosExtUpldSeatHeadrV "DrvrSeatHallPosExtUpldSeatHeadrVertPos";
BA_ "GenSigSendType" SG_ 1193 DrvrSeatHallPosUpldSeatFrntHeiPo 1;
BA_ "SystemSignalLongSymbol" SG_ 1193 DrvrSeatHallPosUpldSeatFrntHeiPo "DrvrSeatHallPosUpldSeatFrntHeiPos";
BA_ "GenSigSendType" SG_ 1193 DrvrSeatHallPosUpldSeatHeiPos 1;
BA_ "GenSigSendType" SG_ 1193 DrvrSeatHallPosUpldSeatInclPos 1;
BA_ "GenSigSendType" SG_ 1193 DrvrSeatHallPosUpldSeatSldPos 1;
BA_ "GenSigSendType" SG_ 665 DrvrMassgRunng 0;
BA_ "GenSigSendType" SG_ 665 DrvrSeatActvSpplFct 0;
BA_ "GenSigSendType" SG_ 665 DrvrSeatHeatgActlPwrCns 0;
BA_ "GenSigSendType" SG_ 665 DrvrSeatHeatgAvlSts 0;
BA_ "GenSigSendType" SG_ 665 DrvrSeatHeatgDesPwrCns 0;
BA_ "GenSigSendType" SG_ 665 DrvrSeatHeatgLvlSts 0;
BA_ "GenSigSendType" SG_ 665 DrvrSeatMassgFctReq 0;
BA_ "GenSigSendType" SG_ 665 DrvrSeatSwtStsDrvrSeatSwtAdjmtOf 0;
BA_ "SystemSignalLongSymbol" SG_ 665 DrvrSeatSwtStsDrvrSeatSwtAdjmtOf "DrvrSeatSwtStsDrvrSeatSwtAdjmtOfSpplFctHozlSts";
BA_ "GenSigSendType" SG_ 665 DrvrSeatSwtStsDrvrSeatSwtAd_0000 0;
BA_ "SystemSignalLongSymbol" SG_ 665 DrvrSeatSwtStsDrvrSeatSwtAd_0000 "DrvrSeatSwtStsDrvrSeatSwtAdjmtOfSpplFctVertSts";
BA_ "GenSigSendType" SG_ 665 DrvrSeatSwtStsDrvrSeatSwtHdrstHo 0;
BA_ "SystemSignalLongSymbol" SG_ 665 DrvrSeatSwtStsDrvrSeatSwtHdrstHo "DrvrSeatSwtStsDrvrSeatSwtHdrstHozlSts";
BA_ "GenSigSendType" SG_ 665 DrvrSeatSwtStsDrvrSeatSwtHdrstVe 0;
BA_ "SystemSignalLongSymbol" SG_ 665 DrvrSeatSwtStsDrvrSeatSwtHdrstVe "DrvrSeatSwtStsDrvrSeatSwtHdrstVertSts";
BA_ "GenSigSendType" SG_ 665 DrvrSeatSwtStsDrvrSeatSwtHeiFrnt 0;
BA_ "SystemSignalLongSymbol" SG_ 665 DrvrSeatSwtStsDrvrSeatSwtHeiFrnt "DrvrSeatSwtStsDrvrSeatSwtHeiFrntSts";
BA_ "GenSigSendType" SG_ 665 DrvrSeatSwtStsDrvrSeatSwtHeiSts 0;
BA_ "GenSigSendType" SG_ 665 DrvrSeatSwtStsDrvrSeatSwtInclSts 0;
BA_ "GenSigSendType" SG_ 665 DrvrSeatSwtStsDrvrSeatSwtSelnOfS 0;
BA_ "SystemSignalLongSymbol" SG_ 665 DrvrSeatSwtStsDrvrSeatSwtSelnOfS "DrvrSeatSwtStsDrvrSeatSwtSelnOfSpplFctSts";
BA_ "GenSigSendType" SG_ 665 DrvrSeatSwtStsDrvrSeatSwtSldSts 0;
BA_ "GenSigSendType" SG_ 665 DrvrSeatVentAvlSts 0;
BA_ "GenSigSendType" SG_ 665 DrvrSeatVentnLvlSts 0;
BA_ "GenSigSendType" SG_ 272 DrvrSeatExtAdjAllowd 0;
BA_ "GenSigStartValue" SG_ 272 DrvrSeatPosPercSeatPosFrntHeiPer 1000;
BA_ "GenSigSendType" SG_ 272 DrvrSeatPosPercSeatPosFrntHeiPer 0;
BA_ "SystemSignalLongSymbol" SG_ 272 DrvrSeatPosPercSeatPosFrntHeiPer "DrvrSeatPosPercSeatPosFrntHeiPerc";
BA_ "GenSigStartValue" SG_ 272 DrvrSeatPosPercSeatPosFrntHeiQF 1;
BA_ "GenSigSendType" SG_ 272 DrvrSeatPosPercSeatPosFrntHeiQF 0;
BA_ "GenSigStartValue" SG_ 272 DrvrSeatPosPercSeatPosHeiPerc 1000;
BA_ "GenSigSendType" SG_ 272 DrvrSeatPosPercSeatPosHeiPerc 0;
BA_ "GenSigStartValue" SG_ 272 DrvrSeatPosPercSeatPosHeiQF 1;
BA_ "GenSigSendType" SG_ 272 DrvrSeatPosPercSeatPosHeiQF 0;
BA_ "GenSigStartValue" SG_ 272 DrvrSeatPosPercSeatPosSldPerc 1000;
BA_ "GenSigSendType" SG_ 272 DrvrSeatPosPercSeatPosSldPerc 0;
BA_ "GenSigStartValue" SG_ 272 DrvrSeatPosPercSeatPosSldQF 1;
BA_ "GenSigSendType" SG_ 272 DrvrSeatPosPercSeatPosSldQF 0;
BA_ "GenSigSendType" SG_ 547 DrvrSeatActvSwtFctMod 0;
BA_ "GenSigSendType" SG_ 547 DrvrSeatIntgrSwtStsIntgrSwtHozlS 0;
BA_ "SystemSignalLongSymbol" SG_ 547 DrvrSeatIntgrSwtStsIntgrSwtHozlS "DrvrSeatIntgrSwtStsIntgrSwtHozlSts";
BA_ "GenSigSendType" SG_ 547 DrvrSeatIntgrSwtStsIntgrSwtRotSt 0;
BA_ "SystemSignalLongSymbol" SG_ 547 DrvrSeatIntgrSwtStsIntgrSwtRotSt "DrvrSeatIntgrSwtStsIntgrSwtRotSts";
BA_ "GenSigSendType" SG_ 547 DrvrSeatIntgrSwtStsIntgrSwtSelnS 0;
BA_ "SystemSignalLongSymbol" SG_ 547 DrvrSeatIntgrSwtStsIntgrSwtSelnS "DrvrSeatIntgrSwtStsIntgrSwtSelnSts";
BA_ "GenSigSendType" SG_ 547 DrvrSeatIntgrSwtStsIntgrSwtVertS 0;
BA_ "SystemSignalLongSymbol" SG_ 547 DrvrSeatIntgrSwtStsIntgrSwtVertS "DrvrSeatIntgrSwtStsIntgrSwtVertSts";
BA_ "GenSigStartValue" SG_ 547 DrvrSeatPivtPosPercSeatPosPerc 1000;
BA_ "GenSigSendType" SG_ 547 DrvrSeatPivtPosPercSeatPosPerc 0;
BA_ "GenSigStartValue" SG_ 547 DrvrSeatPivtPosPercSeatPosQf 1;
BA_ "GenSigSendType" SG_ 547 DrvrSeatPivtPosPercSeatPosQf 0;
BA_ "GenSigSendType" SG_ 547 DrvrSeatSwtBlstrSts 0;
BA_ "GenSigSendType" SG_ 547 DrvrSeatSwtCushExtSts 0;
BA_ "GenSigSendType" SG_ 1362 VFCVectorSMDBlockID 1;
BA_ "GenSigSendType" SG_ 1362 VFCVectorSMDVFCid0 1;
BA_ "GenSigSendType" SG_ 1362 VFCVectorSMDVFCid1 1;
BA_ "GenSigSendType" SG_ 1362 VFCVectorSMDVFCid10 1;
BA_ "GenSigSendType" SG_ 1362 VFCVectorSMDVFCid11 1;
BA_ "GenSigSendType" SG_ 1362 VFCVectorSMDVFCid12 1;
BA_ "GenSigSendType" SG_ 1362 VFCVectorSMDVFCid13 1;
BA_ "GenSigSendType" SG_ 1362 VFCVectorSMDVFCid14 1;
BA_ "GenSigSendType" SG_ 1362 VFCVectorSMDVFCid15 1;
BA_ "GenSigSendType" SG_ 1362 VFCVectorSMDVFCid16 1;
BA_ "GenSigSendType" SG_ 1362 VFCVectorSMDVFCid17 1;
BA_ "GenSigSendType" SG_ 1362 VFCVectorSMDVFCid18 1;
BA_ "GenSigSendType" SG_ 1362 VFCVectorSMDVFCid19 1;
BA_ "GenSigSendType" SG_ 1362 VFCVectorSMDVFCid2 1;
BA_ "GenSigSendType" SG_ 1362 VFCVectorSMDVFCid20 1;
BA_ "GenSigSendType" SG_ 1362 VFCVectorSMDVFCid21 1;
BA_ "GenSigSendType" SG_ 1362 VFCVectorSMDVFCid22 1;
BA_ "GenSigSendType" SG_ 1362 VFCVectorSMDVFCid23 1;
BA_ "GenSigSendType" SG_ 1362 VFCVectorSMDVFCid24 1;
BA_ "GenSigSendType" SG_ 1362 VFCVectorSMDVFCid25 1;
BA_ "GenSigSendType" SG_ 1362 VFCVectorSMDVFCid26 1;
BA_ "GenSigSendType" SG_ 1362 VFCVectorSMDVFCid27 1;
BA_ "GenSigSendType" SG_ 1362 VFCVectorSMDVFCid28 1;
BA_ "GenSigSendType" SG_ 1362 VFCVectorSMDVFCid29 1;
BA_ "GenSigSendType" SG_ 1362 VFCVectorSMDVFCid3 1;
BA_ "GenSigSendType" SG_ 1362 VFCVectorSMDVFCid30 1;
BA_ "GenSigSendType" SG_ 1362 VFCVectorSMDVFCid31 1;
BA_ "GenSigSendType" SG_ 1362 VFCVectorSMDVFCid32 1;
BA_ "GenSigSendType" SG_ 1362 VFCVectorSMDVFCid33 1;
BA_ "GenSigSendType" SG_ 1362 VFCVectorSMDVFCid34 1;
BA_ "GenSigSendType" SG_ 1362 VFCVectorSMDVFCid35 1;
BA_ "GenSigSendType" SG_ 1362 VFCVectorSMDVFCid36 1;
BA_ "GenSigSendType" SG_ 1362 VFCVectorSMDVFCid37 1;
BA_ "GenSigSendType" SG_ 1362 VFCVectorSMDVFCid38 1;
BA_ "GenSigSendType" SG_ 1362 VFCVectorSMDVFCid39 1;
BA_ "GenSigSendType" SG_ 1362 VFCVectorSMDVFCid4 1;
BA_ "GenSigSendType" SG_ 1362 VFCVectorSMDVFCid40 1;
BA_ "GenSigSendType" SG_ 1362 VFCVectorSMDVFCid41 1;
BA_ "GenSigSendType" SG_ 1362 VFCVectorSMDVFCid42 1;
BA_ "GenSigSendType" SG_ 1362 VFCVectorSMDVFCid43 1;
BA_ "GenSigSendType" SG_ 1362 VFCVectorSMDVFCid44 1;
BA_ "GenSigSendType" SG_ 1362 VFCVectorSMDVFCid45 1;
BA_ "GenSigSendType" SG_ 1362 VFCVectorSMDVFCid46 1;
BA_ "GenSigSendType" SG_ 1362 VFCVectorSMDVFCid47 1;
BA_ "GenSigSendType" SG_ 1362 VFCVectorSMDVFCid48 1;
BA_ "GenSigSendType" SG_ 1362 VFCVectorSMDVFCid49 1;
BA_ "GenSigSendType" SG_ 1362 VFCVectorSMDVFCid5 1;
BA_ "GenSigSendType" SG_ 1362 VFCVectorSMDVFCid50 1;
BA_ "GenSigSendType" SG_ 1362 VFCVectorSMDVFCid51 1;
BA_ "GenSigSendType" SG_ 1362 VFCVectorSMDVFCid52 1;
BA_ "GenSigSendType" SG_ 1362 VFCVectorSMDVFCid53 1;
BA_ "GenSigSendType" SG_ 1362 VFCVectorSMDVFCid54 1;
BA_ "GenSigSendType" SG_ 1362 VFCVectorSMDVFCid55 1;
BA_ "GenSigSendType" SG_ 1362 VFCVectorSMDVFCid56 1;
BA_ "GenSigSendType" SG_ 1362 VFCVectorSMDVFCid57 1;
BA_ "GenSigSendType" SG_ 1362 VFCVectorSMDVFCid58 1;
BA_ "GenSigSendType" SG_ 1362 VFCVectorSMDVFCid59 1;
BA_ "GenSigSendType" SG_ 1362 VFCVectorSMDVFCid6 1;
BA_ "GenSigSendType" SG_ 1362 VFCVectorSMDVFCid60 1;
BA_ "GenSigSendType" SG_ 1362 VFCVectorSMDVFCid61 1;
BA_ "GenSigSendType" SG_ 1362 VFCVectorSMDVFCid7 1;
BA_ "GenSigSendType" SG_ 1362 VFCVectorSMDVFCid8 1;
BA_ "GenSigSendType" SG_ 1362 VFCVectorSMDVFCid9 1;
BA_ "GenSigSendType" SG_ 1431 SMPdevelpsignalgrouprespFunction 1;
BA_ "SystemSignalLongSymbol" SG_ 1431 SMPdevelpsignalgrouprespFunction "SMPdevelpsignalgrouprespFunctiondevpsignalgroup1";
BA_ "GenSigSendType" SG_ 1431 SMPdevelpsignalgrouprespFun_0000 1;
BA_ "SystemSignalLongSymbol" SG_ 1431 SMPdevelpsignalgrouprespFun_0000 "SMPdevelpsignalgrouprespFunctiondevpsignalgroup2";
BA_ "GenSigSendType" SG_ 1431 SMPdevelpsignalgrouprespFun_0001 1;
BA_ "SystemSignalLongSymbol" SG_ 1431 SMPdevelpsignalgrouprespFun_0001 "SMPdevelpsignalgrouprespFunctiondevpsignalgroup3";
BA_ "GenSigSendType" SG_ 1431 SMPdevelpsignalgrouprespFun_0002 1;
BA_ "SystemSignalLongSymbol" SG_ 1431 SMPdevelpsignalgrouprespFun_0002 "SMPdevelpsignalgrouprespFunctiondevpsignalgroup4";
BA_ "GenSigSendType" SG_ 1431 SMPdevelpsignalgrouprespFun_0003 1;
BA_ "SystemSignalLongSymbol" SG_ 1431 SMPdevelpsignalgrouprespFun_0003 "SMPdevelpsignalgrouprespFunctiondevpsignalgroup5";
BA_ "GenSigSendType" SG_ 1431 SMPdevelpsignalgrouprespFun_0004 1;
BA_ "SystemSignalLongSymbol" SG_ 1431 SMPdevelpsignalgrouprespFun_0004 "SMPdevelpsignalgrouprespFunctiondevpsignalgroup6";
BA_ "GenSigSendType" SG_ 1431 SMPdevelpsignalgrouprespFun_0005 1;
BA_ "SystemSignalLongSymbol" SG_ 1431 SMPdevelpsignalgrouprespFun_0005 "SMPdevelpsignalgrouprespFunctiondevpsignalgroup7";
BA_ "GenSigSendType" SG_ 1431 SMPdevelpsignalgrouprespFun_0006 1;
BA_ "SystemSignalLongSymbol" SG_ 1431 SMPdevelpsignalgrouprespFun_0006 "SMPdevelpsignalgrouprespFunctiondevpsignalgroup8";
BA_ "GenSigSendType" SG_ 304 PassSeatBtnPsd 0;
BA_ "GenSigSendType" SG_ 304 PassSeatHeatgActlPwrCns 0;
BA_ "GenSigSendType" SG_ 304 PassSeatHeatgDesPwrCns 0;
BA_ "GenSigSendType" SG_ 304 PassSeatInAutMovmt 0;
BA_ "GenSigSendType" SG_ 304 PassSeatMemSts 0;
BA_ "GenSigSendType" SG_ 304 PassSeatVentnActlPwrCns 0;
BA_ "GenSigSendType" SG_ 304 PassSeatVentnDesPwrCns 0;
BA_ "GenSigSendType" SG_ 275 PassSeatMassgFctReq 0;
BA_ "GenSigStartValue" SG_ 275 PassSeatPosPercSeatPosFrntHeiPer 1000;
BA_ "GenSigSendType" SG_ 275 PassSeatPosPercSeatPosFrntHeiPer 0;
BA_ "SystemSignalLongSymbol" SG_ 275 PassSeatPosPercSeatPosFrntHeiPer "PassSeatPosPercSeatPosFrntHeiPerc";
BA_ "GenSigStartValue" SG_ 275 PassSeatPosPercSeatPosFrntHeiQF 1;
BA_ "GenSigSendType" SG_ 275 PassSeatPosPercSeatPosFrntHeiQF 0;
BA_ "GenSigStartValue" SG_ 275 PassSeatPosPercSeatPosHeiPerc 1000;
BA_ "GenSigSendType" SG_ 275 PassSeatPosPercSeatPosHeiPerc 0;
BA_ "GenSigStartValue" SG_ 275 PassSeatPosPercSeatPosHeiQF 1;
BA_ "GenSigSendType" SG_ 275 PassSeatPosPercSeatPosHeiQF 0;
BA_ "GenSigStartValue" SG_ 275 PassSeatPosPercSeatPosSldPerc 1000;
BA_ "GenSigSendType" SG_ 275 PassSeatPosPercSeatPosSldPerc 0;
BA_ "GenSigStartValue" SG_ 275 PassSeatPosPercSeatPosSldQF 1;
BA_ "GenSigSendType" SG_ 275 PassSeatPosPercSeatPosSldQF 0;
BA_ "GenSigSendType" SG_ 275 SeatBackAngleRowFirstPass 0;
BA_ "GenSigSendType" SG_ 1063 PassMassgRunng 0;
BA_ "GenSigSendType" SG_ 1063 PassSeatActvSpplFct 0;
BA_ "GenSigSendType" SG_ 1063 PassSeatHeatgAvlSts 0;
BA_ "GenSigSendType" SG_ 1063 PassSeatHeatgLvlSts 0;
BA_ "GenSigStartValue" SG_ 1063 PassSeatPivtPosPercSeatPosPerc 1000;
BA_ "GenSigSendType" SG_ 1063 PassSeatPivtPosPercSeatPosPerc 0;
BA_ "GenSigStartValue" SG_ 1063 PassSeatPivtPosPercSeatPosQf 1;
BA_ "GenSigSendType" SG_ 1063 PassSeatPivtPosPercSeatPosQf 0;
BA_ "GenSigSendType" SG_ 1063 PassSeatSwtSts2PassSeatSwtAdjmtO 0;
BA_ "SystemSignalLongSymbol" SG_ 1063 PassSeatSwtSts2PassSeatSwtAdjmtO "PassSeatSwtSts2PassSeatSwtAdjmtOfSpplFctHozlSts";
BA_ "GenSigSendType" SG_ 1063 PassSeatSwtSts2PassSeatSwtA_0000 0;
BA_ "SystemSignalLongSymbol" SG_ 1063 PassSeatSwtSts2PassSeatSwtA_0000 "PassSeatSwtSts2PassSeatSwtAdjmtOfSpplFctVerSts";
BA_ "GenSigSendType" SG_ 1063 PassSeatSwtSts2PassSeatSwtHdrstH 0;
BA_ "SystemSignalLongSymbol" SG_ 1063 PassSeatSwtSts2PassSeatSwtHdrstH "PassSeatSwtSts2PassSeatSwtHdrstHozlSts";
BA_ "GenSigSendType" SG_ 1063 PassSeatSwtSts2PassSeatSwtHdrstV 0;
BA_ "SystemSignalLongSymbol" SG_ 1063 PassSeatSwtSts2PassSeatSwtHdrstV "PassSeatSwtSts2PassSeatSwtHdrstVertSts";
BA_ "GenSigSendType" SG_ 1063 PassSeatSwtSts2PassSeatSwtHeiFrn 0;
BA_ "SystemSignalLongSymbol" SG_ 1063 PassSeatSwtSts2PassSeatSwtHeiFrn "PassSeatSwtSts2PassSeatSwtHeiFrntSts";
BA_ "GenSigSendType" SG_ 1063 PassSeatSwtSts2PassSeatSwtHeiSts 0;
BA_ "GenSigSendType" SG_ 1063 PassSeatSwtSts2PassSeatSwtInclSt 0;
BA_ "SystemSignalLongSymbol" SG_ 1063 PassSeatSwtSts2PassSeatSwtInclSt "PassSeatSwtSts2PassSeatSwtInclSts";
BA_ "GenSigSendType" SG_ 1063 PassSeatSwtSts2PassSeatSwtSelnOf 0;
BA_ "SystemSignalLongSymbol" SG_ 1063 PassSeatSwtSts2PassSeatSwtSelnOf "PassSeatSwtSts2PassSeatSwtSelnOfSpplFctStsSts";
BA_ "GenSigSendType" SG_ 1063 PassSeatSwtSts2PassSeatSwtSldSts 0;
BA_ "GenSigSendType" SG_ 1063 PassSeatVentAvlSts 0;
BA_ "GenSigSendType" SG_ 1063 PassSeatVentnLvlSts 0;
BA_ "GenSigSendType" SG_ 1063 RowFrstPassODSSts 0;
BA_ "GenSigSendType" SG_ 538 PassSeatActvSwtFctMod 0;
BA_ "GenSigSendType" SG_ 538 PassSeatIntgrSwtStsIntgrSwtHozlS 0;
BA_ "SystemSignalLongSymbol" SG_ 538 PassSeatIntgrSwtStsIntgrSwtHozlS "PassSeatIntgrSwtStsIntgrSwtHozlSts";
BA_ "GenSigSendType" SG_ 538 PassSeatIntgrSwtStsIntgrSwtRotSt 0;
BA_ "SystemSignalLongSymbol" SG_ 538 PassSeatIntgrSwtStsIntgrSwtRotSt "PassSeatIntgrSwtStsIntgrSwtRotSts";
BA_ "GenSigSendType" SG_ 538 PassSeatIntgrSwtStsIntgrSwtSelnS 0;
BA_ "SystemSignalLongSymbol" SG_ 538 PassSeatIntgrSwtStsIntgrSwtSelnS "PassSeatIntgrSwtStsIntgrSwtSelnSts";
BA_ "GenSigSendType" SG_ 538 PassSeatIntgrSwtStsIntgrSwtVertS 0;
BA_ "SystemSignalLongSymbol" SG_ 538 PassSeatIntgrSwtStsIntgrSwtVertS "PassSeatIntgrSwtStsIntgrSwtVertSts";
BA_ "GenSigSendType" SG_ 538 PassSeatSwtBlstrSts 0;
BA_ "GenSigSendType" SG_ 538 PassSeatSwtCushExtSts 0;
BA_ "GenSigSendType" SG_ 1363 VFCVectorSMPBlockID 1;
BA_ "GenSigSendType" SG_ 1363 VFCVectorSMPVFCid0 1;
BA_ "GenSigSendType" SG_ 1363 VFCVectorSMPVFCid1 1;
BA_ "GenSigSendType" SG_ 1363 VFCVectorSMPVFCid10 1;
BA_ "GenSigSendType" SG_ 1363 VFCVectorSMPVFCid11 1;
BA_ "GenSigSendType" SG_ 1363 VFCVectorSMPVFCid12 1;
BA_ "GenSigSendType" SG_ 1363 VFCVectorSMPVFCid13 1;
BA_ "GenSigSendType" SG_ 1363 VFCVectorSMPVFCid14 1;
BA_ "GenSigSendType" SG_ 1363 VFCVectorSMPVFCid15 1;
BA_ "GenSigSendType" SG_ 1363 VFCVectorSMPVFCid16 1;
BA_ "GenSigSendType" SG_ 1363 VFCVectorSMPVFCid17 1;
BA_ "GenSigSendType" SG_ 1363 VFCVectorSMPVFCid18 1;
BA_ "GenSigSendType" SG_ 1363 VFCVectorSMPVFCid19 1;
BA_ "GenSigSendType" SG_ 1363 VFCVectorSMPVFCid2 1;
BA_ "GenSigSendType" SG_ 1363 VFCVectorSMPVFCid20 1;
BA_ "GenSigSendType" SG_ 1363 VFCVectorSMPVFCid21 1;
BA_ "GenSigSendType" SG_ 1363 VFCVectorSMPVFCid22 1;
BA_ "GenSigSendType" SG_ 1363 VFCVectorSMPVFCid23 1;
BA_ "GenSigSendType" SG_ 1363 VFCVectorSMPVFCid24 1;
BA_ "GenSigSendType" SG_ 1363 VFCVectorSMPVFCid25 1;
BA_ "GenSigSendType" SG_ 1363 VFCVectorSMPVFCid26 1;
BA_ "GenSigSendType" SG_ 1363 VFCVectorSMPVFCid27 1;
BA_ "GenSigSendType" SG_ 1363 VFCVectorSMPVFCid28 1;
BA_ "GenSigSendType" SG_ 1363 VFCVectorSMPVFCid29 1;
BA_ "GenSigSendType" SG_ 1363 VFCVectorSMPVFCid3 1;
BA_ "GenSigSendType" SG_ 1363 VFCVectorSMPVFCid30 1;
BA_ "GenSigSendType" SG_ 1363 VFCVectorSMPVFCid31 1;
BA_ "GenSigSendType" SG_ 1363 VFCVectorSMPVFCid32 1;
BA_ "GenSigSendType" SG_ 1363 VFCVectorSMPVFCid33 1;
BA_ "GenSigSendType" SG_ 1363 VFCVectorSMPVFCid34 1;
BA_ "GenSigSendType" SG_ 1363 VFCVectorSMPVFCid35 1;
BA_ "GenSigSendType" SG_ 1363 VFCVectorSMPVFCid36 1;
BA_ "GenSigSendType" SG_ 1363 VFCVectorSMPVFCid37 1;
BA_ "GenSigSendType" SG_ 1363 VFCVectorSMPVFCid38 1;
BA_ "GenSigSendType" SG_ 1363 VFCVectorSMPVFCid39 1;
BA_ "GenSigSendType" SG_ 1363 VFCVectorSMPVFCid4 1;
BA_ "GenSigSendType" SG_ 1363 VFCVectorSMPVFCid40 1;
BA_ "GenSigSendType" SG_ 1363 VFCVectorSMPVFCid41 1;
BA_ "GenSigSendType" SG_ 1363 VFCVectorSMPVFCid42 1;
BA_ "GenSigSendType" SG_ 1363 VFCVectorSMPVFCid43 1;
BA_ "GenSigSendType" SG_ 1363 VFCVectorSMPVFCid44 1;
BA_ "GenSigSendType" SG_ 1363 VFCVectorSMPVFCid45 1;
BA_ "GenSigSendType" SG_ 1363 VFCVectorSMPVFCid46 1;
BA_ "GenSigSendType" SG_ 1363 VFCVectorSMPVFCid47 1;
BA_ "GenSigSendType" SG_ 1363 VFCVectorSMPVFCid48 1;
BA_ "GenSigSendType" SG_ 1363 VFCVectorSMPVFCid49 1;
BA_ "GenSigSendType" SG_ 1363 VFCVectorSMPVFCid5 1;
BA_ "GenSigSendType" SG_ 1363 VFCVectorSMPVFCid50 1;
BA_ "GenSigSendType" SG_ 1363 VFCVectorSMPVFCid51 1;
BA_ "GenSigSendType" SG_ 1363 VFCVectorSMPVFCid52 1;
BA_ "GenSigSendType" SG_ 1363 VFCVectorSMPVFCid53 1;
BA_ "GenSigSendType" SG_ 1363 VFCVectorSMPVFCid54 1;
BA_ "GenSigSendType" SG_ 1363 VFCVectorSMPVFCid55 1;
BA_ "GenSigSendType" SG_ 1363 VFCVectorSMPVFCid56 1;
BA_ "GenSigSendType" SG_ 1363 VFCVectorSMPVFCid57 1;
BA_ "GenSigSendType" SG_ 1363 VFCVectorSMPVFCid58 1;
BA_ "GenSigSendType" SG_ 1363 VFCVectorSMPVFCid59 1;
BA_ "GenSigSendType" SG_ 1363 VFCVectorSMPVFCid6 1;
BA_ "GenSigSendType" SG_ 1363 VFCVectorSMPVFCid60 1;
BA_ "GenSigSendType" SG_ 1363 VFCVectorSMPVFCid61 1;
BA_ "GenSigSendType" SG_ 1363 VFCVectorSMPVFCid7 1;
BA_ "GenSigSendType" SG_ 1363 VFCVectorSMPVFCid8 1;
BA_ "GenSigSendType" SG_ 1363 VFCVectorSMPVFCid9 1;
BA_ "GenSigSendType" SG_ 208 TrlrFogLiSts 0;
BA_ "GenSigSendType" SG_ 208 TrlrLampActvtChk 0;
BA_ "GenSigSendType" SG_ 208 TrlrLampChkSts 0;
BA_ "GenSigSendType" SG_ 208 TrlrLeIndcrFltSts 0;
BA_ "GenSigSendType" SG_ 208 TrlrLiFltSts 0;
BA_ "GenSigStartValue" SG_ 208 TrlrPrmntPwrActv 1;
BA_ "GenSigSendType" SG_ 208 TrlrPrmntPwrActv 0;
BA_ "GenSigSendType" SG_ 208 TrlrPrsnt 0;
BA_ "GenSigSendType" SG_ 208 TrlrRiIndcrFltSts 0;
BA_ "GenSigSendType" SG_ 208 TrlrSrvReq 0;
BA_ "GenSigSendType" SG_ 145 TrlrBrkLiSts 0;
BA_ "GenSigSendType" SG_ 145 TrlrIndcrTurnSts 0;
BA_ "GenSigSendType" SG_ 145 TrlrPosnLiSts 0;
BA_ "GenSigSendType" SG_ 145 TrlrRvsgLiSts 0;
BA_ "GenSigSendType" SG_ 145 TwbrLockdPosn 0;
BA_ "GenSigSendType" SG_ 145 TwbrWarnStsChks 0;
BA_ "GenSigFuncType" SG_ 145 TwbrWarnStsChks 15;
BA_ "GenSigDataID" SG_ 145 TwbrWarnStsChks "0x1F43";
BA_ "GenSigSendType" SG_ 145 TwbrWarnStsCntr 0;
BA_ "GenSigFuncType" SG_ 145 TwbrWarnStsCntr 16;
BA_ "GenSigStartValue" SG_ 145 TwbrWarnStsYesNo 2;
BA_ "GenSigSendType" SG_ 145 TwbrWarnStsYesNo 0;
BA_ "GenSigSendType" SG_ 1365 VFCVectorTRMBlockID 1;
BA_ "GenSigSendType" SG_ 1365 VFCVectorTRMVFCid0 1;
BA_ "GenSigSendType" SG_ 1365 VFCVectorTRMVFCid1 1;
BA_ "GenSigSendType" SG_ 1365 VFCVectorTRMVFCid10 1;
BA_ "GenSigSendType" SG_ 1365 VFCVectorTRMVFCid11 1;
BA_ "GenSigSendType" SG_ 1365 VFCVectorTRMVFCid12 1;
BA_ "GenSigSendType" SG_ 1365 VFCVectorTRMVFCid13 1;
BA_ "GenSigSendType" SG_ 1365 VFCVectorTRMVFCid14 1;
BA_ "GenSigSendType" SG_ 1365 VFCVectorTRMVFCid15 1;
BA_ "GenSigSendType" SG_ 1365 VFCVectorTRMVFCid16 1;
BA_ "GenSigSendType" SG_ 1365 VFCVectorTRMVFCid17 1;
BA_ "GenSigSendType" SG_ 1365 VFCVectorTRMVFCid18 1;
BA_ "GenSigSendType" SG_ 1365 VFCVectorTRMVFCid19 1;
BA_ "GenSigSendType" SG_ 1365 VFCVectorTRMVFCid2 1;
BA_ "GenSigSendType" SG_ 1365 VFCVectorTRMVFCid20 1;
BA_ "GenSigSendType" SG_ 1365 VFCVectorTRMVFCid21 1;
BA_ "GenSigSendType" SG_ 1365 VFCVectorTRMVFCid22 1;
BA_ "GenSigSendType" SG_ 1365 VFCVectorTRMVFCid23 1;
BA_ "GenSigSendType" SG_ 1365 VFCVectorTRMVFCid24 1;
BA_ "GenSigSendType" SG_ 1365 VFCVectorTRMVFCid25 1;
BA_ "GenSigSendType" SG_ 1365 VFCVectorTRMVFCid26 1;
BA_ "GenSigSendType" SG_ 1365 VFCVectorTRMVFCid27 1;
BA_ "GenSigSendType" SG_ 1365 VFCVectorTRMVFCid28 1;
BA_ "GenSigSendType" SG_ 1365 VFCVectorTRMVFCid29 1;
BA_ "GenSigSendType" SG_ 1365 VFCVectorTRMVFCid3 1;
BA_ "GenSigSendType" SG_ 1365 VFCVectorTRMVFCid30 1;
BA_ "GenSigSendType" SG_ 1365 VFCVectorTRMVFCid31 1;
BA_ "GenSigSendType" SG_ 1365 VFCVectorTRMVFCid32 1;
BA_ "GenSigSendType" SG_ 1365 VFCVectorTRMVFCid33 1;
BA_ "GenSigSendType" SG_ 1365 VFCVectorTRMVFCid34 1;
BA_ "GenSigSendType" SG_ 1365 VFCVectorTRMVFCid35 1;
BA_ "GenSigSendType" SG_ 1365 VFCVectorTRMVFCid36 1;
BA_ "GenSigSendType" SG_ 1365 VFCVectorTRMVFCid37 1;
BA_ "GenSigSendType" SG_ 1365 VFCVectorTRMVFCid38 1;
BA_ "GenSigSendType" SG_ 1365 VFCVectorTRMVFCid39 1;
BA_ "GenSigSendType" SG_ 1365 VFCVectorTRMVFCid4 1;
BA_ "GenSigSendType" SG_ 1365 VFCVectorTRMVFCid40 1;
BA_ "GenSigSendType" SG_ 1365 VFCVectorTRMVFCid41 1;
BA_ "GenSigSendType" SG_ 1365 VFCVectorTRMVFCid42 1;
BA_ "GenSigSendType" SG_ 1365 VFCVectorTRMVFCid43 1;
BA_ "GenSigSendType" SG_ 1365 VFCVectorTRMVFCid44 1;
BA_ "GenSigSendType" SG_ 1365 VFCVectorTRMVFCid45 1;
BA_ "GenSigSendType" SG_ 1365 VFCVectorTRMVFCid46 1;
BA_ "GenSigSendType" SG_ 1365 VFCVectorTRMVFCid47 1;
BA_ "GenSigSendType" SG_ 1365 VFCVectorTRMVFCid48 1;
BA_ "GenSigSendType" SG_ 1365 VFCVectorTRMVFCid49 1;
BA_ "GenSigSendType" SG_ 1365 VFCVectorTRMVFCid5 1;
BA_ "GenSigSendType" SG_ 1365 VFCVectorTRMVFCid50 1;
BA_ "GenSigSendType" SG_ 1365 VFCVectorTRMVFCid51 1;
BA_ "GenSigSendType" SG_ 1365 VFCVectorTRMVFCid52 1;
BA_ "GenSigSendType" SG_ 1365 VFCVectorTRMVFCid53 1;
BA_ "GenSigSendType" SG_ 1365 VFCVectorTRMVFCid54 1;
BA_ "GenSigSendType" SG_ 1365 VFCVectorTRMVFCid55 1;
BA_ "GenSigSendType" SG_ 1365 VFCVectorTRMVFCid56 1;
BA_ "GenSigSendType" SG_ 1365 VFCVectorTRMVFCid57 1;
BA_ "GenSigSendType" SG_ 1365 VFCVectorTRMVFCid58 1;
BA_ "GenSigSendType" SG_ 1365 VFCVectorTRMVFCid59 1;
BA_ "GenSigSendType" SG_ 1365 VFCVectorTRMVFCid6 1;
BA_ "GenSigSendType" SG_ 1365 VFCVectorTRMVFCid60 1;
BA_ "GenSigSendType" SG_ 1365 VFCVectorTRMVFCid61 1;
BA_ "GenSigSendType" SG_ 1365 VFCVectorTRMVFCid7 1;
BA_ "GenSigSendType" SG_ 1365 VFCVectorTRMVFCid8 1;
BA_ "GenSigSendType" SG_ 1365 VFCVectorTRMVFCid9 1;
VAL_ 112 ChdLockLeftSts 0 "OnOffSafe1_OnOffSafeInvld1" 1 "OnOffSafe1_OnOffSafeOn" 2 "OnOffSafe1_OnOffSafeOff" 3 "OnOffSafe1_OnOffSafeInvld2" ;
VAL_ 112 DoorLeReCinhIntFailInfCinchFlt1 0 "Boolean_FALSE" 1 "Boolean_TRUE" ;
VAL_ 112 DoorLeReCinhIntFailInfCinchRestF 0 "Boolean_FALSE" 1 "Boolean_TRUE" ;
VAL_ 112 DoorLeReHndlHMIStsDeployedOverTm 0 "Boolean_FALSE" 1 "Boolean_TRUE" ;
VAL_ 112 DoorLeReHndlHMIStsReserved1 0 "Boolean_FALSE" 1 "Boolean_TRUE" ;
VAL_ 112 DoorLeReHndlHMIStsRetractOverTmd 0 "Boolean_FALSE" 1 "Boolean_TRUE" ;
VAL_ 112 DoorLeReHndlHMIStsUnsScsHallSnsr 0 "Boolean_FALSE" 1 "Boolean_TRUE" ;
VAL_ 112 DoorLeReHndlSts 0 "DoorHndlSts_Ukwn" 1 "DoorHndlSts_FullRtrctd" 2 "DoorHndlSts_MovgOut" 3 "DoorHndlSts_StopDurgDply" 4 "DoorHndlSts_FullDplyd" 5 "DoorHndlSts_MovgIn" 6 "DoorHndlSts_StopDurgRtrct" 7 "DoorHndlSts_Flt" ;
VAL_ 112 DoorLeReLatPawlSt 0 "DoorSts2_Ukwn" 1 "DoorSts2_Opend" 2 "DoorSts2_Clsd" ;
VAL_ 112 DoorLeReLatPosn 0 "DoorPos_Undefined" 1 "DoorPos_FullyClosed" 2 "DoorPos_SecondaryPosition" 3 "DoorPos_FullyOpen" ;
VAL_ 112 DoorLeReLockSts 0 "LockSts2_LockStsUkwn" 1 "LockSts2_Unlckd" 2 "LockSts2_Lockd" 3 "LockSts2_SafeLockd" ;
VAL_ 112 DoorLeReOpenLowReqOutdSwt1 0 "PsdNotPsd3_NoInfo1" 1 "PsdNotPsd3_Psd" 2 "PsdNotPsd3_NotPsd" 3 "PsdNotPsd3_NoInfo2" ;
VAL_ 112 DoorLeReOpenReqInsdSwt1 0 "PsdNotPsd3_NoInfo1" 1 "PsdNotPsd3_Psd" 2 "PsdNotPsd3_NotPsd" 3 "PsdNotPsd3_NoInfo2" ;
VAL_ 112 DoorLeReRelsFailCinchOverTimed 0 "Boolean_FALSE" 1 "Boolean_TRUE" ;
VAL_ 112 DoorLeReRelsFailFailure1 0 "Boolean_FALSE" 1 "Boolean_TRUE" ;
VAL_ 112 DoorLeReRelsFailMechRels 0 "Boolean_FALSE" 1 "Boolean_TRUE" ;
VAL_ 112 DoorLeReSwtLockgSts 0 "PsdNotPsd1_NotPsd" 1 "PsdNotPsd1_Psd" ;
VAL_ 112 DoorRiRe2Swt1DplyHndl 0 "PsdNotPsd1_NotPsd" 1 "PsdNotPsd1_Psd" ;
VAL_ 112 DoorRiRe2Swt2DplyHndl 0 "PsdNotPsd1_NotPsd" 1 "PsdNotPsd1_Psd" ;
VAL_ 112 PassSeatRemCtrlReDoorLeActrIncSt 0 "SwtHozlSts1_Idle" 1 "SwtHozlSts1_Fwd" 2 "SwtHozlSts1_Backw" ;
VAL_ 112 PassSeatRemCtrlReDoorLeActrSldSt 0 "SwtHozlSts1_Idle" 1 "SwtHozlSts1_Fwd" 2 "SwtHozlSts1_Backw" ;
VAL_ 112 ShortDropWinReLeSts 0 "ShortDropSts_Idle" 1 "ShortDropSts_WindowDown" 2 "ShortDropSts_WindowClosed" 3 "ShortDropSts_NotUsed" ;
VAL_ 112 WinDsblLeftSts 0 "OnOff1_Off" 1 "OnOff1_On" ;
VAL_ 112 WinFailrStsAtReLe 0 "Flt_NoFault" 1 "Flt_Fault" ;
VAL_ 112 WinPosnStsAtReLe 0 "WinAndRoofAndCurtPosnTyp_PosnUkwn" 1 "WinAndRoofAndCurtPosnTyp_ClsFull" 2 "WinAndRoofAndCurtPosnTyp_PercOpen4" 3 "WinAndRoofAndCurtPosnTyp_PercOpen8" 4 "WinAndRoofAndCurtPosnTyp_PercOpen12" 5 "WinAndRoofAndCurtPosnTyp_PercOpen16" 6 "WinAndRoofAndCurtPosnTyp_PercOpen20" 7 "WinAndRoofAndCurtPosnTyp_PercOpen24" 8 "WinAndRoofAndCurtPosnTyp_PercOpen28" 9 "WinAndRoofAndCurtPosnTyp_PercOpen32" 10 "WinAndRoofAndCurtPosnTyp_PercOpen36" 11 "WinAndRoofAndCurtPosnTyp_PercOpen40" 12 "WinAndRoofAndCurtPosnTyp_PercOpen44" 13 "WinAndRoofAndCurtPosnTyp_PercOpen48" 14 "WinAndRoofAndCurtPosnTyp_PercOpen52" 15 "WinAndRoofAndCurtPosnTyp_PercOpen56" 16 "WinAndRoofAndCurtPosnTyp_PercOpen60" 17 "WinAndRoofAndCurtPosnTyp_PercOpen64" 18 "WinAndRoofAndCurtPosnTyp_PercOpen68" 19 "WinAndRoofAndCurtPosnTyp_PercOpen72" 20 "WinAndRoofAndCurtPosnTyp_PercOpen76" 21 "WinAndRoofAndCurtPosnTyp_PercOpen80" 22 "WinAndRoofAndCurtPosnTyp_PercOpen84" 23 "WinAndRoofAndCurtPosnTyp_PercOpen88" 24 "WinAndRoofAndCurtPosnTyp_PercOpen92" 25 "WinAndRoofAndCurtPosnTyp_PercOpen96" 26 "WinAndRoofAndCurtPosnTyp_OpenFull" 27 "WinAndRoofAndCurtPosnTyp_Resd1" 28 "WinAndRoofAndCurtPosnTyp_Resd2" 29 "WinAndRoofAndCurtPosnTyp_Resd3" 30 "WinAndRoofAndCurtPosnTyp_Resd4" 31 "WinAndRoofAndCurtPosnTyp_Movg" ;
VAL_ 112 WinPosReqReRi 0 "WinPosnReq_Idle" 1 "WinPosnReq_UpMan" 2 "WinPosnReq_UpAut" 3 "WinPosnReq_DwnMan" 4 "WinPosnReq_DwnAut" 5 "WinPosnReq_NotDefd" ;
VAL_ 97 ElecChromWinAtReLeFailr 0 "DiagcSig_NoErr" 1 "DiagcSig_IntErr" 2 "DiagcSig_ComErr" 3 "DiagcSig_Spare" ;
VAL_ 1353 VFCVectorRLDMVFCid0 0 "VFCOnOff_Off" 1 "VFCOnOff_On" ;
VAL_ 1353 VFCVectorRLDMVFCid1 0 "VFCOnOff_Off" 1 "VFCOnOff_On" ;
VAL_ 1353 VFCVectorRLDMVFCid10 0 "VFCOnOff_Off" 1 "VFCOnOff_On" ;
VAL_ 1353 VFCVectorRLDMVFCid11 0 "VFCOnOff_Off" 1 "VFCOnOff_On" ;
VAL_ 1353 VFCVectorRLDMVFCid12 0 "VFCOnOff_Off" 1 "VFCOnOff_On" ;
VAL_ 1353 VFCVectorRLDMVFCid13 0 "VFCOnOff_Off" 1 "VFCOnOff_On" ;
VAL_ 1353 VFCVectorRLDMVFCid14 0 "VFCOnOff_Off" 1 "VFCOnOff_On" ;
VAL_ 1353 VFCVectorRLDMVFCid15 0 "VFCOnOff_Off" 1 "VFCOnOff_On" ;
VAL_ 1353 VFCVectorRLDMVFCid16 0 "VFCOnOff_Off" 1 "VFCOnOff_On" ;
VAL_ 1353 VFCVectorRLDMVFCid17 0 "VFCOnOff_Off" 1 "VFCOnOff_On" ;
VAL_ 1353 VFCVectorRLDMVFCid18 0 "VFCOnOff_Off" 1 "VFCOnOff_On" ;
VAL_ 1353 VFCVectorRLDMVFCid19 0 "VFCOnOff_Off" 1 "VFCOnOff_On" ;
VAL_ 1353 VFCVectorRLDMVFCid2 0 "VFCOnOff_Off" 1 "VFCOnOff_On" ;
VAL_ 1353 VFCVectorRLDMVFCid20 0 "VFCOnOff_Off" 1 "VFCOnOff_On" ;
VAL_ 1353 VFCVectorRLDMVFCid21 0 "VFCOnOff_Off" 1 "VFCOnOff_On" ;
VAL_ 1353 VFCVectorRLDMVFCid22 0 "VFCOnOff_Off" 1 "VFCOnOff_On" ;
VAL_ 1353 VFCVectorRLDMVFCid23 0 "VFCOnOff_Off" 1 "VFCOnOff_On" ;
VAL_ 1353 VFCVectorRLDMVFCid24 0 "VFCOnOff_Off" 1 "VFCOnOff_On" ;
VAL_ 1353 VFCVectorRLDMVFCid25 0 "VFCOnOff_Off" 1 "VFCOnOff_On" ;
VAL_ 1353 VFCVectorRLDMVFCid26 0 "VFCOnOff_Off" 1 "VFCOnOff_On" ;
VAL_ 1353 VFCVectorRLDMVFCid27 0 "VFCOnOff_Off" 1 "VFCOnOff_On" ;
VAL_ 1353 VFCVectorRLDMVFCid28 0 "VFCOnOff_Off" 1 "VFCOnOff_On" ;
VAL_ 1353 VFCVectorRLDMVFCid29 0 "VFCOnOff_Off" 1 "VFCOnOff_On" ;
VAL_ 1353 VFCVectorRLDMVFCid3 0 "VFCOnOff_Off" 1 "VFCOnOff_On" ;
VAL_ 1353 VFCVectorRLDMVFCid30 0 "VFCOnOff_Off" 1 "VFCOnOff_On" ;
VAL_ 1353 VFCVectorRLDMVFCid31 0 "VFCOnOff_Off" 1 "VFCOnOff_On" ;
VAL_ 1353 VFCVectorRLDMVFCid32 0 "VFCOnOff_Off" 1 "VFCOnOff_On" ;
VAL_ 1353 VFCVectorRLDMVFCid33 0 "VFCOnOff_Off" 1 "VFCOnOff_On" ;
VAL_ 1353 VFCVectorRLDMVFCid34 0 "VFCOnOff_Off" 1 "VFCOnOff_On" ;
VAL_ 1353 VFCVectorRLDMVFCid35 0 "VFCOnOff_Off" 1 "VFCOnOff_On" ;
VAL_ 1353 VFCVectorRLDMVFCid36 0 "VFCOnOff_Off" 1 "VFCOnOff_On" ;
VAL_ 1353 VFCVectorRLDMVFCid37 0 "VFCOnOff_Off" 1 "VFCOnOff_On" ;
VAL_ 1353 VFCVectorRLDMVFCid38 0 "VFCOnOff_Off" 1 "VFCOnOff_On" ;
VAL_ 1353 VFCVectorRLDMVFCid39 0 "VFCOnOff_Off" 1 "VFCOnOff_On" ;
VAL_ 1353 VFCVectorRLDMVFCid4 0 "VFCOnOff_Off" 1 "VFCOnOff_On" ;
VAL_ 1353 VFCVectorRLDMVFCid40 0 "VFCOnOff_Off" 1 "VFCOnOff_On" ;
VAL_ 1353 VFCVectorRLDMVFCid41 0 "VFCOnOff_Off" 1 "VFCOnOff_On" ;
VAL_ 1353 VFCVectorRLDMVFCid42 0 "VFCOnOff_Off" 1 "VFCOnOff_On" ;
VAL_ 1353 VFCVectorRLDMVFCid43 0 "VFCOnOff_Off" 1 "VFCOnOff_On" ;
VAL_ 1353 VFCVectorRLDMVFCid44 0 "VFCOnOff_Off" 1 "VFCOnOff_On" ;
VAL_ 1353 VFCVectorRLDMVFCid45 0 "VFCOnOff_Off" 1 "VFCOnOff_On" ;
VAL_ 1353 VFCVectorRLDMVFCid46 0 "VFCOnOff_Off" 1 "VFCOnOff_On" ;
VAL_ 1353 VFCVectorRLDMVFCid47 0 "VFCOnOff_Off" 1 "VFCOnOff_On" ;
VAL_ 1353 VFCVectorRLDMVFCid48 0 "VFCOnOff_Off" 1 "VFCOnOff_On" ;
VAL_ 1353 VFCVectorRLDMVFCid49 0 "VFCOnOff_Off" 1 "VFCOnOff_On" ;
VAL_ 1353 VFCVectorRLDMVFCid5 0 "VFCOnOff_Off" 1 "VFCOnOff_On" ;
VAL_ 1353 VFCVectorRLDMVFCid50 0 "VFCOnOff_Off" 1 "VFCOnOff_On" ;
VAL_ 1353 VFCVectorRLDMVFCid51 0 "VFCOnOff_Off" 1 "VFCOnOff_On" ;
VAL_ 1353 VFCVectorRLDMVFCid52 0 "VFCOnOff_Off" 1 "VFCOnOff_On" ;
VAL_ 1353 VFCVectorRLDMVFCid53 0 "VFCOnOff_Off" 1 "VFCOnOff_On" ;
VAL_ 1353 VFCVectorRLDMVFCid54 0 "VFCOnOff_Off" 1 "VFCOnOff_On" ;
VAL_ 1353 VFCVectorRLDMVFCid55 0 "VFCOnOff_Off" 1 "VFCOnOff_On" ;
VAL_ 1353 VFCVectorRLDMVFCid56 0 "VFCOnOff_Off" 1 "VFCOnOff_On" ;
VAL_ 1353 VFCVectorRLDMVFCid57 0 "VFCOnOff_Off" 1 "VFCOnOff_On" ;
VAL_ 1353 VFCVectorRLDMVFCid58 0 "VFCOnOff_Off" 1 "VFCOnOff_On" ;
VAL_ 1353 VFCVectorRLDMVFCid59 0 "VFCOnOff_Off" 1 "VFCOnOff_On" ;
VAL_ 1353 VFCVectorRLDMVFCid6 0 "VFCOnOff_Off" 1 "VFCOnOff_On" ;
VAL_ 1353 VFCVectorRLDMVFCid60 0 "VFCOnOff_Off" 1 "VFCOnOff_On" ;
VAL_ 1353 VFCVectorRLDMVFCid61 0 "VFCOnOff_Off" 1 "VFCOnOff_On" ;
VAL_ 1353 VFCVectorRLDMVFCid7 0 "VFCOnOff_Off" 1 "VFCOnOff_On" ;
VAL_ 1353 VFCVectorRLDMVFCid8 0 "VFCOnOff_Off" 1 "VFCOnOff_On" ;
VAL_ 1353 VFCVectorRLDMVFCid9 0 "VFCOnOff_Off" 1 "VFCOnOff_On" ;
VAL_ 117 ChdLockRightSts 0 "OnOffSafe1_OnOffSafeInvld1" 1 "OnOffSafe1_OnOffSafeOn" 2 "OnOffSafe1_OnOffSafeOff" 3 "OnOffSafe1_OnOffSafeInvld2" ;
VAL_ 117 DoorLeRe2Swt1DplyHndl 0 "PsdNotPsd1_NotPsd" 1 "PsdNotPsd1_Psd" ;
VAL_ 117 DoorLeRe2Swt2DplyHndl 0 "PsdNotPsd1_NotPsd" 1 "PsdNotPsd1_Psd" ;
VAL_ 117 DoorRiReCinhIntFailInfCinchFlt1 0 "Boolean_FALSE" 1 "Boolean_TRUE" ;
VAL_ 117 DoorRiReCinhIntFailInfCinchRestF 0 "Boolean_FALSE" 1 "Boolean_TRUE" ;
VAL_ 117 DoorRiReHndlHMIStsDeployedOverTm 0 "Boolean_FALSE" 1 "Boolean_TRUE" ;
VAL_ 117 DoorRiReHndlHMIStsReserved1 0 "Boolean_FALSE" 1 "Boolean_TRUE" ;
VAL_ 117 DoorRiReHndlHMIStsRetractOverTmd 0 "Boolean_FALSE" 1 "Boolean_TRUE" ;
VAL_ 117 DoorRiReHndlHMIStsUnsScsHallSnsr 0 "Boolean_FALSE" 1 "Boolean_TRUE" ;
VAL_ 117 DoorRiReHndlSts 0 "DoorHndlSts_Ukwn" 1 "DoorHndlSts_FullRtrctd" 2 "DoorHndlSts_MovgOut" 3 "DoorHndlSts_StopDurgDply" 4 "DoorHndlSts_FullDplyd" 5 "DoorHndlSts_MovgIn" 6 "DoorHndlSts_StopDurgRtrct" 7 "DoorHndlSts_Flt" ;
VAL_ 117 DoorRiReLatPawlSt 0 "DoorSts2_Ukwn" 1 "DoorSts2_Opend" 2 "DoorSts2_Clsd" ;
VAL_ 117 DoorRiReLatPosn 0 "DoorPos_Undefined" 1 "DoorPos_FullyClosed" 2 "DoorPos_SecondaryPosition" 3 "DoorPos_FullyOpen" ;
VAL_ 117 DoorRiReLockSts 0 "LockSts2_LockStsUkwn" 1 "LockSts2_Unlckd" 2 "LockSts2_Lockd" 3 "LockSts2_SafeLockd" ;
VAL_ 117 DoorRiReOpenLowReqOutdSwt1 0 "PsdNotPsd3_NoInfo1" 1 "PsdNotPsd3_Psd" 2 "PsdNotPsd3_NotPsd" 3 "PsdNotPsd3_NoInfo2" ;
VAL_ 117 DoorRiReOpenReqInsdSwt1 0 "PsdNotPsd3_NoInfo1" 1 "PsdNotPsd3_Psd" 2 "PsdNotPsd3_NotPsd" 3 "PsdNotPsd3_NoInfo2" ;
VAL_ 117 DoorRiReRelsFailCinchOverTimed 0 "Boolean_FALSE" 1 "Boolean_TRUE" ;
VAL_ 117 DoorRiReRelsFailFailure1 0 "Boolean_FALSE" 1 "Boolean_TRUE" ;
VAL_ 117 DoorRiReRelsFailMechRels 0 "Boolean_FALSE" 1 "Boolean_TRUE" ;
VAL_ 117 DoorRiReSwtLockgSts 0 "PsdNotPsd1_NotPsd" 1 "PsdNotPsd1_Psd" ;
VAL_ 117 PassSeatRemCtrlReDoorRiActrIncSt 0 "SwtHozlSts1_Idle" 1 "SwtHozlSts1_Fwd" 2 "SwtHozlSts1_Backw" ;
VAL_ 117 PassSeatRemCtrlReDoorRiActrSldSt 0 "SwtHozlSts1_Idle" 1 "SwtHozlSts1_Fwd" 2 "SwtHozlSts1_Backw" ;
VAL_ 117 ShortDropWinReRiSts 0 "ShortDropSts_Idle" 1 "ShortDropSts_WindowDown" 2 "ShortDropSts_WindowClosed" 3 "ShortDropSts_NotUsed" ;
VAL_ 117 WinDsblRightSts 0 "OnOff1_Off" 1 "OnOff1_On" ;
VAL_ 117 WinFailrStsAtReRi 0 "Flt_NoFault" 1 "Flt_Fault" ;
VAL_ 117 WinPosnStsAtReRi 0 "WinAndRoofAndCurtPosnTyp_PosnUkwn" 1 "WinAndRoofAndCurtPosnTyp_ClsFull" 2 "WinAndRoofAndCurtPosnTyp_PercOpen4" 3 "WinAndRoofAndCurtPosnTyp_PercOpen8" 4 "WinAndRoofAndCurtPosnTyp_PercOpen12" 5 "WinAndRoofAndCurtPosnTyp_PercOpen16" 6 "WinAndRoofAndCurtPosnTyp_PercOpen20" 7 "WinAndRoofAndCurtPosnTyp_PercOpen24" 8 "WinAndRoofAndCurtPosnTyp_PercOpen28" 9 "WinAndRoofAndCurtPosnTyp_PercOpen32" 10 "WinAndRoofAndCurtPosnTyp_PercOpen36" 11 "WinAndRoofAndCurtPosnTyp_PercOpen40" 12 "WinAndRoofAndCurtPosnTyp_PercOpen44" 13 "WinAndRoofAndCurtPosnTyp_PercOpen48" 14 "WinAndRoofAndCurtPosnTyp_PercOpen52" 15 "WinAndRoofAndCurtPosnTyp_PercOpen56" 16 "WinAndRoofAndCurtPosnTyp_PercOpen60" 17 "WinAndRoofAndCurtPosnTyp_PercOpen64" 18 "WinAndRoofAndCurtPosnTyp_PercOpen68" 19 "WinAndRoofAndCurtPosnTyp_PercOpen72" 20 "WinAndRoofAndCurtPosnTyp_PercOpen76" 21 "WinAndRoofAndCurtPosnTyp_PercOpen80" 22 "WinAndRoofAndCurtPosnTyp_PercOpen84" 23 "WinAndRoofAndCurtPosnTyp_PercOpen88" 24 "WinAndRoofAndCurtPosnTyp_PercOpen92" 25 "WinAndRoofAndCurtPosnTyp_PercOpen96" 26 "WinAndRoofAndCurtPosnTyp_OpenFull" 27 "WinAndRoofAndCurtPosnTyp_Resd1" 28 "WinAndRoofAndCurtPosnTyp_Resd2" 29 "WinAndRoofAndCurtPosnTyp_Resd3" 30 "WinAndRoofAndCurtPosnTyp_Resd4" 31 "WinAndRoofAndCurtPosnTyp_Movg" ;
VAL_ 117 WinPosReqReLe 0 "WinPosnReq_Idle" 1 "WinPosnReq_UpMan" 2 "WinPosnReq_UpAut" 3 "WinPosnReq_DwnMan" 4 "WinPosnReq_DwnAut" 5 "WinPosnReq_NotDefd" ;
VAL_ 102 ElecChromWinAtReRiFailr 0 "DiagcSig_NoErr" 1 "DiagcSig_IntErr" 2 "DiagcSig_ComErr" 3 "DiagcSig_Spare" ;
VAL_ 1360 VFCVectorRRDMVFCid0 0 "VFCOnOff_Off" 1 "VFCOnOff_On" ;
VAL_ 1360 VFCVectorRRDMVFCid1 0 "VFCOnOff_Off" 1 "VFCOnOff_On" ;
VAL_ 1360 VFCVectorRRDMVFCid10 0 "VFCOnOff_Off" 1 "VFCOnOff_On" ;
VAL_ 1360 VFCVectorRRDMVFCid11 0 "VFCOnOff_Off" 1 "VFCOnOff_On" ;
VAL_ 1360 VFCVectorRRDMVFCid12 0 "VFCOnOff_Off" 1 "VFCOnOff_On" ;
VAL_ 1360 VFCVectorRRDMVFCid13 0 "VFCOnOff_Off" 1 "VFCOnOff_On" ;
VAL_ 1360 VFCVectorRRDMVFCid14 0 "VFCOnOff_Off" 1 "VFCOnOff_On" ;
VAL_ 1360 VFCVectorRRDMVFCid15 0 "VFCOnOff_Off" 1 "VFCOnOff_On" ;
VAL_ 1360 VFCVectorRRDMVFCid16 0 "VFCOnOff_Off" 1 "VFCOnOff_On" ;
VAL_ 1360 VFCVectorRRDMVFCid17 0 "VFCOnOff_Off" 1 "VFCOnOff_On" ;
VAL_ 1360 VFCVectorRRDMVFCid18 0 "VFCOnOff_Off" 1 "VFCOnOff_On" ;
VAL_ 1360 VFCVectorRRDMVFCid19 0 "VFCOnOff_Off" 1 "VFCOnOff_On" ;
VAL_ 1360 VFCVectorRRDMVFCid2 0 "VFCOnOff_Off" 1 "VFCOnOff_On" ;
VAL_ 1360 VFCVectorRRDMVFCid20 0 "VFCOnOff_Off" 1 "VFCOnOff_On" ;
VAL_ 1360 VFCVectorRRDMVFCid21 0 "VFCOnOff_Off" 1 "VFCOnOff_On" ;
VAL_ 1360 VFCVectorRRDMVFCid22 0 "VFCOnOff_Off" 1 "VFCOnOff_On" ;
VAL_ 1360 VFCVectorRRDMVFCid23 0 "VFCOnOff_Off" 1 "VFCOnOff_On" ;
VAL_ 1360 VFCVectorRRDMVFCid24 0 "VFCOnOff_Off" 1 "VFCOnOff_On" ;
VAL_ 1360 VFCVectorRRDMVFCid25 0 "VFCOnOff_Off" 1 "VFCOnOff_On" ;
VAL_ 1360 VFCVectorRRDMVFCid26 0 "VFCOnOff_Off" 1 "VFCOnOff_On" ;
VAL_ 1360 VFCVectorRRDMVFCid27 0 "VFCOnOff_Off" 1 "VFCOnOff_On" ;
VAL_ 1360 VFCVectorRRDMVFCid28 0 "VFCOnOff_Off" 1 "VFCOnOff_On" ;
VAL_ 1360 VFCVectorRRDMVFCid29 0 "VFCOnOff_Off" 1 "VFCOnOff_On" ;
VAL_ 1360 VFCVectorRRDMVFCid3 0 "VFCOnOff_Off" 1 "VFCOnOff_On" ;
VAL_ 1360 VFCVectorRRDMVFCid30 0 "VFCOnOff_Off" 1 "VFCOnOff_On" ;
VAL_ 1360 VFCVectorRRDMVFCid31 0 "VFCOnOff_Off" 1 "VFCOnOff_On" ;
VAL_ 1360 VFCVectorRRDMVFCid32 0 "VFCOnOff_Off" 1 "VFCOnOff_On" ;
VAL_ 1360 VFCVectorRRDMVFCid33 0 "VFCOnOff_Off" 1 "VFCOnOff_On" ;
VAL_ 1360 VFCVectorRRDMVFCid34 0 "VFCOnOff_Off" 1 "VFCOnOff_On" ;
VAL_ 1360 VFCVectorRRDMVFCid35 0 "VFCOnOff_Off" 1 "VFCOnOff_On" ;
VAL_ 1360 VFCVectorRRDMVFCid36 0 "VFCOnOff_Off" 1 "VFCOnOff_On" ;
VAL_ 1360 VFCVectorRRDMVFCid37 0 "VFCOnOff_Off" 1 "VFCOnOff_On" ;
VAL_ 1360 VFCVectorRRDMVFCid38 0 "VFCOnOff_Off" 1 "VFCOnOff_On" ;
VAL_ 1360 VFCVectorRRDMVFCid39 0 "VFCOnOff_Off" 1 "VFCOnOff_On" ;
VAL_ 1360 VFCVectorRRDMVFCid4 0 "VFCOnOff_Off" 1 "VFCOnOff_On" ;
VAL_ 1360 VFCVectorRRDMVFCid40 0 "VFCOnOff_Off" 1 "VFCOnOff_On" ;
VAL_ 1360 VFCVectorRRDMVFCid41 0 "VFCOnOff_Off" 1 "VFCOnOff_On" ;
VAL_ 1360 VFCVectorRRDMVFCid42 0 "VFCOnOff_Off" 1 "VFCOnOff_On" ;
VAL_ 1360 VFCVectorRRDMVFCid43 0 "VFCOnOff_Off" 1 "VFCOnOff_On" ;
VAL_ 1360 VFCVectorRRDMVFCid44 0 "VFCOnOff_Off" 1 "VFCOnOff_On" ;
VAL_ 1360 VFCVectorRRDMVFCid45 0 "VFCOnOff_Off" 1 "VFCOnOff_On" ;
VAL_ 1360 VFCVectorRRDMVFCid46 0 "VFCOnOff_Off" 1 "VFCOnOff_On" ;
VAL_ 1360 VFCVectorRRDMVFCid47 0 "VFCOnOff_Off" 1 "VFCOnOff_On" ;
VAL_ 1360 VFCVectorRRDMVFCid48 0 "VFCOnOff_Off" 1 "VFCOnOff_On" ;
VAL_ 1360 VFCVectorRRDMVFCid49 0 "VFCOnOff_Off" 1 "VFCOnOff_On" ;
VAL_ 1360 VFCVectorRRDMVFCid5 0 "VFCOnOff_Off" 1 "VFCOnOff_On" ;
VAL_ 1360 VFCVectorRRDMVFCid50 0 "VFCOnOff_Off" 1 "VFCOnOff_On" ;
VAL_ 1360 VFCVectorRRDMVFCid51 0 "VFCOnOff_Off" 1 "VFCOnOff_On" ;
VAL_ 1360 VFCVectorRRDMVFCid52 0 "VFCOnOff_Off" 1 "VFCOnOff_On" ;
VAL_ 1360 VFCVectorRRDMVFCid53 0 "VFCOnOff_Off" 1 "VFCOnOff_On" ;
VAL_ 1360 VFCVectorRRDMVFCid54 0 "VFCOnOff_Off" 1 "VFCOnOff_On" ;
VAL_ 1360 VFCVectorRRDMVFCid55 0 "VFCOnOff_Off" 1 "VFCOnOff_On" ;
VAL_ 1360 VFCVectorRRDMVFCid56 0 "VFCOnOff_Off" 1 "VFCOnOff_On" ;
VAL_ 1360 VFCVectorRRDMVFCid57 0 "VFCOnOff_Off" 1 "VFCOnOff_On" ;
VAL_ 1360 VFCVectorRRDMVFCid58 0 "VFCOnOff_Off" 1 "VFCOnOff_On" ;
VAL_ 1360 VFCVectorRRDMVFCid59 0 "VFCOnOff_Off" 1 "VFCOnOff_On" ;
VAL_ 1360 VFCVectorRRDMVFCid6 0 "VFCOnOff_Off" 1 "VFCOnOff_On" ;
VAL_ 1360 VFCVectorRRDMVFCid60 0 "VFCOnOff_Off" 1 "VFCOnOff_On" ;
VAL_ 1360 VFCVectorRRDMVFCid61 0 "VFCOnOff_Off" 1 "VFCOnOff_On" ;
VAL_ 1360 VFCVectorRRDMVFCid7 0 "VFCOnOff_Off" 1 "VFCOnOff_On" ;
VAL_ 1360 VFCVectorRRDMVFCid8 0 "VFCOnOff_Off" 1 "VFCOnOff_On" ;
VAL_ 1360 VFCVectorRRDMVFCid9 0 "VFCOnOff_Off" 1 "VFCOnOff_On" ;
VAL_ 105 DrvrCtrlOfPassSeatFrntSts 0 "ActvnAvl1_NotAvl" 1 "ActvnAvl1_Avl" 2 "ActvnAvl1_Deactvd" 3 "ActvnAvl1_Actvd" ;
VAL_ 105 DrvrSeatBtnPsd 0 "Boolean_FALSE" 1 "Boolean_TRUE" ;
VAL_ 105 DrvrSeatInAutMovmt 0 "Boolean_FALSE" 1 "Boolean_TRUE" ;
VAL_ 105 DrvrSeatMemSts 0 "Sts_Resd" 1 "Sts_Err" 2 "Sts_CmplOk" 3 "Sts_InProgs" ;
VAL_ 864 DrvrSeatHallPosDownLdSts 0 "Sts_Resd" 1 "Sts_Err" 2 "Sts_CmplOk" 3 "Sts_InProgs" ;
VAL_ 665 DrvrMassgRunng 0 "OnOff1_Off" 1 "OnOff1_On" ;
VAL_ 665 DrvrSeatActvSpplFct 0 "SeatActvSpplFct1_NotAvl" 1 "SeatActvSpplFct1_LumExtnAndLumHei" 2 "SeatActvSpplFct1_BackBlster" 3 "SeatActvSpplFct1_CushExtn" 4 "SeatActvSpplFct1_HdrestHeiAndHdrestTilt" 5 "SeatActvSpplFct1_MassgFct" 6 "SeatActvSpplFct1_ShoulderFct" 7 "SeatActvSpplFct1_LegrestFct" ;
VAL_ 665 DrvrSeatHeatgAvlSts 0 "StsFd_None" 1 "StsFd_On" 2 "StsFd_Off" 3 "StsFd_Error" 4 "StsFd_Functionallimit" 5 "StsFd_Energylimit" 6 "StsFd_Resvd1" 7 "StsFd_Resvd2" ;
VAL_ 665 DrvrSeatHeatgLvlSts 0 "SeatClimaLvl_Off" 1 "SeatClimaLvl_Lvl1" 2 "SeatClimaLvl_Lvl2" 3 "SeatClimaLvl_Lvl3" ;
VAL_ 665 DrvrSeatMassgFctReq 0 "Boolean_FALSE" 1 "Boolean_TRUE" ;
VAL_ 665 DrvrSeatSwtStsDrvrSeatSwtAdjmtOf 0 "SwtHozlSts1_Idle" 1 "SwtHozlSts1_Fwd" 2 "SwtHozlSts1_Backw" ;
VAL_ 665 DrvrSeatSwtStsDrvrSeatSwtAd_0000 0 "SwtVertSts1_Idle" 1 "SwtVertSts1_Up" 2 "SwtVertSts1_Dwn" ;
VAL_ 665 DrvrSeatSwtStsDrvrSeatSwtHdrstHo 0 "SwtHozlSts1_Idle" 1 "SwtHozlSts1_Fwd" 2 "SwtHozlSts1_Backw" ;
VAL_ 665 DrvrSeatSwtStsDrvrSeatSwtHdrstVe 0 "SwtVertSts1_Idle" 1 "SwtVertSts1_Up" 2 "SwtVertSts1_Dwn" ;
VAL_ 665 DrvrSeatSwtStsDrvrSeatSwtHeiFrnt 0 "SwtVertSts1_Idle" 1 "SwtVertSts1_Up" 2 "SwtVertSts1_Dwn" ;
VAL_ 665 DrvrSeatSwtStsDrvrSeatSwtHeiSts 0 "SwtVertSts1_Idle" 1 "SwtVertSts1_Up" 2 "SwtVertSts1_Dwn" ;
VAL_ 665 DrvrSeatSwtStsDrvrSeatSwtInclSts 0 "SwtHozlSts1_Idle" 1 "SwtHozlSts1_Fwd" 2 "SwtHozlSts1_Backw" ;
VAL_ 665 DrvrSeatSwtStsDrvrSeatSwtSelnOfS 0 "SwtVertSts1_Idle" 1 "SwtVertSts1_Up" 2 "SwtVertSts1_Dwn" ;
VAL_ 665 DrvrSeatSwtStsDrvrSeatSwtSldSts 0 "SwtHozlSts1_Idle" 1 "SwtHozlSts1_Fwd" 2 "SwtHozlSts1_Backw" ;
VAL_ 665 DrvrSeatVentAvlSts 0 "StsFd_None" 1 "StsFd_On" 2 "StsFd_Off" 3 "StsFd_Error" 4 "StsFd_Functionallimit" 5 "StsFd_Energylimit" 6 "StsFd_Resvd1" 7 "StsFd_Resvd2" ;
VAL_ 665 DrvrSeatVentnLvlSts 0 "SeatClimaLvl_Off" 1 "SeatClimaLvl_Lvl1" 2 "SeatClimaLvl_Lvl2" 3 "SeatClimaLvl_Lvl3" ;
VAL_ 272 DrvrSeatExtAdjAllowd 0 "Boolean_FALSE" 1 "Boolean_TRUE" ;
VAL_ 272 DrvrSeatPosPercSeatPosFrntHeiQF 0 "Qf1_DevOfDataUndefd" 1 "Qf1_DataTmpUndefdAndEvlnInProgs" 2 "Qf1_DevOfDataNotWithinRngAllwd" 3 "Qf1_DataCalcdWithDevDefd" ;
VAL_ 272 DrvrSeatPosPercSeatPosHeiQF 0 "Qf1_DevOfDataUndefd" 1 "Qf1_DataTmpUndefdAndEvlnInProgs" 2 "Qf1_DevOfDataNotWithinRngAllwd" 3 "Qf1_DataCalcdWithDevDefd" ;
VAL_ 272 DrvrSeatPosPercSeatPosSldQF 0 "Qf1_DevOfDataUndefd" 1 "Qf1_DataTmpUndefdAndEvlnInProgs" 2 "Qf1_DevOfDataNotWithinRngAllwd" 3 "Qf1_DataCalcdWithDevDefd" ;
VAL_ 547 DrvrSeatActvSwtFctMod 0 "SwtFctMod_Mod1" 1 "SwtFctMod_Mod2" 2 "SwtFctMod_Mod3" 3 "SwtFctMod_Mod4" ;
VAL_ 547 DrvrSeatIntgrSwtStsIntgrSwtHozlS 0 "SwtHozlSts1_Idle" 1 "SwtHozlSts1_Fwd" 2 "SwtHozlSts1_Backw" ;
VAL_ 547 DrvrSeatIntgrSwtStsIntgrSwtRotSt 0 "SwtHozlSts1_Idle" 1 "SwtHozlSts1_Fwd" 2 "SwtHozlSts1_Backw" ;
VAL_ 547 DrvrSeatIntgrSwtStsIntgrSwtSelnS 0 "SwtVertSts1_Idle" 1 "SwtVertSts1_Up" 2 "SwtVertSts1_Dwn" ;
VAL_ 547 DrvrSeatIntgrSwtStsIntgrSwtVertS 0 "SwtVertSts1_Idle" 1 "SwtVertSts1_Up" 2 "SwtVertSts1_Dwn" ;
VAL_ 547 DrvrSeatPivtPosPercSeatPosQf 0 "Qf1_DevOfDataUndefd" 1 "Qf1_DataTmpUndefdAndEvlnInProgs" 2 "Qf1_DevOfDataNotWithinRngAllwd" 3 "Qf1_DataCalcdWithDevDefd" ;
VAL_ 547 DrvrSeatSwtBlstrSts 0 "SwtHozlSts1_Idle" 1 "SwtHozlSts1_Fwd" 2 "SwtHozlSts1_Backw" ;
VAL_ 547 DrvrSeatSwtCushExtSts 0 "SwtHozlSts1_Idle" 1 "SwtHozlSts1_Fwd" 2 "SwtHozlSts1_Backw" ;
VAL_ 1362 VFCVectorSMDVFCid0 0 "VFCOnOff_Off" 1 "VFCOnOff_On" ;
VAL_ 1362 VFCVectorSMDVFCid1 0 "VFCOnOff_Off" 1 "VFCOnOff_On" ;
VAL_ 1362 VFCVectorSMDVFCid10 0 "VFCOnOff_Off" 1 "VFCOnOff_On" ;
VAL_ 1362 VFCVectorSMDVFCid11 0 "VFCOnOff_Off" 1 "VFCOnOff_On" ;
VAL_ 1362 VFCVectorSMDVFCid12 0 "VFCOnOff_Off" 1 "VFCOnOff_On" ;
VAL_ 1362 VFCVectorSMDVFCid13 0 "VFCOnOff_Off" 1 "VFCOnOff_On" ;
VAL_ 1362 VFCVectorSMDVFCid14 0 "VFCOnOff_Off" 1 "VFCOnOff_On" ;
VAL_ 1362 VFCVectorSMDVFCid15 0 "VFCOnOff_Off" 1 "VFCOnOff_On" ;
VAL_ 1362 VFCVectorSMDVFCid16 0 "VFCOnOff_Off" 1 "VFCOnOff_On" ;
VAL_ 1362 VFCVectorSMDVFCid17 0 "VFCOnOff_Off" 1 "VFCOnOff_On" ;
VAL_ 1362 VFCVectorSMDVFCid18 0 "VFCOnOff_Off" 1 "VFCOnOff_On" ;
VAL_ 1362 VFCVectorSMDVFCid19 0 "VFCOnOff_Off" 1 "VFCOnOff_On" ;
VAL_ 1362 VFCVectorSMDVFCid2 0 "VFCOnOff_Off" 1 "VFCOnOff_On" ;
VAL_ 1362 VFCVectorSMDVFCid20 0 "VFCOnOff_Off" 1 "VFCOnOff_On" ;
VAL_ 1362 VFCVectorSMDVFCid21 0 "VFCOnOff_Off" 1 "VFCOnOff_On" ;
VAL_ 1362 VFCVectorSMDVFCid22 0 "VFCOnOff_Off" 1 "VFCOnOff_On" ;
VAL_ 1362 VFCVectorSMDVFCid23 0 "VFCOnOff_Off" 1 "VFCOnOff_On" ;
VAL_ 1362 VFCVectorSMDVFCid24 0 "VFCOnOff_Off" 1 "VFCOnOff_On" ;
VAL_ 1362 VFCVectorSMDVFCid25 0 "VFCOnOff_Off" 1 "VFCOnOff_On" ;
VAL_ 1362 VFCVectorSMDVFCid26 0 "VFCOnOff_Off" 1 "VFCOnOff_On" ;
VAL_ 1362 VFCVectorSMDVFCid27 0 "VFCOnOff_Off" 1 "VFCOnOff_On" ;
VAL_ 1362 VFCVectorSMDVFCid28 0 "VFCOnOff_Off" 1 "VFCOnOff_On" ;
VAL_ 1362 VFCVectorSMDVFCid29 0 "VFCOnOff_Off" 1 "VFCOnOff_On" ;
VAL_ 1362 VFCVectorSMDVFCid3 0 "VFCOnOff_Off" 1 "VFCOnOff_On" ;
VAL_ 1362 VFCVectorSMDVFCid30 0 "VFCOnOff_Off" 1 "VFCOnOff_On" ;
VAL_ 1362 VFCVectorSMDVFCid31 0 "VFCOnOff_Off" 1 "VFCOnOff_On" ;
VAL_ 1362 VFCVectorSMDVFCid32 0 "VFCOnOff_Off" 1 "VFCOnOff_On" ;
VAL_ 1362 VFCVectorSMDVFCid33 0 "VFCOnOff_Off" 1 "VFCOnOff_On" ;
VAL_ 1362 VFCVectorSMDVFCid34 0 "VFCOnOff_Off" 1 "VFCOnOff_On" ;
VAL_ 1362 VFCVectorSMDVFCid35 0 "VFCOnOff_Off" 1 "VFCOnOff_On" ;
VAL_ 1362 VFCVectorSMDVFCid36 0 "VFCOnOff_Off" 1 "VFCOnOff_On" ;
VAL_ 1362 VFCVectorSMDVFCid37 0 "VFCOnOff_Off" 1 "VFCOnOff_On" ;
VAL_ 1362 VFCVectorSMDVFCid38 0 "VFCOnOff_Off" 1 "VFCOnOff_On" ;
VAL_ 1362 VFCVectorSMDVFCid39 0 "VFCOnOff_Off" 1 "VFCOnOff_On" ;
VAL_ 1362 VFCVectorSMDVFCid4 0 "VFCOnOff_Off" 1 "VFCOnOff_On" ;
VAL_ 1362 VFCVectorSMDVFCid40 0 "VFCOnOff_Off" 1 "VFCOnOff_On" ;
VAL_ 1362 VFCVectorSMDVFCid41 0 "VFCOnOff_Off" 1 "VFCOnOff_On" ;
VAL_ 1362 VFCVectorSMDVFCid42 0 "VFCOnOff_Off" 1 "VFCOnOff_On" ;
VAL_ 1362 VFCVectorSMDVFCid43 0 "VFCOnOff_Off" 1 "VFCOnOff_On" ;
VAL_ 1362 VFCVectorSMDVFCid44 0 "VFCOnOff_Off" 1 "VFCOnOff_On" ;
VAL_ 1362 VFCVectorSMDVFCid45 0 "VFCOnOff_Off" 1 "VFCOnOff_On" ;
VAL_ 1362 VFCVectorSMDVFCid46 0 "VFCOnOff_Off" 1 "VFCOnOff_On" ;
VAL_ 1362 VFCVectorSMDVFCid47 0 "VFCOnOff_Off" 1 "VFCOnOff_On" ;
VAL_ 1362 VFCVectorSMDVFCid48 0 "VFCOnOff_Off" 1 "VFCOnOff_On" ;
VAL_ 1362 VFCVectorSMDVFCid49 0 "VFCOnOff_Off" 1 "VFCOnOff_On" ;
VAL_ 1362 VFCVectorSMDVFCid5 0 "VFCOnOff_Off" 1 "VFCOnOff_On" ;
VAL_ 1362 VFCVectorSMDVFCid50 0 "VFCOnOff_Off" 1 "VFCOnOff_On" ;
VAL_ 1362 VFCVectorSMDVFCid51 0 "VFCOnOff_Off" 1 "VFCOnOff_On" ;
VAL_ 1362 VFCVectorSMDVFCid52 0 "VFCOnOff_Off" 1 "VFCOnOff_On" ;
VAL_ 1362 VFCVectorSMDVFCid53 0 "VFCOnOff_Off" 1 "VFCOnOff_On" ;
VAL_ 1362 VFCVectorSMDVFCid54 0 "VFCOnOff_Off" 1 "VFCOnOff_On" ;
VAL_ 1362 VFCVectorSMDVFCid55 0 "VFCOnOff_Off" 1 "VFCOnOff_On" ;
VAL_ 1362 VFCVectorSMDVFCid56 0 "VFCOnOff_Off" 1 "VFCOnOff_On" ;
VAL_ 1362 VFCVectorSMDVFCid57 0 "VFCOnOff_Off" 1 "VFCOnOff_On" ;
VAL_ 1362 VFCVectorSMDVFCid58 0 "VFCOnOff_Off" 1 "VFCOnOff_On" ;
VAL_ 1362 VFCVectorSMDVFCid59 0 "VFCOnOff_Off" 1 "VFCOnOff_On" ;
VAL_ 1362 VFCVectorSMDVFCid6 0 "VFCOnOff_Off" 1 "VFCOnOff_On" ;
VAL_ 1362 VFCVectorSMDVFCid60 0 "VFCOnOff_Off" 1 "VFCOnOff_On" ;
VAL_ 1362 VFCVectorSMDVFCid61 0 "VFCOnOff_Off" 1 "VFCOnOff_On" ;
VAL_ 1362 VFCVectorSMDVFCid7 0 "VFCOnOff_Off" 1 "VFCOnOff_On" ;
VAL_ 1362 VFCVectorSMDVFCid8 0 "VFCOnOff_Off" 1 "VFCOnOff_On" ;
VAL_ 1362 VFCVectorSMDVFCid9 0 "VFCOnOff_Off" 1 "VFCOnOff_On" ;
VAL_ 304 PassSeatBtnPsd 0 "Boolean_FALSE" 1 "Boolean_TRUE" ;
VAL_ 304 PassSeatInAutMovmt 0 "Boolean_FALSE" 1 "Boolean_TRUE" ;
VAL_ 304 PassSeatMemSts 0 "Sts_Resd" 1 "Sts_Err" 2 "Sts_CmplOk" 3 "Sts_InProgs" ;
VAL_ 275 PassSeatMassgFctReq 0 "Boolean_FALSE" 1 "Boolean_TRUE" ;
VAL_ 275 PassSeatPosPercSeatPosFrntHeiQF 0 "Qf1_DevOfDataUndefd" 1 "Qf1_DataTmpUndefdAndEvlnInProgs" 2 "Qf1_DevOfDataNotWithinRngAllwd" 3 "Qf1_DataCalcdWithDevDefd" ;
VAL_ 275 PassSeatPosPercSeatPosHeiQF 0 "Qf1_DevOfDataUndefd" 1 "Qf1_DataTmpUndefdAndEvlnInProgs" 2 "Qf1_DevOfDataNotWithinRngAllwd" 3 "Qf1_DataCalcdWithDevDefd" ;
VAL_ 275 PassSeatPosPercSeatPosSldQF 0 "Qf1_DevOfDataUndefd" 1 "Qf1_DataTmpUndefdAndEvlnInProgs" 2 "Qf1_DevOfDataNotWithinRngAllwd" 3 "Qf1_DataCalcdWithDevDefd" ;
VAL_ 1063 PassMassgRunng 0 "OnOff1_Off" 1 "OnOff1_On" ;
VAL_ 1063 PassSeatActvSpplFct 0 "SeatActvSpplFct1_NotAvl" 1 "SeatActvSpplFct1_LumExtnAndLumHei" 2 "SeatActvSpplFct1_BackBlster" 3 "SeatActvSpplFct1_CushExtn" 4 "SeatActvSpplFct1_HdrestHeiAndHdrestTilt" 5 "SeatActvSpplFct1_MassgFct" 6 "SeatActvSpplFct1_ShoulderFct" 7 "SeatActvSpplFct1_LegrestFct" ;
VAL_ 1063 PassSeatHeatgAvlSts 0 "StsFd_None" 1 "StsFd_On" 2 "StsFd_Off" 3 "StsFd_Error" 4 "StsFd_Functionallimit" 5 "StsFd_Energylimit" 6 "StsFd_Resvd1" 7 "StsFd_Resvd2" ;
VAL_ 1063 PassSeatHeatgLvlSts 0 "SeatClimaLvl_Off" 1 "SeatClimaLvl_Lvl1" 2 "SeatClimaLvl_Lvl2" 3 "SeatClimaLvl_Lvl3" ;
VAL_ 1063 PassSeatPivtPosPercSeatPosQf 0 "Qf1_DevOfDataUndefd" 1 "Qf1_DataTmpUndefdAndEvlnInProgs" 2 "Qf1_DevOfDataNotWithinRngAllwd" 3 "Qf1_DataCalcdWithDevDefd" ;
VAL_ 1063 PassSeatSwtSts2PassSeatSwtAdjmtO 0 "SwtHozlSts1_Idle" 1 "SwtHozlSts1_Fwd" 2 "SwtHozlSts1_Backw" ;
VAL_ 1063 PassSeatSwtSts2PassSeatSwtA_0000 0 "SwtVertSts1_Idle" 1 "SwtVertSts1_Up" 2 "SwtVertSts1_Dwn" ;
VAL_ 1063 PassSeatSwtSts2PassSeatSwtHdrstH 0 "SwtHozlSts1_Idle" 1 "SwtHozlSts1_Fwd" 2 "SwtHozlSts1_Backw" ;
VAL_ 1063 PassSeatSwtSts2PassSeatSwtHdrstV 0 "SwtVertSts1_Idle" 1 "SwtVertSts1_Up" 2 "SwtVertSts1_Dwn" ;
VAL_ 1063 PassSeatSwtSts2PassSeatSwtHeiFrn 0 "SwtVertSts1_Idle" 1 "SwtVertSts1_Up" 2 "SwtVertSts1_Dwn" ;
VAL_ 1063 PassSeatSwtSts2PassSeatSwtHeiSts 0 "SwtVertSts1_Idle" 1 "SwtVertSts1_Up" 2 "SwtVertSts1_Dwn" ;
VAL_ 1063 PassSeatSwtSts2PassSeatSwtInclSt 0 "SwtHozlSts1_Idle" 1 "SwtHozlSts1_Fwd" 2 "SwtHozlSts1_Backw" ;
VAL_ 1063 PassSeatSwtSts2PassSeatSwtSelnOf 0 "SwtVertSts1_Idle" 1 "SwtVertSts1_Up" 2 "SwtVertSts1_Dwn" ;
VAL_ 1063 PassSeatSwtSts2PassSeatSwtSldSts 0 "SwtHozlSts1_Idle" 1 "SwtHozlSts1_Fwd" 2 "SwtHozlSts1_Backw" ;
VAL_ 1063 PassSeatVentAvlSts 0 "StsFd_None" 1 "StsFd_On" 2 "StsFd_Off" 3 "StsFd_Error" 4 "StsFd_Functionallimit" 5 "StsFd_Energylimit" 6 "StsFd_Resvd1" 7 "StsFd_Resvd2" ;
VAL_ 1063 PassSeatVentnLvlSts 0 "SeatClimaLvl_Off" 1 "SeatClimaLvl_Lvl1" 2 "SeatClimaLvl_Lvl2" 3 "SeatClimaLvl_Lvl3" ;
VAL_ 1063 RowFrstPassODSSts 0 "OccptPresSt1_Undefd1" 1 "OccptPresSt1_OccptNotPrsnt" 2 "OccptPresSt1_OccptPrsnt" 3 "OccptPresSt1_Undefd2" ;
VAL_ 538 PassSeatActvSwtFctMod 0 "SwtFctMod_Mod1" 1 "SwtFctMod_Mod2" 2 "SwtFctMod_Mod3" 3 "SwtFctMod_Mod4" ;
VAL_ 538 PassSeatIntgrSwtStsIntgrSwtHozlS 0 "SwtHozlSts1_Idle" 1 "SwtHozlSts1_Fwd" 2 "SwtHozlSts1_Backw" ;
VAL_ 538 PassSeatIntgrSwtStsIntgrSwtRotSt 0 "SwtHozlSts1_Idle" 1 "SwtHozlSts1_Fwd" 2 "SwtHozlSts1_Backw" ;
VAL_ 538 PassSeatIntgrSwtStsIntgrSwtSelnS 0 "SwtVertSts1_Idle" 1 "SwtVertSts1_Up" 2 "SwtVertSts1_Dwn" ;
VAL_ 538 PassSeatIntgrSwtStsIntgrSwtVertS 0 "SwtVertSts1_Idle" 1 "SwtVertSts1_Up" 2 "SwtVertSts1_Dwn" ;
VAL_ 538 PassSeatSwtBlstrSts 0 "SwtHozlSts1_Idle" 1 "SwtHozlSts1_Fwd" 2 "SwtHozlSts1_Backw" ;
VAL_ 538 PassSeatSwtCushExtSts 0 "SwtHozlSts1_Idle" 1 "SwtHozlSts1_Fwd" 2 "SwtHozlSts1_Backw" ;
VAL_ 1363 VFCVectorSMPVFCid0 0 "VFCOnOff_Off" 1 "VFCOnOff_On" ;
VAL_ 1363 VFCVectorSMPVFCid1 0 "VFCOnOff_Off" 1 "VFCOnOff_On" ;
VAL_ 1363 VFCVectorSMPVFCid10 0 "VFCOnOff_Off" 1 "VFCOnOff_On" ;
VAL_ 1363 VFCVectorSMPVFCid11 0 "VFCOnOff_Off" 1 "VFCOnOff_On" ;
VAL_ 1363 VFCVectorSMPVFCid12 0 "VFCOnOff_Off" 1 "VFCOnOff_On" ;
VAL_ 1363 VFCVectorSMPVFCid13 0 "VFCOnOff_Off" 1 "VFCOnOff_On" ;
VAL_ 1363 VFCVectorSMPVFCid14 0 "VFCOnOff_Off" 1 "VFCOnOff_On" ;
VAL_ 1363 VFCVectorSMPVFCid15 0 "VFCOnOff_Off" 1 "VFCOnOff_On" ;
VAL_ 1363 VFCVectorSMPVFCid16 0 "VFCOnOff_Off" 1 "VFCOnOff_On" ;
VAL_ 1363 VFCVectorSMPVFCid17 0 "VFCOnOff_Off" 1 "VFCOnOff_On" ;
VAL_ 1363 VFCVectorSMPVFCid18 0 "VFCOnOff_Off" 1 "VFCOnOff_On" ;
VAL_ 1363 VFCVectorSMPVFCid19 0 "VFCOnOff_Off" 1 "VFCOnOff_On" ;
VAL_ 1363 VFCVectorSMPVFCid2 0 "VFCOnOff_Off" 1 "VFCOnOff_On" ;
VAL_ 1363 VFCVectorSMPVFCid20 0 "VFCOnOff_Off" 1 "VFCOnOff_On" ;
VAL_ 1363 VFCVectorSMPVFCid21 0 "VFCOnOff_Off" 1 "VFCOnOff_On" ;
VAL_ 1363 VFCVectorSMPVFCid22 0 "VFCOnOff_Off" 1 "VFCOnOff_On" ;
VAL_ 1363 VFCVectorSMPVFCid23 0 "VFCOnOff_Off" 1 "VFCOnOff_On" ;
VAL_ 1363 VFCVectorSMPVFCid24 0 "VFCOnOff_Off" 1 "VFCOnOff_On" ;
VAL_ 1363 VFCVectorSMPVFCid25 0 "VFCOnOff_Off" 1 "VFCOnOff_On" ;
VAL_ 1363 VFCVectorSMPVFCid26 0 "VFCOnOff_Off" 1 "VFCOnOff_On" ;
VAL_ 1363 VFCVectorSMPVFCid27 0 "VFCOnOff_Off" 1 "VFCOnOff_On" ;
VAL_ 1363 VFCVectorSMPVFCid28 0 "VFCOnOff_Off" 1 "VFCOnOff_On" ;
VAL_ 1363 VFCVectorSMPVFCid29 0 "VFCOnOff_Off" 1 "VFCOnOff_On" ;
VAL_ 1363 VFCVectorSMPVFCid3 0 "VFCOnOff_Off" 1 "VFCOnOff_On" ;
VAL_ 1363 VFCVectorSMPVFCid30 0 "VFCOnOff_Off" 1 "VFCOnOff_On" ;
VAL_ 1363 VFCVectorSMPVFCid31 0 "VFCOnOff_Off" 1 "VFCOnOff_On" ;
VAL_ 1363 VFCVectorSMPVFCid32 0 "VFCOnOff_Off" 1 "VFCOnOff_On" ;
VAL_ 1363 VFCVectorSMPVFCid33 0 "VFCOnOff_Off" 1 "VFCOnOff_On" ;
VAL_ 1363 VFCVectorSMPVFCid34 0 "VFCOnOff_Off" 1 "VFCOnOff_On" ;
VAL_ 1363 VFCVectorSMPVFCid35 0 "VFCOnOff_Off" 1 "VFCOnOff_On" ;
VAL_ 1363 VFCVectorSMPVFCid36 0 "VFCOnOff_Off" 1 "VFCOnOff_On" ;
VAL_ 1363 VFCVectorSMPVFCid37 0 "VFCOnOff_Off" 1 "VFCOnOff_On" ;
VAL_ 1363 VFCVectorSMPVFCid38 0 "VFCOnOff_Off" 1 "VFCOnOff_On" ;
VAL_ 1363 VFCVectorSMPVFCid39 0 "VFCOnOff_Off" 1 "VFCOnOff_On" ;
VAL_ 1363 VFCVectorSMPVFCid4 0 "VFCOnOff_Off" 1 "VFCOnOff_On" ;
VAL_ 1363 VFCVectorSMPVFCid40 0 "VFCOnOff_Off" 1 "VFCOnOff_On" ;
VAL_ 1363 VFCVectorSMPVFCid41 0 "VFCOnOff_Off" 1 "VFCOnOff_On" ;
VAL_ 1363 VFCVectorSMPVFCid42 0 "VFCOnOff_Off" 1 "VFCOnOff_On" ;
VAL_ 1363 VFCVectorSMPVFCid43 0 "VFCOnOff_Off" 1 "VFCOnOff_On" ;
VAL_ 1363 VFCVectorSMPVFCid44 0 "VFCOnOff_Off" 1 "VFCOnOff_On" ;
VAL_ 1363 VFCVectorSMPVFCid45 0 "VFCOnOff_Off" 1 "VFCOnOff_On" ;
VAL_ 1363 VFCVectorSMPVFCid46 0 "VFCOnOff_Off" 1 "VFCOnOff_On" ;
VAL_ 1363 VFCVectorSMPVFCid47 0 "VFCOnOff_Off" 1 "VFCOnOff_On" ;
VAL_ 1363 VFCVectorSMPVFCid48 0 "VFCOnOff_Off" 1 "VFCOnOff_On" ;
VAL_ 1363 VFCVectorSMPVFCid49 0 "VFCOnOff_Off" 1 "VFCOnOff_On" ;
VAL_ 1363 VFCVectorSMPVFCid5 0 "VFCOnOff_Off" 1 "VFCOnOff_On" ;
VAL_ 1363 VFCVectorSMPVFCid50 0 "VFCOnOff_Off" 1 "VFCOnOff_On" ;
VAL_ 1363 VFCVectorSMPVFCid51 0 "VFCOnOff_Off" 1 "VFCOnOff_On" ;
VAL_ 1363 VFCVectorSMPVFCid52 0 "VFCOnOff_Off" 1 "VFCOnOff_On" ;
VAL_ 1363 VFCVectorSMPVFCid53 0 "VFCOnOff_Off" 1 "VFCOnOff_On" ;
VAL_ 1363 VFCVectorSMPVFCid54 0 "VFCOnOff_Off" 1 "VFCOnOff_On" ;
VAL_ 1363 VFCVectorSMPVFCid55 0 "VFCOnOff_Off" 1 "VFCOnOff_On" ;
VAL_ 1363 VFCVectorSMPVFCid56 0 "VFCOnOff_Off" 1 "VFCOnOff_On" ;
VAL_ 1363 VFCVectorSMPVFCid57 0 "VFCOnOff_Off" 1 "VFCOnOff_On" ;
VAL_ 1363 VFCVectorSMPVFCid58 0 "VFCOnOff_Off" 1 "VFCOnOff_On" ;
VAL_ 1363 VFCVectorSMPVFCid59 0 "VFCOnOff_Off" 1 "VFCOnOff_On" ;
VAL_ 1363 VFCVectorSMPVFCid6 0 "VFCOnOff_Off" 1 "VFCOnOff_On" ;
VAL_ 1363 VFCVectorSMPVFCid60 0 "VFCOnOff_Off" 1 "VFCOnOff_On" ;
VAL_ 1363 VFCVectorSMPVFCid61 0 "VFCOnOff_Off" 1 "VFCOnOff_On" ;
VAL_ 1363 VFCVectorSMPVFCid7 0 "VFCOnOff_Off" 1 "VFCOnOff_On" ;
VAL_ 1363 VFCVectorSMPVFCid8 0 "VFCOnOff_Off" 1 "VFCOnOff_On" ;
VAL_ 1363 VFCVectorSMPVFCid9 0 "VFCOnOff_Off" 1 "VFCOnOff_On" ;
VAL_ 208 TrlrFogLiSts 0 "OnOff1_Off" 1 "OnOff1_On" ;
VAL_ 208 TrlrLampActvtChk 0 "TrlrLampChkSts1_TrlrLampChkNotAvl" 1 "TrlrLampChkSts1_TrlrLampChkAvl" ;
VAL_ 208 TrlrLampChkSts 0 "TrlrLampChkSts2_Idle" 1 "TrlrLampChkSts2_TrlrLampChkStrtd" 2 "TrlrLampChkSts2_TrlrLampChkCmpl" 3 "TrlrLampChkSts2_CnclOper" 4 "TrlrLampChkSts2_TrlrLampEngOffReqd" 5 "TrlrLampChkSts2_Resd1" 6 "TrlrLampChkSts2_Resd2" 7 "TrlrLampChkSts2_Resd3" ;
VAL_ 208 TrlrLeIndcrFltSts 0 "DevErrSts2_NoFlt" 1 "DevErrSts2_Flt" ;
VAL_ 208 TrlrLiFltSts 0 "LampFailrSts1_LampNoFailr" 1 "LampFailrSts1_LampIndcrTurnRiFailr" 2 "LampFailrSts1_LampIndcrTurnLeFailr" 3 "LampFailrSts1_LampIndcrTurnLeAndRiFailr" 4 "LampFailrSts1_BrkLampFailr" 5 "LampFailrSts1_BrkLampAndIndcrTurnRiFailr" 6 "LampFailrSts1_BrkLampAndIndcrTurnLeFailr" 7 "LampFailrSts1_BrkAndIndcrTurnAllFailr" ;
VAL_ 208 TrlrPrmntPwrActv 0 "YesNo1_Yes" 1 "YesNo1_No" ;
VAL_ 208 TrlrPrsnt 0 "TrlrPrsntSts_TrlrNotPrsnt" 1 "TrlrPrsntSts_TrlrPrsnt" ;
VAL_ 208 TrlrRiIndcrFltSts 0 "DevErrSts2_NoFlt" 1 "DevErrSts2_Flt" ;
VAL_ 208 TrlrSrvReq 0 "DevErrSts2_NoFlt" 1 "DevErrSts2_Flt" ;
VAL_ 145 TrlrBrkLiSts 0 "OnOff1_Off" 1 "OnOff1_On" ;
VAL_ 145 TrlrIndcrTurnSts 0 "IndcrSts1_Off" 1 "IndcrSts1_LeOn" 2 "IndcrSts1_RiOn" 3 "IndcrSts1_LeAndRiOn" ;
VAL_ 145 TrlrPosnLiSts 0 "OnOff1_Off" 1 "OnOff1_On" ;
VAL_ 145 TrlrRvsgLiSts 0 "OnOff1_Off" 1 "OnOff1_On" ;
VAL_ 145 TwbrLockdPosn 0 "TwbrLockdPosn_Ukwn" 1 "TwbrLockdPosn_Unlckd" 2 "TwbrLockdPosn_Insdlockd" 3 "TwbrLockdPosn_Outdlockd" ;
VAL_ 145 TwbrWarnStsYesNo 0 "YesNoRes_Resd1" 1 "YesNoRes_Yes" 2 "YesNoRes_No" 3 "YesNoRes_Resd2" ;
VAL_ 1365 VFCVectorTRMVFCid0 0 "VFCOnOff_Off" 1 "VFCOnOff_On" ;
VAL_ 1365 VFCVectorTRMVFCid1 0 "VFCOnOff_Off" 1 "VFCOnOff_On" ;
VAL_ 1365 VFCVectorTRMVFCid10 0 "VFCOnOff_Off" 1 "VFCOnOff_On" ;
VAL_ 1365 VFCVectorTRMVFCid11 0 "VFCOnOff_Off" 1 "VFCOnOff_On" ;
VAL_ 1365 VFCVectorTRMVFCid12 0 "VFCOnOff_Off" 1 "VFCOnOff_On" ;
VAL_ 1365 VFCVectorTRMVFCid13 0 "VFCOnOff_Off" 1 "VFCOnOff_On" ;
VAL_ 1365 VFCVectorTRMVFCid14 0 "VFCOnOff_Off" 1 "VFCOnOff_On" ;
VAL_ 1365 VFCVectorTRMVFCid15 0 "VFCOnOff_Off" 1 "VFCOnOff_On" ;
VAL_ 1365 VFCVectorTRMVFCid16 0 "VFCOnOff_Off" 1 "VFCOnOff_On" ;
VAL_ 1365 VFCVectorTRMVFCid17 0 "VFCOnOff_Off" 1 "VFCOnOff_On" ;
VAL_ 1365 VFCVectorTRMVFCid18 0 "VFCOnOff_Off" 1 "VFCOnOff_On" ;
VAL_ 1365 VFCVectorTRMVFCid19 0 "VFCOnOff_Off" 1 "VFCOnOff_On" ;
VAL_ 1365 VFCVectorTRMVFCid2 0 "VFCOnOff_Off" 1 "VFCOnOff_On" ;
VAL_ 1365 VFCVectorTRMVFCid20 0 "VFCOnOff_Off" 1 "VFCOnOff_On" ;
VAL_ 1365 VFCVectorTRMVFCid21 0 "VFCOnOff_Off" 1 "VFCOnOff_On" ;
VAL_ 1365 VFCVectorTRMVFCid22 0 "VFCOnOff_Off" 1 "VFCOnOff_On" ;
VAL_ 1365 VFCVectorTRMVFCid23 0 "VFCOnOff_Off" 1 "VFCOnOff_On" ;
VAL_ 1365 VFCVectorTRMVFCid24 0 "VFCOnOff_Off" 1 "VFCOnOff_On" ;
VAL_ 1365 VFCVectorTRMVFCid25 0 "VFCOnOff_Off" 1 "VFCOnOff_On" ;
VAL_ 1365 VFCVectorTRMVFCid26 0 "VFCOnOff_Off" 1 "VFCOnOff_On" ;
VAL_ 1365 VFCVectorTRMVFCid27 0 "VFCOnOff_Off" 1 "VFCOnOff_On" ;
VAL_ 1365 VFCVectorTRMVFCid28 0 "VFCOnOff_Off" 1 "VFCOnOff_On" ;
VAL_ 1365 VFCVectorTRMVFCid29 0 "VFCOnOff_Off" 1 "VFCOnOff_On" ;
VAL_ 1365 VFCVectorTRMVFCid3 0 "VFCOnOff_Off" 1 "VFCOnOff_On" ;
VAL_ 1365 VFCVectorTRMVFCid30 0 "VFCOnOff_Off" 1 "VFCOnOff_On" ;
VAL_ 1365 VFCVectorTRMVFCid31 0 "VFCOnOff_Off" 1 "VFCOnOff_On" ;
VAL_ 1365 VFCVectorTRMVFCid32 0 "VFCOnOff_Off" 1 "VFCOnOff_On" ;
VAL_ 1365 VFCVectorTRMVFCid33 0 "VFCOnOff_Off" 1 "VFCOnOff_On" ;
VAL_ 1365 VFCVectorTRMVFCid34 0 "VFCOnOff_Off" 1 "VFCOnOff_On" ;
VAL_ 1365 VFCVectorTRMVFCid35 0 "VFCOnOff_Off" 1 "VFCOnOff_On" ;
VAL_ 1365 VFCVectorTRMVFCid36 0 "VFCOnOff_Off" 1 "VFCOnOff_On" ;
VAL_ 1365 VFCVectorTRMVFCid37 0 "VFCOnOff_Off" 1 "VFCOnOff_On" ;
VAL_ 1365 VFCVectorTRMVFCid38 0 "VFCOnOff_Off" 1 "VFCOnOff_On" ;
VAL_ 1365 VFCVectorTRMVFCid39 0 "VFCOnOff_Off" 1 "VFCOnOff_On" ;
VAL_ 1365 VFCVectorTRMVFCid4 0 "VFCOnOff_Off" 1 "VFCOnOff_On" ;
VAL_ 1365 VFCVectorTRMVFCid40 0 "VFCOnOff_Off" 1 "VFCOnOff_On" ;
VAL_ 1365 VFCVectorTRMVFCid41 0 "VFCOnOff_Off" 1 "VFCOnOff_On" ;
VAL_ 1365 VFCVectorTRMVFCid42 0 "VFCOnOff_Off" 1 "VFCOnOff_On" ;
VAL_ 1365 VFCVectorTRMVFCid43 0 "VFCOnOff_Off" 1 "VFCOnOff_On" ;
VAL_ 1365 VFCVectorTRMVFCid44 0 "VFCOnOff_Off" 1 "VFCOnOff_On" ;
VAL_ 1365 VFCVectorTRMVFCid45 0 "VFCOnOff_Off" 1 "VFCOnOff_On" ;
VAL_ 1365 VFCVectorTRMVFCid46 0 "VFCOnOff_Off" 1 "VFCOnOff_On" ;
VAL_ 1365 VFCVectorTRMVFCid47 0 "VFCOnOff_Off" 1 "VFCOnOff_On" ;
VAL_ 1365 VFCVectorTRMVFCid48 0 "VFCOnOff_Off" 1 "VFCOnOff_On" ;
VAL_ 1365 VFCVectorTRMVFCid49 0 "VFCOnOff_Off" 1 "VFCOnOff_On" ;
VAL_ 1365 VFCVectorTRMVFCid5 0 "VFCOnOff_Off" 1 "VFCOnOff_On" ;
VAL_ 1365 VFCVectorTRMVFCid50 0 "VFCOnOff_Off" 1 "VFCOnOff_On" ;
VAL_ 1365 VFCVectorTRMVFCid51 0 "VFCOnOff_Off" 1 "VFCOnOff_On" ;
VAL_ 1365 VFCVectorTRMVFCid52 0 "VFCOnOff_Off" 1 "VFCOnOff_On" ;
VAL_ 1365 VFCVectorTRMVFCid53 0 "VFCOnOff_Off" 1 "VFCOnOff_On" ;
VAL_ 1365 VFCVectorTRMVFCid54 0 "VFCOnOff_Off" 1 "VFCOnOff_On" ;
VAL_ 1365 VFCVectorTRMVFCid55 0 "VFCOnOff_Off" 1 "VFCOnOff_On" ;
VAL_ 1365 VFCVectorTRMVFCid56 0 "VFCOnOff_Off" 1 "VFCOnOff_On" ;
VAL_ 1365 VFCVectorTRMVFCid57 0 "VFCOnOff_Off" 1 "VFCOnOff_On" ;
VAL_ 1365 VFCVectorTRMVFCid58 0 "VFCOnOff_Off" 1 "VFCOnOff_On" ;
VAL_ 1365 VFCVectorTRMVFCid59 0 "VFCOnOff_Off" 1 "VFCOnOff_On" ;
VAL_ 1365 VFCVectorTRMVFCid6 0 "VFCOnOff_Off" 1 "VFCOnOff_On" ;
VAL_ 1365 VFCVectorTRMVFCid60 0 "VFCOnOff_Off" 1 "VFCOnOff_On" ;
VAL_ 1365 VFCVectorTRMVFCid61 0 "VFCOnOff_Off" 1 "VFCOnOff_On" ;
VAL_ 1365 VFCVectorTRMVFCid7 0 "VFCOnOff_Off" 1 "VFCOnOff_On" ;
VAL_ 1365 VFCVectorTRMVFCid8 0 "VFCOnOff_Off" 1 "VFCOnOff_On" ;
VAL_ 1365 VFCVectorTRMVFCid9 0 "VFCOnOff_Off" 1 "VFCOnOff_On" ;
SIG_GROUP_ 112 DoorLeReCinhIntFailInf 1 : DoorLeReCinhIntFailInfCinchFlt1 DoorLeReCinhIntFailInfCinchRestF;
SIG_GROUP_ 112 DoorLeReHndlHMISts 1 : DoorLeReHndlHMIStsDeployedOverTm DoorLeReHndlHMIStsReserved1 DoorLeReHndlHMIStsRetractOverTmd DoorLeReHndlHMIStsUnsScsHallSnsr;
SIG_GROUP_ 112 DoorLeReRelsFail 1 : DoorLeReRelsFailCinchOverTimed DoorLeReRelsFailFailure1 DoorLeReRelsFailMechRels;
SIG_GROUP_ 112 PassSeatRemCtrlReDoorLe 1 : PassSeatRemCtrlReDoorLeActrIncSt PassSeatRemCtrlReDoorLeActrSldSt;
SIG_GROUP_ 1353 VFCVectorRLDM 1 : VFCVectorRLDMBlockID VFCVectorRLDMVFCid0 VFCVectorRLDMVFCid1 VFCVectorRLDMVFCid10 VFCVectorRLDMVFCid11 VFCVectorRLDMVFCid12 VFCVectorRLDMVFCid13 VFCVectorRLDMVFCid14 VFCVectorRLDMVFCid15 VFCVectorRLDMVFCid16 VFCVectorRLDMVFCid17 VFCVectorRLDMVFCid18 VFCVectorRLDMVFCid19 VFCVectorRLDMVFCid2 VFCVectorRLDMVFCid20 VFCVectorRLDMVFCid21 VFCVectorRLDMVFCid22 VFCVectorRLDMVFCid23 VFCVectorRLDMVFCid24 VFCVectorRLDMVFCid25 VFCVectorRLDMVFCid26 VFCVectorRLDMVFCid27 VFCVectorRLDMVFCid28 VFCVectorRLDMVFCid29 VFCVectorRLDMVFCid3 VFCVectorRLDMVFCid30 VFCVectorRLDMVFCid31 VFCVectorRLDMVFCid32 VFCVectorRLDMVFCid33 VFCVectorRLDMVFCid34 VFCVectorRLDMVFCid35 VFCVectorRLDMVFCid36 VFCVectorRLDMVFCid37 VFCVectorRLDMVFCid38 VFCVectorRLDMVFCid39 VFCVectorRLDMVFCid4 VFCVectorRLDMVFCid40 VFCVectorRLDMVFCid41 VFCVectorRLDMVFCid42 VFCVectorRLDMVFCid43 VFCVectorRLDMVFCid44 VFCVectorRLDMVFCid45 VFCVectorRLDMVFCid46 VFCVectorRLDMVFCid47 VFCVectorRLDMVFCid48 VFCVectorRLDMVFCid49 VFCVectorRLDMVFCid5 VFCVectorRLDMVFCid50 VFCVectorRLDMVFCid51 VFCVectorRLDMVFCid52 VFCVectorRLDMVFCid53 VFCVectorRLDMVFCid54 VFCVectorRLDMVFCid55 VFCVectorRLDMVFCid56 VFCVectorRLDMVFCid57 VFCVectorRLDMVFCid58 VFCVectorRLDMVFCid59 VFCVectorRLDMVFCid6 VFCVectorRLDMVFCid60 VFCVectorRLDMVFCid61 VFCVectorRLDMVFCid7 VFCVectorRLDMVFCid8 VFCVectorRLDMVFCid9;
SIG_GROUP_ 117 DoorRiReCinhIntFailInf 1 : DoorRiReCinhIntFailInfCinchFlt1 DoorRiReCinhIntFailInfCinchRestF;
SIG_GROUP_ 117 DoorRiReHndlHMISts 1 : DoorRiReHndlHMIStsDeployedOverTm DoorRiReHndlHMIStsReserved1 DoorRiReHndlHMIStsRetractOverTmd DoorRiReHndlHMIStsUnsScsHallSnsr;
SIG_GROUP_ 117 DoorRiReRelsFail 1 : DoorRiReRelsFailCinchOverTimed DoorRiReRelsFailFailure1 DoorRiReRelsFailMechRels;
SIG_GROUP_ 117 PassSeatRemCtrlReDoorRi 1 : PassSeatRemCtrlReDoorRiActrIncSt PassSeatRemCtrlReDoorRiActrSldSt;
SIG_GROUP_ 1360 VFCVectorRRDM 1 : VFCVectorRRDMBlockID VFCVectorRRDMVFCid0 VFCVectorRRDMVFCid1 VFCVectorRRDMVFCid10 VFCVectorRRDMVFCid11 VFCVectorRRDMVFCid12 VFCVectorRRDMVFCid13 VFCVectorRRDMVFCid14 VFCVectorRRDMVFCid15 VFCVectorRRDMVFCid16 VFCVectorRRDMVFCid17 VFCVectorRRDMVFCid18 VFCVectorRRDMVFCid19 VFCVectorRRDMVFCid2 VFCVectorRRDMVFCid20 VFCVectorRRDMVFCid21 VFCVectorRRDMVFCid22 VFCVectorRRDMVFCid23 VFCVectorRRDMVFCid24 VFCVectorRRDMVFCid25 VFCVectorRRDMVFCid26 VFCVectorRRDMVFCid27 VFCVectorRRDMVFCid28 VFCVectorRRDMVFCid29 VFCVectorRRDMVFCid3 VFCVectorRRDMVFCid30 VFCVectorRRDMVFCid31 VFCVectorRRDMVFCid32 VFCVectorRRDMVFCid33 VFCVectorRRDMVFCid34 VFCVectorRRDMVFCid35 VFCVectorRRDMVFCid36 VFCVectorRRDMVFCid37 VFCVectorRRDMVFCid38 VFCVectorRRDMVFCid39 VFCVectorRRDMVFCid4 VFCVectorRRDMVFCid40 VFCVectorRRDMVFCid41 VFCVectorRRDMVFCid42 VFCVectorRRDMVFCid43 VFCVectorRRDMVFCid44 VFCVectorRRDMVFCid45 VFCVectorRRDMVFCid46 VFCVectorRRDMVFCid47 VFCVectorRRDMVFCid48 VFCVectorRRDMVFCid49 VFCVectorRRDMVFCid5 VFCVectorRRDMVFCid50 VFCVectorRRDMVFCid51 VFCVectorRRDMVFCid52 VFCVectorRRDMVFCid53 VFCVectorRRDMVFCid54 VFCVectorRRDMVFCid55 VFCVectorRRDMVFCid56 VFCVectorRRDMVFCid57 VFCVectorRRDMVFCid58 VFCVectorRRDMVFCid59 VFCVectorRRDMVFCid6 VFCVectorRRDMVFCid60 VFCVectorRRDMVFCid61 VFCVectorRRDMVFCid7 VFCVectorRRDMVFCid8 VFCVectorRRDMVFCid9;
SIG_GROUP_ 1430 SMDdevelpsignalgroupresp 1 : SMDdevelpsignalgrouprespFunction SMDdevelpsignalgrouprespFun_0000 SMDdevelpsignalgrouprespFun_0001 SMDdevelpsignalgrouprespFun_0002 SMDdevelpsignalgrouprespFun_0003 SMDdevelpsignalgrouprespFun_0004 SMDdevelpsignalgrouprespFun_0005 SMDdevelpsignalgrouprespFun_0006;
SIG_GROUP_ 864 DrvrSeatHallPosExtUpld 1 : DrvrSeatHallPosExtUpldSeatCushEx DrvrSeatHallPosExtUpldSeatHeadrH DrvrSeatHallPosExtUpldSeatHeadrV;
SIG_GROUP_ 1193 DrvrSeatHallPosUpld 1 : DrvrSeatHallPosUpldSeatFrntHeiPo DrvrSeatHallPosUpldSeatHeiPos DrvrSeatHallPosUpldSeatInclPos DrvrSeatHallPosUpldSeatSldPos;
SIG_GROUP_ 665 DrvrSeatSwtSts 1 : DrvrSeatSwtStsDrvrSeatSwtAdjmtOf DrvrSeatSwtStsDrvrSeatSwtAd_0000 DrvrSeatSwtStsDrvrSeatSwtHdrstHo DrvrSeatSwtStsDrvrSeatSwtHdrstVe DrvrSeatSwtStsDrvrSeatSwtHeiFrnt DrvrSeatSwtStsDrvrSeatSwtHeiSts DrvrSeatSwtStsDrvrSeatSwtInclSts DrvrSeatSwtStsDrvrSeatSwtSelnOfS DrvrSeatSwtStsDrvrSeatSwtSldSts;
SIG_GROUP_ 272 DrvrSeatPosPerc 1 : DrvrSeatPosPercSeatPosFrntHeiPer DrvrSeatPosPercSeatPosFrntHeiQF DrvrSeatPosPercSeatPosHeiPerc DrvrSeatPosPercSeatPosHeiQF DrvrSeatPosPercSeatPosSldPerc DrvrSeatPosPercSeatPosSldQF;
SIG_GROUP_ 547 DrvrSeatIntgrSwtSts 1 : DrvrSeatIntgrSwtStsIntgrSwtHozlS DrvrSeatIntgrSwtStsIntgrSwtRotSt DrvrSeatIntgrSwtStsIntgrSwtSelnS DrvrSeatIntgrSwtStsIntgrSwtVertS;
SIG_GROUP_ 547 DrvrSeatPivtPosPerc 1 : DrvrSeatPivtPosPercSeatPosPerc DrvrSeatPivtPosPercSeatPosQf;
SIG_GROUP_ 1362 VFCVectorSMD 1 : VFCVectorSMDBlockID VFCVectorSMDVFCid0 VFCVectorSMDVFCid1 VFCVectorSMDVFCid10 VFCVectorSMDVFCid11 VFCVectorSMDVFCid12 VFCVectorSMDVFCid13 VFCVectorSMDVFCid14 VFCVectorSMDVFCid15 VFCVectorSMDVFCid16 VFCVectorSMDVFCid17 VFCVectorSMDVFCid18 VFCVectorSMDVFCid19 VFCVectorSMDVFCid2 VFCVectorSMDVFCid20 VFCVectorSMDVFCid21 VFCVectorSMDVFCid22 VFCVectorSMDVFCid23 VFCVectorSMDVFCid24 VFCVectorSMDVFCid25 VFCVectorSMDVFCid26 VFCVectorSMDVFCid27 VFCVectorSMDVFCid28 VFCVectorSMDVFCid29 VFCVectorSMDVFCid3 VFCVectorSMDVFCid30 VFCVectorSMDVFCid31 VFCVectorSMDVFCid32 VFCVectorSMDVFCid33 VFCVectorSMDVFCid34 VFCVectorSMDVFCid35 VFCVectorSMDVFCid36 VFCVectorSMDVFCid37 VFCVectorSMDVFCid38 VFCVectorSMDVFCid39 VFCVectorSMDVFCid4 VFCVectorSMDVFCid40 VFCVectorSMDVFCid41 VFCVectorSMDVFCid42 VFCVectorSMDVFCid43 VFCVectorSMDVFCid44 VFCVectorSMDVFCid45 VFCVectorSMDVFCid46 VFCVectorSMDVFCid47 VFCVectorSMDVFCid48 VFCVectorSMDVFCid49 VFCVectorSMDVFCid5 VFCVectorSMDVFCid50 VFCVectorSMDVFCid51 VFCVectorSMDVFCid52 VFCVectorSMDVFCid53 VFCVectorSMDVFCid54 VFCVectorSMDVFCid55 VFCVectorSMDVFCid56 VFCVectorSMDVFCid57 VFCVectorSMDVFCid58 VFCVectorSMDVFCid59 VFCVectorSMDVFCid6 VFCVectorSMDVFCid60 VFCVectorSMDVFCid61 VFCVectorSMDVFCid7 VFCVectorSMDVFCid8 VFCVectorSMDVFCid9;
SIG_GROUP_ 1431 SMPdevelpsignalgroupresp 1 : SMPdevelpsignalgrouprespFunction SMPdevelpsignalgrouprespFun_0000 SMPdevelpsignalgrouprespFun_0001 SMPdevelpsignalgrouprespFun_0002 SMPdevelpsignalgrouprespFun_0003 SMPdevelpsignalgrouprespFun_0004 SMPdevelpsignalgrouprespFun_0005 SMPdevelpsignalgrouprespFun_0006;
SIG_GROUP_ 275 PassSeatPosPerc 1 : PassSeatPosPercSeatPosFrntHeiPer PassSeatPosPercSeatPosFrntHeiQF PassSeatPosPercSeatPosHeiPerc PassSeatPosPercSeatPosHeiQF PassSeatPosPercSeatPosSldPerc PassSeatPosPercSeatPosSldQF;
SIG_GROUP_ 1063 PassSeatPivtPosPerc 1 : PassSeatPivtPosPercSeatPosPerc PassSeatPivtPosPercSeatPosQf;
SIG_GROUP_ 1063 PassSeatSwtSts2 1 : PassSeatSwtSts2PassSeatSwtAdjmtO PassSeatSwtSts2PassSeatSwtA_0000 PassSeatSwtSts2PassSeatSwtHdrstH PassSeatSwtSts2PassSeatSwtHdrstV PassSeatSwtSts2PassSeatSwtHeiFrn PassSeatSwtSts2PassSeatSwtHeiSts PassSeatSwtSts2PassSeatSwtInclSt PassSeatSwtSts2PassSeatSwtSelnOf PassSeatSwtSts2PassSeatSwtSldSts;
SIG_GROUP_ 538 PassSeatIntgrSwtSts 1 : PassSeatIntgrSwtStsIntgrSwtHozlS PassSeatIntgrSwtStsIntgrSwtRotSt PassSeatIntgrSwtStsIntgrSwtSelnS PassSeatIntgrSwtStsIntgrSwtVertS;
SIG_GROUP_ 1363 VFCVectorSMP 1 : VFCVectorSMPBlockID VFCVectorSMPVFCid0 VFCVectorSMPVFCid1 VFCVectorSMPVFCid10 VFCVectorSMPVFCid11 VFCVectorSMPVFCid12 VFCVectorSMPVFCid13 VFCVectorSMPVFCid14 VFCVectorSMPVFCid15 VFCVectorSMPVFCid16 VFCVectorSMPVFCid17 VFCVectorSMPVFCid18 VFCVectorSMPVFCid19 VFCVectorSMPVFCid2 VFCVectorSMPVFCid20 VFCVectorSMPVFCid21 VFCVectorSMPVFCid22 VFCVectorSMPVFCid23 VFCVectorSMPVFCid24 VFCVectorSMPVFCid25 VFCVectorSMPVFCid26 VFCVectorSMPVFCid27 VFCVectorSMPVFCid28 VFCVectorSMPVFCid29 VFCVectorSMPVFCid3 VFCVectorSMPVFCid30 VFCVectorSMPVFCid31 VFCVectorSMPVFCid32 VFCVectorSMPVFCid33 VFCVectorSMPVFCid34 VFCVectorSMPVFCid35 VFCVectorSMPVFCid36 VFCVectorSMPVFCid37 VFCVectorSMPVFCid38 VFCVectorSMPVFCid39 VFCVectorSMPVFCid4 VFCVectorSMPVFCid40 VFCVectorSMPVFCid41 VFCVectorSMPVFCid42 VFCVectorSMPVFCid43 VFCVectorSMPVFCid44 VFCVectorSMPVFCid45 VFCVectorSMPVFCid46 VFCVectorSMPVFCid47 VFCVectorSMPVFCid48 VFCVectorSMPVFCid49 VFCVectorSMPVFCid5 VFCVectorSMPVFCid50 VFCVectorSMPVFCid51 VFCVectorSMPVFCid52 VFCVectorSMPVFCid53 VFCVectorSMPVFCid54 VFCVectorSMPVFCid55 VFCVectorSMPVFCid56 VFCVectorSMPVFCid57 VFCVectorSMPVFCid58 VFCVectorSMPVFCid59 VFCVectorSMPVFCid6 VFCVectorSMPVFCid60 VFCVectorSMPVFCid61 VFCVectorSMPVFCid7 VFCVectorSMPVFCid8 VFCVectorSMPVFCid9;
SIG_GROUP_ 145 TwbrWarnSts 1 : TwbrWarnStsChks TwbrWarnStsCntr TwbrWarnStsYesNo;
SIG_GROUP_ 1365 VFCVectorTRM 1 : VFCVectorTRMBlockID VFCVectorTRMVFCid0 VFCVectorTRMVFCid1 VFCVectorTRMVFCid10 VFCVectorTRMVFCid11 VFCVectorTRMVFCid12 VFCVectorTRMVFCid13 VFCVectorTRMVFCid14 VFCVectorTRMVFCid15 VFCVectorTRMVFCid16 VFCVectorTRMVFCid17 VFCVectorTRMVFCid18 VFCVectorTRMVFCid19 VFCVectorTRMVFCid2 VFCVectorTRMVFCid20 VFCVectorTRMVFCid21 VFCVectorTRMVFCid22 VFCVectorTRMVFCid23 VFCVectorTRMVFCid24 VFCVectorTRMVFCid25 VFCVectorTRMVFCid26 VFCVectorTRMVFCid27 VFCVectorTRMVFCid28 VFCVectorTRMVFCid29 VFCVectorTRMVFCid3 VFCVectorTRMVFCid30 VFCVectorTRMVFCid31 VFCVectorTRMVFCid32 VFCVectorTRMVFCid33 VFCVectorTRMVFCid34 VFCVectorTRMVFCid35 VFCVectorTRMVFCid36 VFCVectorTRMVFCid37 VFCVectorTRMVFCid38 VFCVectorTRMVFCid39 VFCVectorTRMVFCid4 VFCVectorTRMVFCid40 VFCVectorTRMVFCid41 VFCVectorTRMVFCid42 VFCVectorTRMVFCid43 VFCVectorTRMVFCid44 VFCVectorTRMVFCid45 VFCVectorTRMVFCid46 VFCVectorTRMVFCid47 VFCVectorTRMVFCid48 VFCVectorTRMVFCid49 VFCVectorTRMVFCid5 VFCVectorTRMVFCid50 VFCVectorTRMVFCid51 VFCVectorTRMVFCid52 VFCVectorTRMVFCid53 VFCVectorTRMVFCid54 VFCVectorTRMVFCid55 VFCVectorTRMVFCid56 VFCVectorTRMVFCid57 VFCVectorTRMVFCid58 VFCVectorTRMVFCid59 VFCVectorTRMVFCid6 VFCVectorTRMVFCid60 VFCVectorTRMVFCid61 VFCVectorTRMVFCid7 VFCVectorTRMVFCid8 VFCVectorTRMVFCid9;
